VERSION "HNNBNNNYNNNNNNNNNNNNNNNNNNNNNNNNNNNNNNNNNN/4/%%%/4/'%**4NNN///"

NS_ :

BS_:

BU_: Frontradar Frontsensorik

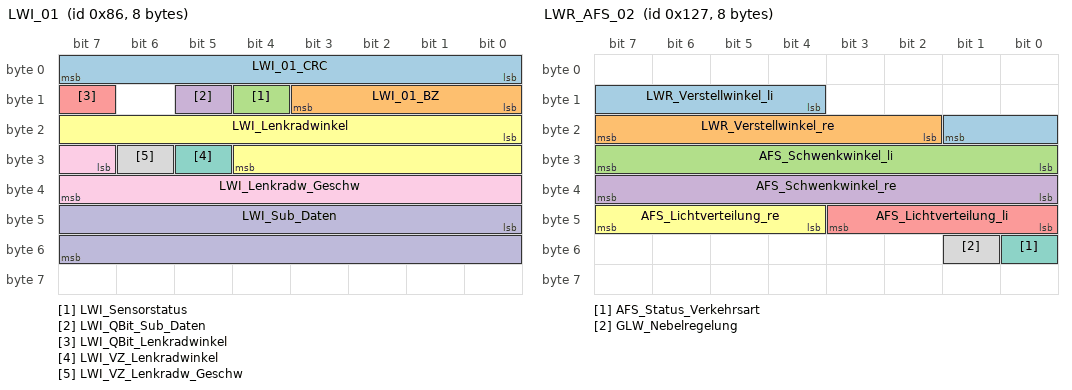
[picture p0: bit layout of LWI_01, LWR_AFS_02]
BO_ 134 LWI_01: 8 Vector__XXX
 SG_ LWI_01_CRC : 0|8@1+ (1,0) [0|255] ""  Frontradar,Frontsensorik
 SG_ LWI_01_BZ : 8|4@1+ (1,0) [0|15] ""  Frontradar,Frontsensorik
 SG_ LWI_Sensorstatus : 12|1@1+ (1,0) [0|1] ""  Frontradar,Frontsensorik
 SG_ LWI_QBit_Sub_Daten : 13|1@1+ (1,0) [0|1] "" Vector__XXX
 SG_ LWI_QBit_Lenkradwinkel : 15|1@1+ (1,0) [0|1] ""  Frontradar,Frontsensorik
 SG_ LWI_Lenkradwinkel : 16|13@1+ (0.1,0) [0|800] "Unit_DegreOfArc"  Frontradar,Frontsensorik
 SG_ LWI_VZ_Lenkradwinkel : 29|1@1+ (1,0) [0|1] ""  Frontradar,Frontsensorik
 SG_ LWI_VZ_Lenkradw_Geschw : 30|1@1+ (1,0) [0|1] ""  Frontradar
 SG_ LWI_Lenkradw_Geschw : 31|9@1+ (5,0) [0|2500] "Unit_DegreOfArcPerSecon"  Frontradar
 SG_ LWI_Sub_Daten : 40|16@1+ (1,0) [0|65535] "" Vector__XXX

BO_ 917 LWR_AFS_01: 8 Vector__XXX
 SG_ AFS_Abbiegelicht_li_Anf : 0|1@1+ (1,0) [0|1] "" Vector__XXX
 SG_ AFS_Abbiegelicht_re_Anf : 1|1@1+ (1,0) [0|1] "" Vector__XXX
 SG_ AFS_Abbiegelicht_Dimm_Anf : 2|1@1+ (1,0) [0|1] "" Vector__XXX
 SG_ AFS_Verfuegbarkeit_GLW : 3|1@1+ (1,0) [0|1] "" Vector__XXX
 SG_ AFS_Status_adaptive_LV : 4|1@1+ (1,0) [0|1] "" Vector__XXX
 SG_ AFS_Fernlicht_li_defekt : 5|1@1+ (1,0) [0|1] "" Vector__XXX
 SG_ AFS_Fernlicht_re_defekt : 6|1@1+ (1,0) [0|1] "" Vector__XXX
 SG_ AFS_Fernlicht_Status : 7|1@1+ (1,0) [0|1] "" Vector__XXX
 SG_ LWR_AFS_01_BZ : 8|4@1+ (1,0) [0|15] "" Vector__XXX
 SG_ AFS_Lampe : 12|1@1+ (1,0) [0|1] "" Vector__XXX
 SG_ LWR_Lampe : 13|1@1+ (1,0) [0|1] "" Vector__XXX
 SG_ AFS_Fehlertext : 14|1@1+ (1,0) [0|1] "" Vector__XXX
 SG_ AFS_LED_Blinkmode : 15|1@1+ (1,0) [0|1] "" Vector__XXX
 SG_ LWR_Touristenmodus_aktiv : 16|1@1+ (1,0) [0|1] "" Vector__XXX
 SG_ AFS_Charisma_FahrPr : 17|4@1+ (1,0) [0|15] "" Vector__XXX
 SG_ AFS_Charisma_Status : 21|2@1+ (1,0) [0|3] "" Vector__XXX
 SG_ AFS_Allwetterlicht : 24|1@1+ (1,0) [0|1] "" Vector__XXX
 SG_ LWR_Touristenmodus_verbaut : 25|1@1+ (1,0) [0|1] "" Vector__XXX
 SG_ AFS_adaptive_LV_verbaut : 26|1@1+ (1,0) [0|1] "" Vector__XXX
 SG_ LWR_Reisemodus_Texte : 27|2@1+ (1,0) [0|3] "" Vector__XXX
 SG_ GLW_Sensor_blockiert : 29|1@1+ (1,0) [0|1] "" Vector__XXX
 SG_ LWR_Pos_Schrittmotor : 32|8@1+ (0.4,0) [0|100] "Unit_PerCent" Vector__XXX
 SG_ LWR_Hoehenwert_VL : 40|8@1+ (1,-127) [-127|126] "" Vector__XXX
 SG_ LWR_Hoehenwert_HL : 48|8@1+ (1,-127) [-127|126] "" Vector__XXX
 SG_ AFS_Ersatzlicht_Links : 56|1@1+ (1,0) [0|1] "" Vector__XXX
 SG_ AFS_Ersatzlicht_Rechts : 57|1@1+ (1,0) [0|1] "" Vector__XXX
 SG_ LWR_AFS_Grundeinstellung : 58|1@1+ (1,0) [0|1] "" Vector__XXX
 SG_ LWR_AFS_Parametrisierung : 59|1@1+ (1,0) [0|1] "" Vector__XXX
 SG_ LWR_Initialisierungslauf : 60|1@1+ (1,0) [0|1] "" Vector__XXX
 SG_ LWR_Sicherheitsposition : 61|1@1+ (1,0) [0|1] "" Vector__XXX
 SG_ LWR_Modus : 62|1@1+ (1,0) [0|1] "" Vector__XXX

BO_ 295 LWR_AFS_02: 8 Vector__XXX
 SG_ LWR_Verstellwinkel_li : 12|6@1+ (0.125,-3) [-3|3] "Unit_DegreOfArc"  Frontsensorik
 SG_ LWR_Verstellwinkel_re : 18|6@1+ (0.125,-3) [-3|3] "Unit_DegreOfArc"  Frontsensorik
 SG_ AFS_Schwenkwinkel_li : 24|8@1+ (0.125,-7.5) [-7.5|15] "Unit_DegreOfArc"  Frontsensorik
 SG_ AFS_Schwenkwinkel_re : 32|8@1+ (0.125,-15) [-15|7.5] "Unit_DegreOfArc"  Frontsensorik
 SG_ AFS_Lichtverteilung_li : 40|4@1+ (1,0) [0|15] ""  Frontsensorik
 SG_ AFS_Lichtverteilung_re : 44|4@1+ (1,0) [0|15] ""  Frontsensorik
 SG_ AFS_Status_Verkehrsart : 48|1@1+ (1,0) [0|1] ""  Frontsensorik
 SG_ GLW_Nebelregelung : 49|1@1+ (1,0) [0|1] ""  Frontsensorik

BO_ 846 LWR_AFS_03: 8 Vector__XXX
 SG_ MXB_Status_Seg01 : 0|2@1+ (1,0) [0|3] ""  Frontsensorik
 SG_ MXB_Status_Seg02 : 2|2@1+ (1,0) [0|3] ""  Frontsensorik
 SG_ MXB_Status_Seg03 : 4|2@1+ (1,0) [0|3] ""  Frontsensorik
 SG_ MXB_Status_Seg04 : 6|2@1+ (1,0) [0|3] ""  Frontsensorik
 SG_ MXB_Status_Seg05 : 8|2@1+ (1,0) [0|3] ""  Frontsensorik
 SG_ MXB_Status_Seg06 : 10|2@1+ (1,0) [0|3] ""  Frontsensorik
 SG_ MXB_Status_Seg07 : 12|2@1+ (1,0) [0|3] ""  Frontsensorik
 SG_ MXB_Status_Seg08 : 14|2@1+ (1,0) [0|3] ""  Frontsensorik
 SG_ MXB_Status_Seg09 : 16|2@1+ (1,0) [0|3] ""  Frontsensorik
 SG_ MXB_Status_Seg10 : 18|2@1+ (1,0) [0|3] ""  Frontsensorik
 SG_ MXB_Status_Seg11 : 20|2@1+ (1,0) [0|3] ""  Frontsensorik
 SG_ MXB_Status_Seg12 : 22|2@1+ (1,0) [0|3] ""  Frontsensorik
 SG_ MXB_Status_Seg13 : 24|2@1+ (1,0) [0|3] ""  Frontsensorik
 SG_ MXB_Status_Seg14 : 26|2@1+ (1,0) [0|3] ""  Frontsensorik
 SG_ MXB_Status_Seg15 : 28|2@1+ (1,0) [0|3] ""  Frontsensorik
 SG_ MXB_Status_Seg16 : 30|2@1+ (1,0) [0|3] ""  Frontsensorik
 SG_ MXB_Status_Seg17 : 32|2@1+ (1,0) [0|3] ""  Frontsensorik
 SG_ MXB_Status_Seg18 : 34|2@1+ (1,0) [0|3] ""  Frontsensorik
 SG_ MXB_Status_Seg19 : 36|2@1+ (1,0) [0|3] ""  Frontsensorik
 SG_ MXB_Status_Seg20 : 38|2@1+ (1,0) [0|3] ""  Frontsensorik
 SG_ MXB_Status_Seg21 : 40|2@1+ (1,0) [0|3] ""  Frontsensorik
 SG_ MXB_Status_Seg22 : 42|2@1+ (1,0) [0|3] ""  Frontsensorik
 SG_ MXB_Status_Seg23 : 44|2@1+ (1,0) [0|3] ""  Frontsensorik
 SG_ MXB_Status_Seg24 : 46|2@1+ (1,0) [0|3] ""  Frontsensorik
 SG_ MXB_Status_Seg25 : 48|2@1+ (1,0) [0|3] ""  Frontsensorik
 SG_ MXB_Status_Seg26 : 50|2@1+ (1,0) [0|3] ""  Frontsensorik
 SG_ MXB_Status_Seg27 : 52|2@1+ (1,0) [0|3] ""  Frontsensorik
 SG_ MXB_Status_Seg28 : 54|2@1+ (1,0) [0|3] ""  Frontsensorik
 SG_ MXB_Status_Seg29 : 56|2@1+ (1,0) [0|3] ""  Frontsensorik
 SG_ MXB_Status_Seg30 : 58|2@1+ (1,0) [0|3] ""  Frontsensorik
 SG_ MXB_Status_Seg31 : 60|2@1+ (1,0) [0|3] ""  Frontsensorik
 SG_ MXB_Status_Seg32 : 62|2@1+ (1,0) [0|3] ""  Frontsensorik

BO_ 847 LWR_AFS_04: 8 Vector__XXX
 SG_ MXB_Status_Seg33 : 0|2@1+ (1,0) [0|3] ""  Frontsensorik
 SG_ MXB_Status_Seg34 : 2|2@1+ (1,0) [0|3] ""  Frontsensorik
 SG_ MXB_Status_Seg35 : 4|2@1+ (1,0) [0|3] ""  Frontsensorik
 SG_ MXB_Status_Seg36 : 6|2@1+ (1,0) [0|3] ""  Frontsensorik
 SG_ MXB_Status_Seg37 : 8|2@1+ (1,0) [0|3] ""  Frontsensorik
 SG_ MXB_Status_Seg38 : 10|2@1+ (1,0) [0|3] ""  Frontsensorik
 SG_ MXB_Status_Seg39 : 12|2@1+ (1,0) [0|3] ""  Frontsensorik
 SG_ MXB_Status_Seg40 : 14|2@1+ (1,0) [0|3] ""  Frontsensorik
 SG_ MXB_Status_Seg41 : 16|2@1+ (1,0) [0|3] ""  Frontsensorik
 SG_ MXB_Status_Seg42 : 18|2@1+ (1,0) [0|3] ""  Frontsensorik
 SG_ MXB_Status_Seg43 : 20|2@1+ (1,0) [0|3] ""  Frontsensorik
 SG_ MXB_Status_Seg44 : 22|2@1+ (1,0) [0|3] ""  Frontsensorik
 SG_ MXB_Status_Seg45 : 24|2@1+ (1,0) [0|3] ""  Frontsensorik
 SG_ MXB_Status_Seg46 : 26|2@1+ (1,0) [0|3] ""  Frontsensorik
 SG_ MXB_Status_Seg47 : 28|2@1+ (1,0) [0|3] ""  Frontsensorik
 SG_ MXB_Status_Seg48 : 30|2@1+ (1,0) [0|3] ""  Frontsensorik
 SG_ MXB_Status_Seg49 : 32|2@1+ (1,0) [0|3] ""  Frontsensorik
 SG_ MXB_Status_Seg50 : 34|2@1+ (1,0) [0|3] ""  Frontsensorik
 SG_ MXB_Status_Seg51 : 36|2@1+ (1,0) [0|3] ""  Frontsensorik
 SG_ MXB_Status_Seg52 : 38|2@1+ (1,0) [0|3] ""  Frontsensorik
 SG_ MXB_Status_Seg53 : 40|2@1+ (1,0) [0|3] ""  Frontsensorik
 SG_ MXB_Status_Seg54 : 42|2@1+ (1,0) [0|3] ""  Frontsensorik
 SG_ MXB_Status_Seg55 : 44|2@1+ (1,0) [0|3] ""  Frontsensorik
 SG_ MXB_Status_Seg56 : 46|2@1+ (1,0) [0|3] ""  Frontsensorik
 SG_ MXB_Status_Seg57 : 48|2@1+ (1,0) [0|3] ""  Frontsensorik
 SG_ MXB_Status_Seg58 : 50|2@1+ (1,0) [0|3] ""  Frontsensorik
 SG_ MXB_Status_Seg59 : 52|2@1+ (1,0) [0|3] ""  Frontsensorik
 SG_ MXB_Status_Seg60 : 54|2@1+ (1,0) [0|3] ""  Frontsensorik

BO_ 1721 LWR_AFS_05: 8 Vector__XXX
 SG_ MXB_horiz_Offset_li_SW : 0|7@1+ (0.05,-3.15) [-3.15|3.2] "Unit_DegreOfArc"  Frontsensorik
 SG_ MXB_Status : 7|2@1+ (1,0) [0|3] ""  Frontsensorik
 SG_ MXB_vert_Offset_li_SW : 9|7@1+ (0.05,-3.15) [-3.15|3.2] "Unit_DegreOfArc"  Frontsensorik
 SG_ AFS_Abblendlicht_li_defekt : 16|1@1+ (1,0) [0|1] "" Vector__XXX
 SG_ AFS_Abblendlicht_re_defekt : 17|1@1+ (1,0) [0|1] "" Vector__XXX
 SG_ AFS_stat_Kurvenlicht_li_defekt : 18|1@1+ (1,0) [0|1] "" Vector__XXX
 SG_ AFS_stat_Kurvenlicht_re_defekt : 19|1@1+ (1,0) [0|1] "" Vector__XXX
 SG_ AFS_Tagfahrlicht_li_defekt : 20|1@1+ (1,0) [0|1] "" Vector__XXX
 SG_ AFS_Tagfahrlicht_re_defekt : 21|1@1+ (1,0) [0|1] "" Vector__XXX
 SG_ MXB_Allgemein_li_defekt : 22|1@1+ (1,0) [0|1] "" Vector__XXX
 SG_ MXB_Allgemein_re_defekt : 23|1@1+ (1,0) [0|1] "" Vector__XXX
 SG_ AFS_Zusatzfernlicht_li_defekt : 24|1@1+ (1,0) [0|1] "" Vector__XXX
 SG_ AFS_Zusatzfernlicht_re_defekt : 25|1@1+ (1,0) [0|1] "" Vector__XXX
 SG_ LED_Steuerung_li_defekt : 26|1@1+ (1,0) [0|1] "" Vector__XXX
 SG_ LED_Steuerung_re_defekt : 27|1@1+ (1,0) [0|1] "" Vector__XXX
 SG_ MXB_horiz_Offset_re_SW : 28|7@1+ (0.05,-3.15) [-3.15|3.2] "Unit_DegreOfArc"  Frontsensorik
 SG_ MXB_vert_Offset_re_SW : 35|7@1+ (0.05,-3.15) [-3.15|3.2] "Unit_DegreOfArc"  Frontsensorik

BO_ 506 LWR_AFS_08: 8 Vector__XXX
 SG_ LCM_TFL_Fehler_L : 12|1@1+ (1,0) [0|1] "" Vector__XXX
 SG_ LCM_TFL_Fehler_R : 13|1@1+ (1,0) [0|1] "" Vector__XXX
 SG_ LCM_SM_Fehler_L : 14|1@1+ (1,0) [0|1] "" Vector__XXX
 SG_ LCM_SM_Fehler_R : 15|1@1+ (1,0) [0|1] "" Vector__XXX
 SG_ LCM_Shutter_Fehler_L : 16|1@1+ (1,0) [0|1] "" Vector__XXX
 SG_ LCM_Shutter_Fehler_R : 17|1@1+ (1,0) [0|1] "" Vector__XXX
 SG_ LCM_PO_Fehler_L : 18|1@1+ (1,0) [0|1] "" Vector__XXX
 SG_ LCM_PO_Fehler_R : 19|1@1+ (1,0) [0|1] "" Vector__XXX
 SG_ LCM_Blinker_Fehler_L : 20|1@1+ (1,0) [0|1] "" Vector__XXX
 SG_ LCM_Blinker_Fehler_R : 21|1@1+ (1,0) [0|1] "" Vector__XXX
 SG_ LCM_Blinker_L_Sta : 22|1@1+ (1,0) [0|1] "" Vector__XXX
 SG_ LCM_Blinker_R_Sta : 23|1@1+ (1,0) [0|1] "" Vector__XXX
 SG_ LCM_Datensatz_Fehler_L : 24|1@1+ (1,0) [0|1] "" Vector__XXX
 SG_ LCM_Datensatz_Fehler_R : 25|1@1+ (1,0) [0|1] "" Vector__XXX
 SG_ LCM_Abschaltbestaetigung_L : 26|2@1+ (1,0) [0|3] "" Vector__XXX
 SG_ LCM_Abschaltbestaetigung_R : 28|2@1+ (1,0) [0|3] "" Vector__XXX
 SG_ LCM_Sta_LM_L_alt : 60|1@1+ (1,0) [0|1] "" Vector__XXX
 SG_ LCM_Sta_LM_R_alt : 61|1@1+ (1,0) [0|1] "" Vector__XXX
 SG_ LCM_Feh_LM_L_alt : 62|1@1+ (1,0) [0|1] "" Vector__XXX
 SG_ LCM_Feh_LM_R_alt : 63|1@1+ (1,0) [0|1] "" Vector__XXX

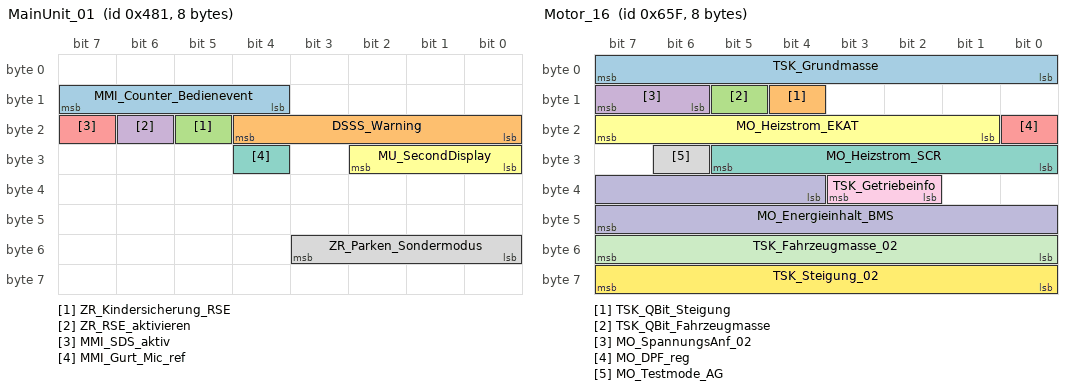
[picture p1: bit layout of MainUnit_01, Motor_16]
BO_ 1153 MainUnit_01: 8 Vector__XXX
 SG_ MMI_Counter_Bedienevent : 12|4@1+ (1,0) [0|15] ""  Frontsensorik
 SG_ DSSS_Warning : 16|5@1+ (1,0) [0|31] "" Vector__XXX
 SG_ ZR_Kindersicherung_RSE : 21|1@1+ (1,0) [0|1] "" Vector__XXX
 SG_ ZR_RSE_aktivieren : 22|1@1+ (1,0) [0|1] "" Vector__XXX
 SG_ MMI_SDS_aktiv : 23|1@1+ (1,0) [0|1] "" Vector__XXX
 SG_ MU_SecondDisplay : 24|3@1+ (1,0) [0|7] "" Vector__XXX
 SG_ MMI_Gurt_Mic_ref : 28|1@1+ (1,0) [0|1] "" Vector__XXX
 SG_ ZR_Parken_Sondermodus : 48|4@1+ (1,0) [0|15] "" Vector__XXX

BO_ 1600 Motor_07: 8 Vector__XXX
 SG_ MO_QBit_Ansaugluft_Temp : 0|1@1+ (1,0) [0|1] "" Vector__XXX
 SG_ MO_QBit_Oel_Temp : 1|1@1+ (1,0) [0|1] "" Vector__XXX
 SG_ MO_QBit_Kuehlmittel_Temp : 2|1@1+ (1,0) [0|1] "" Vector__XXX
 SG_ MO_KL15_Abschaltempfehlung : 3|1@1+ (1,0) [0|1] "" Vector__XXX
 SG_ MO_HYB_Fehler_HV_Netz : 4|1@1+ (1,0) [0|1] "" Vector__XXX
 SG_ MO_aktives_Getriebeheizen : 5|1@1+ (1,0) [0|1] "" Vector__XXX
 SG_ MO_Absperrventil_oeffnen : 6|2@1+ (1,0) [0|3] "" Vector__XXX
 SG_ MO_Ansaugluft_Temp : 8|8@1+ (0.75,-48) [-48|141.75] "Unit_DegreCelsi" Vector__XXX
 SG_ MO_Oel_Temp : 16|8@1+ (1,-60) [-60|192] "Unit_DegreCelsi" Vector__XXX
 SG_ MO_Kuehlmittel_Temp : 24|8@1+ (0.75,-48) [-48|141.75] "Unit_DegreCelsi" Vector__XXX
 SG_ MO_Hoeheninfo : 32|8@1+ (0.00781,0) [0|1.98374] "" Vector__XXX
 SG_ MO_Kennfeldk : 40|1@1+ (1,0) [0|1] "" Vector__XXX
 SG_ MO_Versionsinfo_02 : 41|5@1+ (1,0) [0|31] "" Vector__XXX
 SG_ MO_QBit_Hoeheninfo : 46|1@1+ (1,0) [0|1] "" Vector__XXX
 SG_ MO_Getriebe_kuehlen : 47|1@1+ (1,0) [0|1] "" Vector__XXX
 SG_ MO_Mom_Traegheit_02 : 48|5@1+ (0.01,0) [0|0.31] "Unit_KiloGramMeterSquar" Vector__XXX
 SG_ MO_Heizungspumpenansteuerung : 53|4@1+ (10,0) [0|100] "Unit_PerCent" Vector__XXX
 SG_ MO_SpannungsAnf : 57|1@1+ (1,0) [0|1] "" Vector__XXX
 SG_ MO_Nachlaufzeit_Heizungspumpe : 58|6@1+ (15,0) [0|945] "Unit_Secon" Vector__XXX

BO_ 958 Motor_14: 8 Vector__XXX
 SG_ Motor_14_CRC : 0|8@1+ (1,0) [0|255] "" Vector__XXX
 SG_ Motor_14_BZ : 8|4@1+ (1,0) [0|15] "" Vector__XXX
 SG_ MO_StartStopp_Status : 12|2@1+ (1,0) [0|3] ""  Frontradar
 SG_ MO_StartStopp_Wiederstart : 14|1@1+ (1,0) [0|1] ""  Frontradar
 SG_ MO_StartStopp_Motorstopp : 15|1@1+ (1,0) [0|1] ""  Frontradar
 SG_ MO_Freig_Reku : 16|2@1+ (1,0) [0|3] "" Vector__XXX
 SG_ MO_Kl_75 : 18|1@1+ (1,0) [0|1] ""  Frontradar
 SG_ MO_Kl_50 : 19|1@1+ (1,0) [0|1] ""  Frontradar
 SG_ MO_Gangposition : 20|4@1+ (1,0) [0|15] ""  Frontradar
 SG_ MO_StartStopp_Fahrerwunsch : 24|2@1+ (1,0) [0|3] "" Vector__XXX
 SG_ MO_HYB_Fahrbereitschaft : 26|1@1+ (1,0) [0|1] "" Vector__XXX
 SG_ MO_Ext_E_Fahrt_aktiv : 27|1@1+ (1,0) [0|1] ""  Frontradar
 SG_ MO_Fahrer_bremst : 28|1@1+ (1,0) [0|1] ""  Frontradar
 SG_ MO_QBit_Fahrer_bremst : 29|1@1+ (1,0) [0|1] ""  Frontradar
 SG_ MO_BLS : 30|1@1+ (1,0) [0|1] ""  Frontradar
 SG_ MO_Konsistenz_Bremsped : 31|1@1+ (1,0) [0|1] "" Vector__XXX
 SG_ MO_Timeout_ESP : 32|1@1+ (1,0) [0|1] "" Vector__XXX
 SG_ MO_Klima_Eingr : 33|2@1+ (1,0) [0|3] "" Vector__XXX
 SG_ MO_Aussp_Anlass : 35|1@1+ (1,0) [0|1] "" Vector__XXX
 SG_ MO_Freig_Anlass : 36|1@1+ (1,0) [0|1] "" Vector__XXX
 SG_ MO_Kuppl_schalter : 37|1@1+ (1,0) [0|1] ""  Frontradar
 SG_ MO_Interlock : 38|1@1+ (1,0) [0|1] "" Vector__XXX
 SG_ MO_Motor_laeuft : 39|1@1+ (1,0) [0|1] ""  Frontsensorik
 SG_ MO_Kickdown : 40|1@1+ (1,0) [0|1] "" Vector__XXX
 SG_ MO_QBit_KL_75 : 41|1@1+ (1,0) [0|1] "" Vector__XXX
 SG_ MO_EKlKomLeiRed : 42|2@1+ (1,0) [0|3] "" Vector__XXX
 SG_ MO_Handshake_STH : 44|1@1+ (1,0) [0|1] "" Vector__XXX
 SG_ MO_BKV_Unterdruckwarnung : 45|1@1+ (1,0) [0|1] "" Vector__XXX
 SG_ MO_Freigabe_Segeln : 46|1@1+ (1,0) [0|1] "" Vector__XXX
 SG_ MO_PTC_Status : 47|3@1+ (1,0) [0|7] "" Vector__XXX
 SG_ MO_QBit_Gangposition : 50|1@1+ (1,0) [0|1] ""  Frontradar
 SG_ MO_Signalquelle_Gangposition : 51|1@1+ (1,0) [0|1] "" Vector__XXX
 SG_ MO_Remotestart_Betrieb : 52|1@1+ (1,0) [0|1] "" Vector__XXX
 SG_ MO_Remotestart_moeglich : 53|1@1+ (1,0) [0|1] "" Vector__XXX
 SG_ MO_FMAus_aktiv : 55|1@1+ (1,0) [0|1] "" Vector__XXX
 SG_ MO_FMAus_Startvariante : 56|2@1+ (1,0) [0|3] "" Vector__XXX
 SG_ MO_BMS_NV_Anf_stuetzen : 58|1@1+ (1,0) [0|1] "" Vector__XXX
 SG_ MO_Zylinderabschaltung : 59|2@1+ (1,0) [0|3] "" Vector__XXX
 SG_ MO_HYB_VM_aktiv : 61|1@1+ (1,0) [0|1] "" Vector__XXX
 SG_ MO_StartVorauss_erfuellt : 62|2@1+ (1,0) [0|3] "" Vector__XXX

BO_ 1631 Motor_16: 8 Vector__XXX
 SG_ TSK_Grundmasse : 0|8@1+ (32,0) [0|8128] "Unit_KiloGram" Vector__XXX
 SG_ TSK_QBit_Steigung : 12|1@1+ (1,0) [0|1] ""  Frontradar
 SG_ TSK_QBit_Fahrzeugmasse : 13|1@1+ (1,0) [0|1] "" Vector__XXX
 SG_ MO_SpannungsAnf_02 : 14|2@1+ (1,0) [0|3] "" Vector__XXX
 SG_ MO_DPF_reg : 16|1@1+ (1,0) [0|1] "" Vector__XXX
 SG_ MO_Heizstrom_EKAT : 17|7@1+ (1,0) [0|126] "Unit_Amper" Vector__XXX
 SG_ MO_Heizstrom_SCR : 24|6@1+ (1,0) [0|62] "Unit_Amper" Vector__XXX
 SG_ MO_Testmode_AG : 30|1@1+ (1,0) [0|1] "" Vector__XXX
 SG_ TSK_Getriebeinfo : 34|2@1+ (1,0) [0|3] "" Vector__XXX
 SG_ MO_Energieinhalt_BMS : 36|12@1+ (25,0) [0|102325] "Unit_WattHour" Vector__XXX
 SG_ TSK_Fahrzeugmasse_02 : 48|8@1+ (32,0) [0|8128] "Unit_KiloGram"  Frontradar
 SG_ TSK_Steigung_02 : 56|8@1+ (0.8,-101.6) [-100.8|101.6] "Unit_PerCent"  Frontradar

BO_ 1648 Motor_18: 8 Vector__XXX
 SG_ MO_max_Ladedruck : 0|6@1+ (0.1,0) [0|6.3] "Unit_Bar" Vector__XXX
 SG_ MO_ANC_Kennfeld_Anf : 6|2@1+ (1,0) [0|3] "" Vector__XXX
 SG_ MO_Bremslicht_Reku : 8|1@1+ (1,0) [0|1] ""  Frontradar
 SG_ MO_StartStopp_PopUp : 9|2@1+ (1,0) [0|3] "" Vector__XXX
 SG_ MO1_Sperr_Info_WFS : 11|1@1+ (1,0) [0|1] "" Vector__XXX
 SG_ MO1_Freigabe_Info_WFS : 12|1@1+ (1,0) [0|1] "" Vector__XXX
 SG_ MO_EPCL : 13|3@1+ (1,0) [0|7] "" Vector__XXX
 SG_ MO_Zylabsch_Texte_02 : 16|4@1+ (1,0) [0|15] "" Vector__XXX
 SG_ MO_Fahrzeugtyp : 20|3@1+ (1,0) [0|7] ""  Frontradar
 SG_ MO_NMAX_Schaltanzeige : 23|9@1+ (25,0) [0|12775] "Unit_MinutInver" Vector__XXX
 SG_ MO_Abstellzeit : 32|8@1+ (8,0) [0|2024] "Unit_Minut" Vector__XXX
 SG_ MO_Abstellzeit_Status : 40|2@1+ (1,0) [0|3] "" Vector__XXX
 SG_ MO1_Freigabe_Verfallsinfo_WFS : 42|1@1+ (1,0) [0|1] "" Vector__XXX
 SG_ MO_Hybrid_StartStopp_LED : 43|2@1+ (1,0) [0|3] "" Vector__XXX
 SG_ MO_Fehler_Zylabsch : 45|2@1+ (1,0) [0|3] "" Vector__XXX
 SG_ MO_Anzahl_Abgesch_Zyl : 47|3@1+ (1,0) [0|7] "" Vector__XXX
 SG_ MO_Zylabsch_Texte : 50|2@1+ (1,0) [0|3] "" Vector__XXX
 SG_ MO_Ethanol_BS_Texte : 52|3@1+ (1,0) [0|7] "" Vector__XXX
 SG_ MO_Drehzahl_Warnung : 55|1@1+ (1,0) [0|1] "" Vector__XXX
 SG_ MO_obere_Drehzahlgrenze : 56|8@1+ (50,0) [50|12750] "Unit_MinutInver"  Frontradar

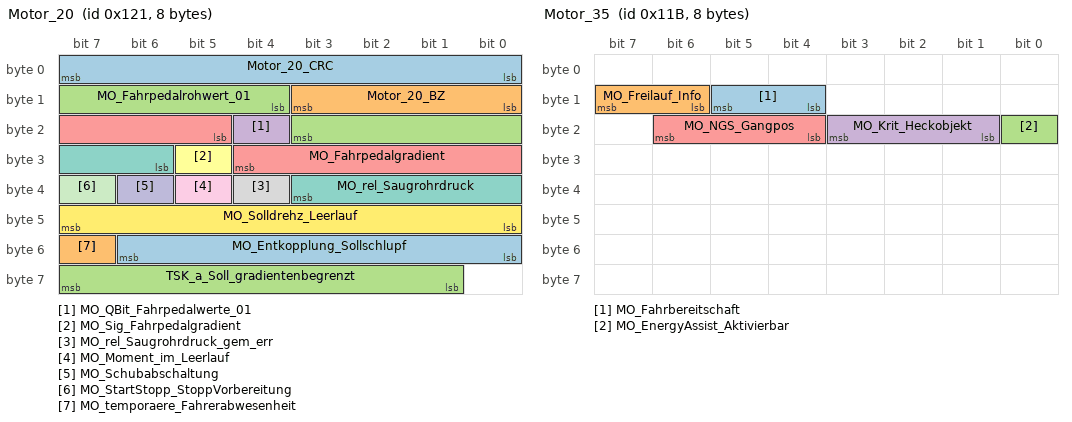
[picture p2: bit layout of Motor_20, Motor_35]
BO_ 289 Motor_20: 8 Vector__XXX
 SG_ Motor_20_CRC : 0|8@1+ (1,0) [0|255] ""  Frontradar
 SG_ Motor_20_BZ : 8|4@1+ (1,0) [0|15] ""  Frontradar
 SG_ MO_Fahrpedalrohwert_01 : 12|8@1+ (0.4,0) [0|101.6] "Unit_PerCent"  Frontradar
 SG_ MO_QBit_Fahrpedalwerte_01 : 20|1@1+ (1,0) [0|1] ""  Frontradar
 SG_ MO_Fahrpedalgradient : 21|8@1+ (25,0) [0|6350] "Unit_PerCentPerSecon" Vector__XXX
 SG_ MO_Sig_Fahrpedalgradient : 29|1@1+ (1,0) [0|1] ""  Frontradar
 SG_ MO_rel_Saugrohrdruck : 30|6@1+ (18,0) [0|1116] "Unit_MilliBar" Vector__XXX
 SG_ MO_rel_Saugrohrdruck_gem_err : 36|1@1+ (1,0) [0|1] "" Vector__XXX
 SG_ MO_Moment_im_Leerlauf : 37|1@1+ (1,0) [0|1] "" Vector__XXX
 SG_ MO_Schubabschaltung : 38|1@1+ (1,0) [0|1] "" Vector__XXX
 SG_ MO_StartStopp_StoppVorbereitung : 39|1@1+ (1,0) [0|1] "" Vector__XXX
 SG_ MO_Solldrehz_Leerlauf : 40|8@1+ (10,0) [0|2540] "Unit_MinutInver"  Frontradar
 SG_ MO_Entkopplung_Sollschlupf : 48|7@1+ (20,0) [0|2480] "Unit_MinutInver" Vector__XXX
 SG_ MO_temporaere_Fahrerabwesenheit : 55|1@1+ (1,0) [0|1] "" Vector__XXX
 SG_ TSK_a_Soll_gradientenbegrenzt : 57|7@1+ (0.1,-7.2) [-7.2|5.4] "Unit_MeterPerSeconSquar"  Frontradar

BO_ 283 Motor_35: 8 Vector__XXX
 SG_ MO_Fahrbereitschaft : 12|2@1+ (1,0) [0|3] ""  Frontradar
 SG_ MO_Freilauf_Info : 14|2@1+ (1,0) [0|3] "" Vector__XXX
 SG_ MO_EnergyAssist_Aktivierbar : 16|1@1+ (1,0) [0|1] "" Vector__XXX
 SG_ MO_Krit_Heckobjekt : 17|3@1+ (1,0) [0|7] "" Vector__XXX
 SG_ MO_NGS_Gangpos : 20|3@1+ (1,0) [0|7] "" Vector__XXX

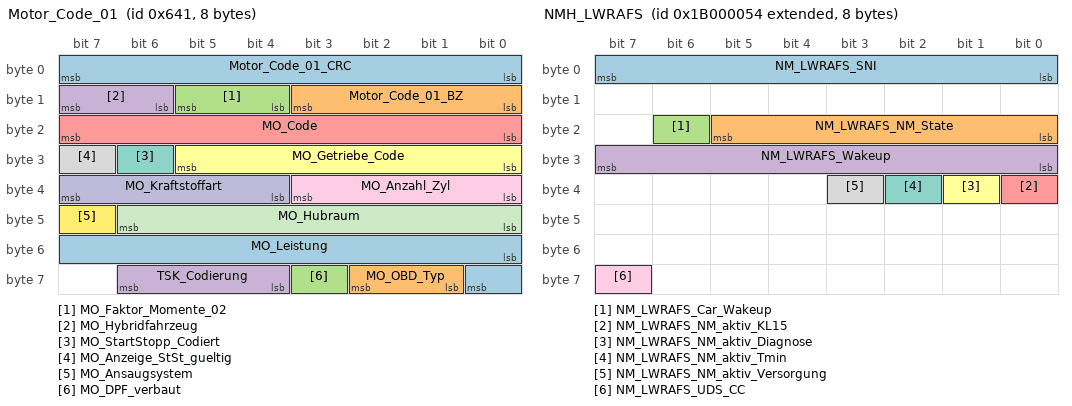
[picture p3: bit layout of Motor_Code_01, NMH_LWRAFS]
BO_ 1601 Motor_Code_01: 8 Vector__XXX
 SG_ Motor_Code_01_CRC : 0|8@1+ (1,0) [0|255] ""  Frontradar
 SG_ Motor_Code_01_BZ : 8|4@1+ (1,0) [0|15] ""  Frontradar
 SG_ MO_Faktor_Momente_02 : 12|2@1+ (1,0) [1|3] "Unit_NewtoMeter" Vector__XXX
 SG_ MO_Hybridfahrzeug : 14|2@1+ (1,0) [0|3] "" Vector__XXX
 SG_ MO_Code : 16|8@1+ (1,0) [0|255] "" Vector__XXX
 SG_ MO_Getriebe_Code : 24|6@1+ (1,0) [0|63] "" Vector__XXX
 SG_ MO_StartStopp_Codiert : 30|1@1+ (1,0) [0|1] "" Vector__XXX
 SG_ MO_Anzeige_StSt_gueltig : 31|1@1+ (1,0) [0|1] "" Vector__XXX
 SG_ MO_Anzahl_Zyl : 32|4@1+ (1,0) [0|15] "" Vector__XXX
 SG_ MO_Kraftstoffart : 36|4@1+ (1,0) [0|15] "" Vector__XXX
 SG_ MO_Hubraum : 40|7@1+ (0.1,0) [0|12.7] "Unit_Liter" Vector__XXX
 SG_ MO_Ansaugsystem : 47|1@1+ (1,0) [0|1] "" Vector__XXX
 SG_ MO_Leistung : 48|9@1+ (1,0) [0|511] "Unit_KiloWatt"  Frontradar
 SG_ MO_OBD_Typ : 57|2@1+ (1,0) [0|3] "" Vector__XXX
 SG_ MO_DPF_verbaut : 59|1@1+ (1,0) [0|1] "" Vector__XXX
 SG_ TSK_Codierung : 60|3@1+ (1,0) [0|7] ""  Frontradar

BO_ 2600468496 NMH_Gateway: 8 Vector__XXX
 SG_ NM_Gateway_SNI : 0|8@1+ (1,0) [0|255] "" Vector__XXX
 SG_ NM_Gateway_NM_State : 16|6@1+ (1,0) [0|63] "" Vector__XXX
 SG_ NM_Gateway_Car_Wakeup : 22|1@1+ (1,0) [0|1] "" Vector__XXX
 SG_ NM_Gateway_Wakeup : 24|8@1+ (1,0) [0|255] "" Vector__XXX
 SG_ NM_Gateway_NM_aktiv_KL15 : 32|1@1+ (1,0) [0|1] "" Vector__XXX
 SG_ NM_Gateway_NM_aktiv_Diagnose : 33|1@1+ (1,0) [0|1] "" Vector__XXX
 SG_ NM_Gateway_NM_aktiv_Tmin : 34|1@1+ (1,0) [0|1] "" Vector__XXX
 SG_ NM_Gateway_ACAN_Aktivitaet : 35|1@1+ (1,0) [0|1] "" Vector__XXX
 SG_ NM_Gateway_FCAN_Aktivitaet : 36|1@1+ (1,0) [0|1] "" Vector__XXX
 SG_ NM_Gateway_KCAN_Aktivitaet : 37|1@1+ (1,0) [0|1] "" Vector__XXX
 SG_ NM_Gateway_ICAN_Aktivitaet : 38|1@1+ (1,0) [0|1] "" Vector__XXX
 SG_ NM_Gateway_DiagCAN_Aktivitaet : 39|1@1+ (1,0) [0|1] "" Vector__XXX
 SG_ NM_Gateway_ECAN_Aktivitaet : 40|1@1+ (1,0) [0|1] "" Vector__XXX
 SG_ NM_Gateway_EnergieLIN_Aktivitaet : 41|1@1+ (1,0) [0|1] "" Vector__XXX
 SG_ NM_Gateway_Bedien_LIN_Aktivitaet : 42|1@1+ (1,0) [0|1] "" Vector__XXX
 SG_ NM_Gateway_EM_Aktivitaet : 43|1@1+ (1,0) [0|1] "" Vector__XXX
 SG_ NM_Gateway_KS_Aktivitaet : 44|1@1+ (1,0) [0|1] "" Vector__XXX
 SG_ NM_Gateway_HVEM_aktiv : 45|1@1+ (1,0) [0|1] "" Vector__XXX
 SG_ NM_Gateway_NL_EM : 48|1@1+ (1,0) [0|1] "" Vector__XXX
 SG_ NM_Gateway_NL_Shutdown : 49|1@1+ (1,0) [0|1] "" Vector__XXX
 SG_ NM_Gateway_NL_Spg_Messung : 50|1@1+ (1,0) [0|1] "" Vector__XXX
 SG_ NM_Gateway_NL_Wakeup_Monitor : 51|1@1+ (1,0) [0|1] "" Vector__XXX
 SG_ NM_Gateway_UDS_CC : 63|1@1+ (1,0) [0|1] "" Vector__XXX

BO_ 2600468564 NMH_LWRAFS: 8 Vector__XXX
 SG_ NM_LWRAFS_SNI : 0|8@1+ (1,0) [0|255] "" Vector__XXX
 SG_ NM_LWRAFS_NM_State : 16|6@1+ (1,0) [0|63] "" Vector__XXX
 SG_ NM_LWRAFS_Car_Wakeup : 22|1@1+ (1,0) [0|1] "" Vector__XXX
 SG_ NM_LWRAFS_Wakeup : 24|8@1+ (1,0) [0|255] "" Vector__XXX
 SG_ NM_LWRAFS_NM_aktiv_KL15 : 32|1@1+ (1,0) [0|1] "" Vector__XXX
 SG_ NM_LWRAFS_NM_aktiv_Diagnose : 33|1@1+ (1,0) [0|1] "" Vector__XXX
 SG_ NM_LWRAFS_NM_aktiv_Tmin : 34|1@1+ (1,0) [0|1] "" Vector__XXX
 SG_ NM_LWRAFS_NM_aktiv_Versorgung : 35|1@1+ (1,0) [0|1] "" Vector__XXX
 SG_ NM_LWRAFS_UDS_CC : 63|1@1+ (1,0) [0|1] "" Vector__XXX

BO_ 2549875287 OBDC_ACC_Req: 8 Vector__XXX
 SG_ OBDC_ACC_Req_Data : 0|64@1+ (1,0) [0|1.84467440737096E+019] ""  Frontradar

BO_ 2550006359 OBDC_ACC_Resp: 8 Frontradar
 SG_ OBDC_ACC_Resp_Data : 0|64@1+ (1,0) [0|1.84467440737096E+019] "" Vector__XXX

BO_ 2549875248 OBDC_FLA_Req: 8 Vector__XXX
 SG_ OBDC_FLA_Req_Data : 0|64@1+ (1,0) [0|1.84467440737096E+019] "" Vector__XXX

BO_ 2550006320 OBDC_FLA_Resp: 8 Vector__XXX
 SG_ OBDC_FLA_Resp_Data : 0|64@1+ (1,0) [0|1.84467440737096E+019] "" Vector__XXX

BO_ 2549875279 OBDC_Kamera_Req: 8 Vector__XXX
 SG_ OBDC_Kamera_ReqData : 0|64@1+ (1,0) [0|1.84467440737096E+019] "" Vector__XXX

BO_ 2550006351 OBDC_Kamera_Resp: 8 Vector__XXX
 SG_ OBDC_Kamera_Resp_Data : 0|64@1+ (1,0) [0|1.84467440737096E+019] "" Vector__XXX

BO_ 2549875330 OBDC_LCM_L_Req: 8 Vector__XXX
 SG_ OBDC_LCM_L_Req_Data : 0|64@1+ (1,0) [0|1.84467440737096E+019] "" Vector__XXX

BO_ 2550006402 OBDC_LCM_L_Resp: 8 Vector__XXX
 SG_ OBDC_LCM_L_Resp_Data : 0|64@1+ (1,0) [0|1.84467440737096E+019] "" Vector__XXX

BO_ 2549875331 OBDC_LCM_R_Req: 8 Vector__XXX
 SG_ OBDC_LCM_R_Req_Data : 0|64@1+ (1,0) [0|1.84467440737096E+019] "" Vector__XXX

BO_ 2550006403 OBDC_LCM_R_Resp: 8 Vector__XXX
 SG_ OBDC_LCM_R_Resp_Data : 0|64@1+ (1,0) [0|1.84467440737096E+019] "" Vector__XXX

BO_ 2549875350 OBDC_LED_LM_L_Req: 8 Vector__XXX
 SG_ OBDC_LED_LM_L_Req_Data : 0|64@1+ (1,0) [0|1.84467440737096E+019] "" Vector__XXX

BO_ 2550006422 OBDC_LED_LM_L_Resp: 8 Vector__XXX
 SG_ OBDC_LED_LM_L_Resp_Data : 0|64@1+ (1,0) [0|1.84467440737096E+019] "" Vector__XXX

BO_ 2549875351 OBDC_LED_LM_R_Req: 8 Vector__XXX
 SG_ OBDC_LED_LM_R_Req_Data : 0|64@1+ (1,0) [0|1.84467440737096E+019] "" Vector__XXX

BO_ 2550006423 OBDC_LED_LM_R_Resp: 8 Vector__XXX
 SG_ OBDC_LED_LM_R_Resp_Data : 0|64@1+ (1,0) [0|1.84467440737096E+019] "" Vector__XXX

BO_ 2549875284 OBDC_LWRAFS_Req: 8 Vector__XXX
 SG_ OBDC_LWRAFS_Req_Struct : 0|64@1+ (1,0) [0|1.84467440737096E+019] "" Vector__XXX

BO_ 2550006356 OBDC_LWRAFS_Resp: 8 Vector__XXX
 SG_ OBDC_LWRAFS_Resp_Data : 0|64@1+ (1,0) [0|1.84467440737096E+019] "" Vector__XXX

BO_ 2549875278 OBDC_SWA_Req: 8 Vector__XXX
 SG_ OBDC_SWA_Req_Data : 0|64@1+ (1,0) [0|1.84467440737096E+019] "" Vector__XXX

BO_ 2550006350 OBDC_SWA_Resp: 8 Vector__XXX
 SG_ OBDC_SWA_Resp_Data : 0|64@1+ (1,0) [0|1.84467440737096E+019] "" Vector__XXX

BO_ 1175 Parkhilfe_01: 8 Vector__XXX
 SG_ PH_Visualisierung : 0|3@1+ (1,0) [0|7] "" Vector__XXX
 SG_ PDC_Tonausgabe_Front : 4|4@1+ (1,0) [0|15] "" Vector__XXX
 SG_ PDC_Tonausgabe_Heck : 8|4@1+ (1,0) [0|15] "" Vector__XXX
 SG_ PH_nachtr_Stopp_Anf : 12|1@1+ (1,0) [0|1] "" Vector__XXX
 SG_ PH_Abschaltursache : 13|3@1+ (1,0) [0|7] "" Vector__XXX
 SG_ PH_Opt_Anzeige_V_ein : 16|1@1+ (1,0) [0|1] "" Vector__XXX
 SG_ PH_Opt_Anzeige_H_ein : 17|1@1+ (1,0) [0|1] "" Vector__XXX
 SG_ PH_Opt_Anz_V_Hindernis : 18|1@1+ (1,0) [0|1] "" Vector__XXX
 SG_ PH_Opt_Anz_H_Hindernis : 19|1@1+ (1,0) [0|1] "" Vector__XXX
 SG_ PH_Tongeber_V_aktiv : 20|1@1+ (1,0) [0|1] "" Vector__XXX
 SG_ PH_Tongeber_H_aktiv : 21|1@1+ (1,0) [0|1] "" Vector__XXX
 SG_ PH_Tongeber_mute : 22|1@1+ (1,0) [0|1] "" Vector__XXX
 SG_ PH_Anf_Audioabsenkung : 23|1@1+ (1,0) [0|1] "" Vector__XXX
 SG_ PH_Tongeber_H_verfuegbar : 24|1@1+ (1,0) [0|1] "" Vector__XXX
 SG_ PLA_Anf_Aufschaltung_RVC : 25|1@1+ (1,0) [0|1] "" Vector__XXX
 SG_ PH_Taster : 28|2@1+ (1,0) [0|3] "" Vector__XXX
 SG_ PH_Anf_Verdeck : 30|2@1+ (1,0) [0|3] "" Vector__XXX
 SG_ PH_Frequenz_hinten : 32|4@1+ (1,0) [0|15] "" Vector__XXX
 SG_ PH_Lautstaerke_hinten : 36|4@1+ (1,0) [0|15] "" Vector__XXX
 SG_ PH_Frequenz_vorn : 40|4@1+ (1,0) [0|15] "" Vector__XXX
 SG_ PH_Lautstaerke_vorn : 44|4@1+ (1,0) [0|15] "" Vector__XXX
 SG_ PH_StartStopp_Info : 49|2@1+ (1,0) [0|3] "" Vector__XXX
 SG_ PH_Stoermeldung : 52|4@1+ (1,0) [0|15] "" Vector__XXX
 SG_ PH_defekt : 56|1@1+ (1,0) [0|1] "" Vector__XXX
 SG_ PH_gestoert : 57|1@1+ (1,0) [0|1] "" Vector__XXX
 SG_ PH_Systemzustand : 58|3@1+ (1,0) [0|7] "" Vector__XXX
 SG_ PH_Display_Kundenwunsch : 61|2@1+ (1,0) [0|3] "" Vector__XXX

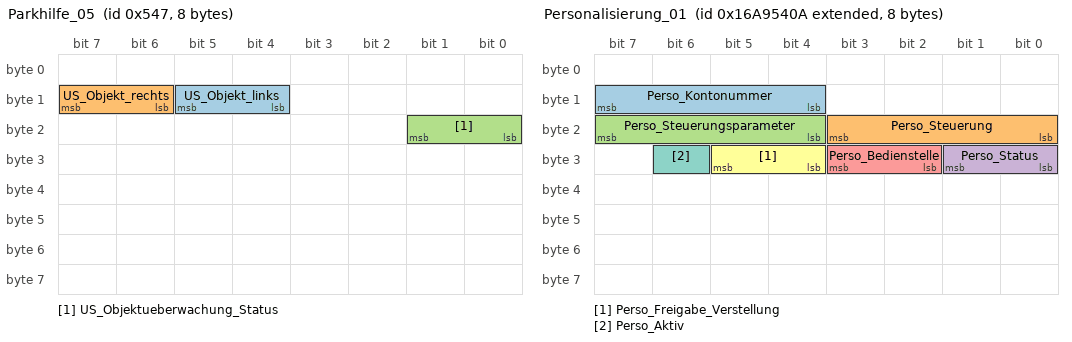
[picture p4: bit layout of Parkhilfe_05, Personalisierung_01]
BO_ 1351 Parkhilfe_05: 8 Vector__XXX
 SG_ US_Objekt_links : 12|2@1+ (1,0) [0|3] "" Vector__XXX
 SG_ US_Objekt_rechts : 14|2@1+ (1,0) [0|3] "" Vector__XXX
 SG_ US_Objektueberwachung_Status : 16|2@1+ (1,0) [0|3] "" Vector__XXX

BO_ 2527679498 Personalisierung_01: 8 Vector__XXX
 SG_ Perso_Kontonummer : 12|4@1+ (1,0) [0|15] ""  Frontradar
 SG_ Perso_Steuerung : 16|4@1+ (1,0) [0|15] ""  Frontradar
 SG_ Perso_Steuerungsparameter : 20|4@1+ (1,0) [0|15] ""  Frontradar
 SG_ Perso_Status : 24|2@1+ (1,0) [0|3] ""  Frontradar
 SG_ Perso_Bedienstelle : 26|2@1+ (1,0) [0|3] "" Vector__XXX
 SG_ Perso_Freigabe_Verstellung : 28|2@1+ (1,0) [0|3] "" Vector__XXX
 SG_ Perso_Aktiv : 30|1@1+ (1,0) [0|1] "" Vector__XXX

BO_ 929 PSD_01: 8 Vector__XXX
 SG_ PSD_Pos_Segment_ID : 0|6@1+ (1,0) [2|63] ""  Frontsensorik
 SG_ PSD_Pos_Segmentlaenge : 6|7@1+ (2,0) [0|254] "Unit_Meter"  Frontsensorik
 SG_ PSD_Pos_Inhibitzeit : 13|5@1+ (10,0) [0|310] "Unit_MilliSecon"  Frontsensorik
 SG_ PSD_Pos_Standort : 18|1@1+ (1,0) [0|1] ""  Frontsensorik
 SG_ PSD_Pos_Laengsfehler : 19|3@1+ (1,0) [0|7] ""  Frontsensorik
 SG_ PSD_Segment_ID : 22|6@1+ (1,0) [2|63] ""  Frontsensorik
 SG_ PSD_Vorgaenger_Segment_ID : 28|6@1+ (1,0) [2|63] ""  Frontsensorik
 SG_ PSD_Strassenklasse : 34|2@1+ (1,0) [0|3] ""  Frontsensorik
 SG_ PSD_Segmentlaenge : 36|7@1+ (2,0) [0|254] "Unit_Meter"  Frontsensorik
 SG_ PSD_Rampe : 43|2@1+ (1,0) [0|3] ""  Frontsensorik
 SG_ PSD_Endkruemmung : 45|8@1+ (1,0) [0|254] "Unit_None"  Frontsensorik
 SG_ PSD_Endkruemmung_Vorz : 53|1@1+ (1,0) [0|1] ""  Frontsensorik
 SG_ PSD_Endsteigung : 54|5@1+ (0.5,0) [0|14.5] "Unit_PerCent"  Frontsensorik
 SG_ PSD_Endsteigung_Vorz : 59|1@1+ (1,0) [0|1] ""  Frontsensorik
 SG_ PSD_ADAS_Qualitaet : 60|1@1+ (1,0) [0|1] ""  Frontsensorik
 SG_ PSD_Fahrspuren : 61|2@1+ (1,0) [0|3] ""  Frontsensorik
 SG_ PSD_wahrscheinlichster_Pfad : 63|1@1+ (1,0) [0|1] ""  Frontsensorik

CM_ BO_ 134 "ab MQB mit CRC in Byte 1";
CM_ SG_ 134 LWI_01_CRC "Für MLB:
'Berechnung siehe Lastenheft 'Kommunikationsabsicherung für FlexRay und CAN''

Ab MQB und MLBevo:
'Berechnung siehe Lastenheft 'End-to-End Kommunikationsabsicherung'

Endwerte siehe Begleitdokument 'S-PDU Kennungsfolgen'";
CM_ SG_ 134 LWI_QBit_Sub_Daten "Es gilt die Signalspezifikation laut LAH";
CM_ SG_ 134 LWI_QBit_Lenkradwinkel "Das QBit wird auch bei nicht abgeglichenem Lenkradwinkelsensor gesetzt";
CM_ SG_ 134 LWI_Lenkradwinkel "Wertebereich = +/- 800 Grad
Auflösung = 0,1 Grad
ACHTUNG: spezifizierte Interne Auflösung des Sensors beträgt aber nur Schrittweite 0,5 Grad!

Hinweis:
MLB: Zusätzlich gestellte Winkel bei Dynamiklenkung beachten !
MQB: Nicht konstante Lenkübersetzu";
CM_ SG_ 134 LWI_VZ_Lenkradwinkel "Vorzeichen Lenkradwinkel gemäss DIN70000; 
Nullstellung = +0";
CM_ SG_ 134 LWI_VZ_Lenkradw_Geschw "Vorzeichen Lenkradwinkelgeschwindigkeit gemäss DIN70000; 
Nullstellung = +0";
CM_ SG_ 134 LWI_Lenkradw_Geschw "Wertebereich = +/- 2500 Grad/s
Auflösung = 5 Grad/s

Hinweis: Zusätzlich gestellte Winkel bei Dynamiklenkung beachten !";
CM_ SG_ 134 LWI_Sub_Daten "Verschlüsseltes Datenpaket vom Sub-Rechner des LWS, Verwendung nur durch SCU und ESP_ADS
Verwendung gemäß 'Sicherheitsanforderungen an Empfängersteuergeräte'

Im MLB gilt die Signalspezifikation: LAH 8K0953B
Im MLBevo gilt die Signalspezifikation LAH.";
CM_ BO_ 917 "MLB";
CM_ SG_ 917 AFS_Abbiegelicht_li_Anf "Anforderung das Abbiegelicht links einzuschalten";
CM_ SG_ 917 AFS_Abbiegelicht_re_Anf "Anforderung das Abbiegelicht rechts einzuschalten";
CM_ SG_ 917 AFS_Abbiegelicht_Dimm_Anf "Beschreibt ob das Abbiegelicht gedimmt oder hart einschalten werden soll. Dimmkurve ist Empfänger hinterlegt.";
CM_ SG_ 917 AFS_Verfuegbarkeit_GLW "Beschreibt die Verfügbarkeit der Gleitenden Leuchtweite / Fernlichtassistenz - Verfügbarkeit bedeutet, dass die Funktion Gleitende Leuchtweite möglich ist";
CM_ SG_ 917 AFS_Status_adaptive_LV "Gibt den Status der adaptiven Lichtverteilung an";
CM_ SG_ 917 AFS_Fernlicht_li_defekt "Beschreibt ob das Fernlicht des linken Scheinwerfers defekt ist";
CM_ SG_ 917 AFS_Fernlicht_re_defekt "Beschreibt ob das Fernlicht des rechten Scheinwerfers defekt ist";
CM_ SG_ 917 AFS_Fernlicht_Status "Beschreibt ob das Fernlicht aktiv oder inaktiv ist";
CM_ SG_ 917 AFS_Lampe "Status der Fehlerlampe: aktuell anliegender Fehlerzustand des dynamischen oder statischen Kurvenlichtes";
CM_ SG_ 917 LWR_Lampe "Status der Fehlerlampe: aktuell anliegender Fehlerzustand";
CM_ SG_ 917 AFS_Fehlertext "Fehlertext wird im Kombi angezeigt (z.Zt nur bei VW)";
CM_ SG_ 917 AFS_LED_Blinkmode "Lampe soll im Warnfall mit 1Hz blinken, wenn das Bit gesetzt ist (z.Zt nur bei VW)";
CM_ SG_ 917 LWR_Touristenmodus_aktiv "Über MMI sendet BCM1 eine Anforderung Touristenmodus an die LWR. Diese sendet als Rückmeldung an BCM1, dass der Touristenmodus aktiv geschaltet wurde";
CM_ SG_ 917 AFS_Charisma_FahrPr "MLBevo: Aktuelles Fahrprogramm des Charisma-Teilnehmers (siehe Systemlastenheft Drive Select)
MQB: Istwert der Kennlinie (siehe Systemlastenheft MQB FPA)";
CM_ SG_ 917 AFS_Charisma_Status "Charisma Systemstatus des Charisma-Teilnehmers

Wert 0x3 ist nur für Fahrzeuge ab MQB relevant";
CM_ SG_ 917 AFS_Allwetterlicht "Status ¿Allwetterlicht¿ - Licht für schlechte Sichtverhältnisse
(bei Defekt -> nicht aktiv)";
CM_ SG_ 917 LWR_Touristenmodus_verbaut "Verfügbarkeit der Touristenfunktion im AFS/LWR-SG.
(Das BCM steuert mit diesem Signal die Einblendung des entsprechenden Menüs)";
CM_ SG_ 917 AFS_adaptive_LV_verbaut "Verfügbarkeit der adaptiven Lichtverteilung im AFS-SG.
(Das BCM steuert mit diesem Signal die Einblendung des entsprechenden Menüs)";
CM_ SG_ 917 LWR_Reisemodus_Texte "Anzeige der eingestellten Verkehrsart bei aktivem Touristenlicht";
CM_ SG_ 917 GLW_Sensor_blockiert "Das Signal zeigt an, dass die Kamera zur Zeit keine Sicht hat. 
Verhalten wie Fernlichassisten. 
Weiterleitung des Signals vom BCM an das KOMBI";
CM_ SG_ 917 LWR_Pos_Schrittmotor "Position des Aktuators in Prozent des maximalen Stellweges; vor dem Initialisierungslauf (Motorstart) wird der Initwert ausgegeben: 
0% : tiefste Stellung (auf Block) des Schrittmotors;
100% : maximaler Verstellweg des Schrittmotors (nicht die Grenze de";
CM_ SG_ 917 LWR_Hoehenwert_VL "Aktueller Höhensensorwert Vorne Links

0x7F = 0 mm";
CM_ SG_ 917 LWR_Hoehenwert_HL "Aktueller Höhensensorwert Hinten Links
MSS LB überträgt den Aktueller Höhensensorwert Vorne Rechts.

0x7F = 0 mm";
CM_ SG_ 917 AFS_Ersatzlicht_Links "Bei aktivierter Ersatzlichtfunktion wird das Abblendlicht ausgeschaltet und eine Ersatzlichtquelle eingeschaltet (z.Zt. B7)";
CM_ SG_ 917 AFS_Ersatzlicht_Rechts "Bei aktivierter Ersatzlichtfunktion wird das Abblendlicht ausgeschaltet und eine Ersatzlichtquelle eingeschaltet (z.Zt. B7)";
CM_ SG_ 917 LWR_AFS_Grundeinstellung "Grundeinstellung des Abblendlichtes am Lichteinstellkasten im Service oder Bandende mit Tester erfolgt! (auch für das dynamische Kurvernlicht)";
CM_ SG_ 917 LWR_AFS_Parametrisierung "Parametrisierung wählt die Fahrzeugvariante und die AFS-Variante aus";
CM_ SG_ 917 LWR_Initialisierungslauf "Initialisierungslauf der Schrittmotoren, erfolgt defaultmäßig beim Motorstart";
CM_ SG_ 917 LWR_Sicherheitsposition "LWR Sicherheitsposition beider Scheinwerfers";
CM_ SG_ 917 LWR_Modus "Schnelle oder langsame Regelart der LWR";
CM_ SG_ 295 LWR_Verstellwinkel_li "Verstellwinkelposition der dynamischen Leuchtweitenregulierung des linken Scheinwerfers";
CM_ SG_ 295 LWR_Verstellwinkel_re "Verstellwinkelposition der dynamischen Leuchtweitenregulierung des linken Scheinwerfers";
CM_ SG_ 295 AFS_Schwenkwinkel_li "Schwenkwinkelposition des dynamischen Kurvenlichts des linken Scheinwerfers, Linksschwenken entspricht positiver Schwenkrichtung - Rechtsschwenken entspricht negativer Schwenkrichtung";
CM_ SG_ 295 AFS_Schwenkwinkel_re "Schwenkwinkelposition des dynamischen Kurvenlichts des rechten Scheinwerfers,  Linksschwenken entspricht positiver Schwenkrichtung - Rechtsschwenken entspricht negativer Schwenkrichtung";
CM_ SG_ 295 AFS_Lichtverteilung_li "Ansteuerungsstatus der adaptiven Lichtverteilung im linken Scheinwerfer";
CM_ SG_ 295 AFS_Lichtverteilung_re "Ansteuerungsstatus der adaptiven Lichtverteilung im rechten Scheinwerfer";
CM_ SG_ 295 AFS_Status_Verkehrsart "Aktuelle Ausleuchtung in Bezug auf die Verkehrsart unter Berücksichtigung des Touristenmodus";
CM_ SG_ 295 GLW_Nebelregelung "Dieses Signal beschreibt den Zustand 'Nebelregelung' aufgrund einer Sichteinschränkung der Kamera.";
CM_ BO_ 846 "Matrixbeam";
CM_ SG_ 846 MXB_Status_Seg01 "Gibt den Status des Fernlichtsegments wieder. Signal gilt für MXB_Status_Segment01 bis MXB_Status_SegmentXY";
CM_ SG_ 846 MXB_Status_Seg02 "Gibt den Status des Fernlichtsegments wieder. Signal gilt für MXB_Status_Segment01 bis MXB_Status_SegmentXY";
CM_ SG_ 846 MXB_Status_Seg03 "Gibt den Status des Fernlichtsegments wieder. Signal gilt für MXB_Status_Segment01 bis MXB_Status_SegmentXY";
CM_ SG_ 846 MXB_Status_Seg04 "Gibt den Status des Fernlichtsegments wieder. Signal gilt für MXB_Status_Segment01 bis MXB_Status_SegmentXY";
CM_ SG_ 846 MXB_Status_Seg05 "Gibt den Status des Fernlichtsegments wieder. Signal gilt für MXB_Status_Segment01 bis MXB_Status_SegmentXY";
CM_ SG_ 846 MXB_Status_Seg06 "Gibt den Status des Fernlichtsegments wieder. Signal gilt für MXB_Status_Segment01 bis MXB_Status_SegmentXY";
CM_ SG_ 846 MXB_Status_Seg07 "Gibt den Status des Fernlichtsegments wieder. Signal gilt für MXB_Status_Segment01 bis MXB_Status_SegmentXY";
CM_ SG_ 846 MXB_Status_Seg08 "Gibt den Status des Fernlichtsegments wieder. Signal gilt für MXB_Status_Segment01 bis MXB_Status_SegmentXY";
CM_ SG_ 846 MXB_Status_Seg09 "Gibt den Status des Fernlichtsegments wieder. Signal gilt für MXB_Status_Segment01 bis MXB_Status_SegmentXY";
CM_ SG_ 846 MXB_Status_Seg10 "Gibt den Status des Fernlichtsegments wieder. Signal gilt für MXB_Status_Segment01 bis MXB_Status_SegmentXY";
CM_ SG_ 846 MXB_Status_Seg11 "Gibt den Status des Fernlichtsegments wieder. Signal gilt für MXB_Status_Segment01 bis MXB_Status_SegmentXY";
CM_ SG_ 846 MXB_Status_Seg12 "Gibt den Status des Fernlichtsegments wieder. Signal gilt für MXB_Status_Segment01 bis MXB_Status_SegmentXY";
CM_ SG_ 846 MXB_Status_Seg13 "Gibt den Status des Fernlichtsegments wieder. Signal gilt für MXB_Status_Segment01 bis MXB_Status_SegmentXY";
CM_ SG_ 846 MXB_Status_Seg14 "Gibt den Status des Fernlichtsegments wieder. Signal gilt für MXB_Status_Segment01 bis MXB_Status_SegmentXY";
CM_ SG_ 846 MXB_Status_Seg15 "Gibt den Status des Fernlichtsegments wieder. Signal gilt für MXB_Status_Segment01 bis MXB_Status_SegmentXY";
CM_ SG_ 846 MXB_Status_Seg16 "Gibt den Status des Fernlichtsegments wieder. Signal gilt für MXB_Status_Segment01 bis MXB_Status_SegmentXY";
CM_ SG_ 846 MXB_Status_Seg17 "Gibt den Status des Fernlichtsegments wieder. Signal gilt für MXB_Status_Segment01 bis MXB_Status_SegmentXY";
CM_ SG_ 846 MXB_Status_Seg18 "Gibt den Status des Fernlichtsegments wieder. Signal gilt für MXB_Status_Segment01 bis MXB_Status_SegmentXY";
CM_ SG_ 846 MXB_Status_Seg19 "Gibt den Status des Fernlichtsegments wieder. Signal gilt für MXB_Status_Segment01 bis MXB_Status_SegmentXY";
CM_ SG_ 846 MXB_Status_Seg20 "Gibt den Status des Fernlichtsegments wieder. Signal gilt für MXB_Status_Segment01 bis MXB_Status_SegmentXY";
CM_ SG_ 846 MXB_Status_Seg21 "Gibt den Status des Fernlichtsegments wieder. Signal gilt für MXB_Status_Segment01 bis MXB_Status_SegmentXY";
CM_ SG_ 846 MXB_Status_Seg22 "Gibt den Status des Fernlichtsegments wieder. Signal gilt für MXB_Status_Segment01 bis MXB_Status_SegmentXY";
CM_ SG_ 846 MXB_Status_Seg23 "Gibt den Status des Fernlichtsegments wieder. Signal gilt für MXB_Status_Segment01 bis MXB_Status_SegmentXY";
CM_ SG_ 846 MXB_Status_Seg24 "Gibt den Status des Fernlichtsegments wieder. Signal gilt für MXB_Status_Segment01 bis MXB_Status_SegmentXY";
CM_ SG_ 846 MXB_Status_Seg25 "Gibt den Status des Fernlichtsegments wieder. Signal gilt für MXB_Status_Segment01 bis MXB_Status_SegmentXY";
CM_ SG_ 846 MXB_Status_Seg26 "Gibt den Status des Fernlichtsegments wieder. Signal gilt für MXB_Status_Segment01 bis MXB_Status_SegmentXY";
CM_ SG_ 846 MXB_Status_Seg27 "Gibt den Status des Fernlichtsegments wieder. Signal gilt für MXB_Status_Segment01 bis MXB_Status_SegmentXY";
CM_ SG_ 846 MXB_Status_Seg28 "Gibt den Status des Fernlichtsegments wieder. Signal gilt für MXB_Status_Segment01 bis MXB_Status_SegmentXY";
CM_ SG_ 846 MXB_Status_Seg29 "Gibt den Status des Fernlichtsegments wieder. Signal gilt für MXB_Status_Segment01 bis MXB_Status_SegmentXY";
CM_ SG_ 846 MXB_Status_Seg30 "Gibt den Status des Fernlichtsegments wieder. Signal gilt für MXB_Status_Segment01 bis MXB_Status_SegmentXY";
CM_ SG_ 846 MXB_Status_Seg31 "Gibt den Status des Fernlichtsegments wieder. Signal gilt für MXB_Status_Segment01 bis MXB_Status_SegmentXY";
CM_ SG_ 846 MXB_Status_Seg32 "Gibt den Status des Fernlichtsegments wieder. Signal gilt für MXB_Status_Segment01 bis MXB_Status_SegmentXY";
CM_ BO_ 847 "Matrixbeam";
CM_ SG_ 847 MXB_Status_Seg33 "Gibt den Status des Fernlichtsegments wieder. Signal gilt für MXB_Status_Segment01 bis MXB_Status_SegmentXY";
CM_ SG_ 847 MXB_Status_Seg34 "Gibt den Status des Fernlichtsegments wieder. Signal gilt für MXB_Status_Segment01 bis MXB_Status_SegmentXY";
CM_ SG_ 847 MXB_Status_Seg35 "Gibt den Status des Fernlichtsegments wieder. Signal gilt für MXB_Status_Segment01 bis MXB_Status_SegmentXY";
CM_ SG_ 847 MXB_Status_Seg36 "Gibt den Status des Fernlichtsegments wieder. Signal gilt für MXB_Status_Segment01 bis MXB_Status_SegmentXY";
CM_ SG_ 847 MXB_Status_Seg37 "Gibt den Status des Fernlichtsegments wieder. Signal gilt für MXB_Status_Segment01 bis MXB_Status_SegmentXY";
CM_ SG_ 847 MXB_Status_Seg38 "Gibt den Status des Fernlichtsegments wieder. Signal gilt für MXB_Status_Segment01 bis MXB_Status_SegmentXY";
CM_ SG_ 847 MXB_Status_Seg39 "Gibt den Status des Fernlichtsegments wieder. Signal gilt für MXB_Status_Segment01 bis MXB_Status_SegmentXY";
CM_ SG_ 847 MXB_Status_Seg40 "Gibt den Status des Fernlichtsegments wieder. Signal gilt für MXB_Status_Segment01 bis MXB_Status_SegmentXY";
CM_ SG_ 847 MXB_Status_Seg41 "Gibt den Status des Fernlichtsegments wieder. Signal gilt für MXB_Status_Segment01 bis MXB_Status_SegmentXY";
CM_ SG_ 847 MXB_Status_Seg42 "Gibt den Status des Fernlichtsegments wieder. Signal gilt für MXB_Status_Segment01 bis MXB_Status_SegmentXY";
CM_ SG_ 847 MXB_Status_Seg43 "Gibt den Status des Fernlichtsegments wieder. Signal gilt für MXB_Status_Segment01 bis MXB_Status_SegmentXY";
CM_ SG_ 847 MXB_Status_Seg44 "Gibt den Status des Fernlichtsegments wieder. Signal gilt für MXB_Status_Segment01 bis MXB_Status_SegmentXY";
CM_ SG_ 847 MXB_Status_Seg45 "Gibt den Status des Fernlichtsegments wieder. Signal gilt für MXB_Status_Segment01 bis MXB_Status_SegmentXY";
CM_ SG_ 847 MXB_Status_Seg46 "Gibt den Status des Fernlichtsegments wieder. Signal gilt für MXB_Status_Segment01 bis MXB_Status_SegmentXY";
CM_ SG_ 847 MXB_Status_Seg47 "Gibt den Status des Fernlichtsegments wieder. Signal gilt für MXB_Status_Segment01 bis MXB_Status_SegmentXY";
CM_ SG_ 847 MXB_Status_Seg48 "Gibt den Status des Fernlichtsegments wieder. Signal gilt für MXB_Status_Segment01 bis MXB_Status_SegmentXY";
CM_ SG_ 847 MXB_Status_Seg49 "Gibt den Status des Fernlichtsegments wieder. Signal gilt für MXB_Status_Segment01 bis MXB_Status_SegmentXY";
CM_ SG_ 847 MXB_Status_Seg50 "Gibt den Status des Fernlichtsegments wieder. Signal gilt für MXB_Status_Segment01 bis MXB_Status_SegmentXY";
CM_ SG_ 847 MXB_Status_Seg51 "Gibt den Status des Fernlichtsegments wieder. Signal gilt für MXB_Status_Segment01 bis MXB_Status_SegmentXY";
CM_ SG_ 847 MXB_Status_Seg52 "Gibt den Status des Fernlichtsegments wieder. Signal gilt für MXB_Status_Segment01 bis MXB_Status_SegmentXY";
CM_ SG_ 847 MXB_Status_Seg53 "Gibt den Status des Fernlichtsegments wieder. Signal gilt für MXB_Status_Segment01 bis MXB_Status_SegmentXY";
CM_ SG_ 847 MXB_Status_Seg54 "Gibt den Status des Fernlichtsegments wieder. Signal gilt für MXB_Status_Segment01 bis MXB_Status_SegmentXY";
CM_ SG_ 847 MXB_Status_Seg55 "Gibt den Status des Fernlichtsegments wieder. Signal gilt für MXB_Status_Segment01 bis MXB_Status_SegmentXY";
CM_ SG_ 847 MXB_Status_Seg56 "Gibt den Status des Fernlichtsegments wieder. Signal gilt für MXB_Status_Segment01 bis MXB_Status_SegmentXY";
CM_ SG_ 847 MXB_Status_Seg57 "Gibt den Status des Fernlichtsegments wieder. Signal gilt für MXB_Status_Segment01 bis MXB_Status_SegmentXY";
CM_ SG_ 847 MXB_Status_Seg58 "Gibt den Status des Fernlichtsegments wieder. Signal gilt für MXB_Status_Segment01 bis MXB_Status_SegmentXY";
CM_ SG_ 847 MXB_Status_Seg59 "Gibt den Status des Fernlichtsegments wieder. Signal gilt für MXB_Status_Segment01 bis MXB_Status_SegmentXY";
CM_ SG_ 847 MXB_Status_Seg60 "Gibt den Status des Fernlichtsegments wieder. Signal gilt für MXB_Status_Segment01 bis MXB_Status_SegmentXY";
CM_ SG_ 1721 MXB_horiz_Offset_li_SW "Horizontaler Kalibrieroffset des linken Matrix-Beam Scheinwerfers";
CM_ SG_ 1721 MXB_Status "Gibt den Status des gesamten Matrix-Beam-Fernlichts wieder";
CM_ SG_ 1721 MXB_vert_Offset_li_SW "Vertikaler Kalibrieroffset des linken Matrix-Beam Scheinwerfers";
CM_ SG_ 1721 AFS_Abblendlicht_li_defekt "Anzeige Abblendlicht links defekt";
CM_ SG_ 1721 AFS_Abblendlicht_re_defekt "Anzeige Abblendlicht rechts defekt";
CM_ SG_ 1721 AFS_stat_Kurvenlicht_li_defekt "Anzeige statisches Kurvenlicht links defekt";
CM_ SG_ 1721 AFS_stat_Kurvenlicht_re_defekt "Anzeige statisches Kurvenlicht rechts defekt";
CM_ SG_ 1721 AFS_Tagfahrlicht_li_defekt "Anzeige Tagfahrlicht links defekt";
CM_ SG_ 1721 AFS_Tagfahrlicht_re_defekt "Anzeige Tagfahrlicht rechts defekt";
CM_ SG_ 1721 MXB_Allgemein_li_defekt "Sammelfehler für die Elektronikumfänge des linken Scheinwerfers";
CM_ SG_ 1721 MXB_Allgemein_re_defekt "Sammelfehler für die Elektronikumfänge des rechten Scheinwerfers";
CM_ SG_ 1721 AFS_Zusatzfernlicht_li_defekt "Anzeige Zusatzfernlicht links defekt";
CM_ SG_ 1721 AFS_Zusatzfernlicht_re_defekt "Anzeige Zusatzfernlicht rechts defekt";
CM_ SG_ 1721 LED_Steuerung_li_defekt "allgemeiner Fehler der LED Steuerung links (Lüfter, Temperatursensor, Steuergerät defekt, etc.)";
CM_ SG_ 1721 LED_Steuerung_re_defekt "allgemeiner Fehler der LED Steuerung rechts (Lüfter, Temperatursensor, Steuergerät defekt, etc.)";
CM_ SG_ 1721 MXB_horiz_Offset_re_SW "Horizontaler Kalibrieroffset des rechtenMatrix-Beam Scheinwerfers";
CM_ SG_ 1721 MXB_vert_Offset_re_SW "Vertikaler Kalibrieroffset des rechten Matrix-Beam Scheinwerfers";
CM_ SG_ 506 LCM_TFL_Fehler_L "TFL Fehler";
CM_ SG_ 506 LCM_TFL_Fehler_R "TFL Fehler";
CM_ SG_ 506 LCM_SM_Fehler_L "Sidemarker Fehler";
CM_ SG_ 506 LCM_SM_Fehler_R "Sidemarker Fehler";
CM_ SG_ 506 LCM_Shutter_Fehler_L "Shutter Fehler";
CM_ SG_ 506 LCM_Shutter_Fehler_R "Shutter Fehler";
CM_ SG_ 506 LCM_PO_Fehler_L "PO Fehler";
CM_ SG_ 506 LCM_PO_Fehler_R "PO Fehler";
CM_ SG_ 506 LCM_Blinker_Fehler_L "Blinker Fehler";
CM_ SG_ 506 LCM_Blinker_Fehler_R "Blinker Fehler";
CM_ SG_ 506 LCM_Blinker_L_Sta "Blinker Status links";
CM_ SG_ 506 LCM_Blinker_R_Sta "Blinker Status rechts";
CM_ SG_ 506 LCM_Datensatz_Fehler_L "zeigt einen vorliegenden Datensatz Fehler im LCM an (fehlender bzw. unplausibler Datensatz)";
CM_ SG_ 506 LCM_Datensatz_Fehler_R "zeigt einen vorliegenden Datensatz Fehler im LCM an (fehlender bzw. unplausibler Datensatz)";
CM_ SG_ 506 LCM_Abschaltbestaetigung_L "Handshake - LCM bestätigt Anfrage";
CM_ SG_ 506 LCM_Abschaltbestaetigung_R "Handshake - LCM bestätigt Anfrage";
CM_ SG_ 506 LCM_Sta_LM_L_alt "Veraltet-Bit LCM_Sta_LM_L";
CM_ SG_ 506 LCM_Sta_LM_R_alt "Veraltet-Bit LCM_Sta_LM_R";
CM_ SG_ 506 LCM_Feh_LM_L_alt "Veraltet-Bit LCM_Feh_LM_L";
CM_ SG_ 506 LCM_Feh_LM_R_alt "Veraltet-Bit LCM_Feh_LM_R";
CM_ SG_ 1153 MMI_Counter_Bedienevent "Signal wird inkrementiert, wenn Bedienevent stattgefunden hat.";
CM_ SG_ 1153 DSSS_Warning "DSSS - Driving Safety Support System Meldungen";
CM_ SG_ 1153 ZR_Kindersicherung_RSE "Sperren der Rearseat Unit (Komplette Weckfähigkeit)";
CM_ SG_ 1153 ZR_RSE_aktivieren "Weckfähigkeit der RSE";
CM_ SG_ 1153 MMI_SDS_aktiv "Signal wird gesetzt, solange die Sprachbedienung aktiv ist.";
CM_ SG_ 1153 MU_SecondDisplay "Dient zur Überwachung der zweiten LVDS Leitung.";
CM_ SG_ 1153 MMI_Gurt_Mic_ref "Referenzsignal für das Gurtmikrofon Steuergerät zur Signalisierung ob der Downlink aktiv oder inaktiv ist";
CM_ SG_ 1153 ZR_Parken_Sondermodus "Rückkanal zum pilotierten Parken zur Signalisierung Status Sondermodus";
CM_ BO_ 1600 "ab MQB mit QBit Höheneinfo und MO_Versionsinfo_02";
CM_ SG_ 1600 MO_QBit_Ansaugluft_Temp "
";
CM_ SG_ 1600 MO_QBit_Kuehlmittel_Temp "
";
CM_ SG_ 1600 MO_KL15_Abschaltempfehlung "Kessy Abschaltempfehlung nach Verlassen des Fahrzeugs";
CM_ SG_ 1600 MO_HYB_Fehler_HV_Netz "Im HV-Bordnetz ist fehlerbedingt kein generatorischer Betrieb möglich. Das 12V-Bordnetz wird über den DC/DC-Wandler allein aus der Traktionsbatterie gespeist. Um diesen Zustand möglichst lange aufrechterhalten zu können, sollten Komfort-Verbraucher abgesc";
CM_ SG_ 1600 MO_aktives_Getriebeheizen "Information für Getriebe, ob ein Ventil für Getriebheizen angesteuert werden muss";
CM_ SG_ 1600 MO_Absperrventil_oeffnen "Signal an Klima-SG das Absperrrventil anzusteuern. Ab D4 auch 0x3 Ventil_schließen.

Im MQB wird hier der Soll-Status des Absperrventils ausgegeben.
Achtung: bei z. B. klemmendem Ventil entspricht das Signal nicht dem tatsächlichen Status!";
CM_ SG_ 1600 MO_Ansaugluft_Temp "In Fahrzeugen ohne Außentemperatur vom Kombi kann aus der Ansauglufttemperatur auf die Außentemperatur geschlossen werden. Beim SDI ist das mit einer gewissen Genauigkeit gegeben. Genutzt wird es vom ASG.";
CM_ SG_ 1600 MO_Oel_Temp "Realer Meßbereich ca. -40..150 Grad";
CM_ SG_ 1600 MO_Kuehlmittel_Temp "Kuehlmitteltemperatur";
CM_ SG_ 1600 MO_Hoeheninfo "Korrekturfaktor Höhe (1 entspricht 1013 mbar)";
CM_ SG_ 1600 MO_Kennfeldk "Die Kennfeldkühlung ist in diesem Fahrzeug verbaut und hat keinen Systemfehler";
CM_ SG_ 1600 MO_Versionsinfo_02 "Versioninformation vom Motor zur Steuerung bei inkompatiblen KMatrix-Änderung bzw. Einführung von neuen Funktionen, die in den Empfängern verriegelt werden müssen. Zu jedem Ereignis wird ein fixer Zählerstand zugeordnet, um dem Empfänger die funktionale Ä";
CM_ SG_ 1600 MO_QBit_Hoeheninfo "Qualifizierungsbit der Höheninfo. Gesetzt bei Ersatzwert, Init oder Fehler.";
CM_ SG_ 1600 MO_Getriebe_kuehlen "Anforderung Getriebekühlventilansteuerung";
CM_ SG_ 1600 MO_Mom_Traegheit_02 "Massenträgheit (J) der Motors bzw. der Antriebsmaschinen in kgm².

Zur Berücksichtigung des E-Motor in Hybrid-Projekten:
in MLB-Projekten wird nur der J-Wert des Verbrennungsmotors und nicht der J-Wert des E-Motors berücksichtigt.
In MQB/MLBevo-Projek";
CM_ SG_ 1600 MO_Heizungspumpenansteuerung "Anforderung Heizungspumpenansteuerung
MQB und Hybrid: Status der Heizungsunterstützungspumpe am MSG
";
CM_ SG_ 1600 MO_SpannungsAnf "Forderung des Motor-SGs zur Spannungsanhebung";
CM_ SG_ 1600 MO_Nachlaufzeit_Heizungspumpe "Nachlaufzeit für Heizungspumpe für Turboladerschutz";
CM_ SG_ 958 Motor_14_CRC "Ab MQB und MLBevo:
'Berechnung siehe Lastenheft 'End-to-End Kommunikationsabsicherung'

Endwerte siehe Begleitdokument 'S-PDU Kennungsfolgen'";
CM_ SG_ 958 MO_StartStopp_Status "Aktivitätsstatus Start/Stopp-Koordinator
HYBRID:
Wenn MO_Hybridfahrzeug = 1 gilt:
Signal bezieht sich nur auf den Verbrennungsmotor, nicht auf den Hybridantrieb
";
CM_ SG_ 958 MO_StartStopp_Wiederstart "Motorwiederstart durch Start/Stopp-Koordinator
HYBRID:
Wenn MO_Hybridfahrzeug =1 gilt:
Warnung vor Spannungseinbruch beim Zustart des Verbrennungsmotors. 
-nicht relevant, da derzeit kein Start über 12V-Starter geplant-
Dieses Signal wird nur vom Hyb";
CM_ SG_ 958 MO_StartStopp_Motorstopp "Motor-Stopp durch Start/Stopp-Koordinator
HYBRID:
Wenn MO_Hybridfahrzeug = 1 gilt:
Verbrennungsmotor durch Hybrid-Koordinator im MSG ausgeschaltet. 
Die definierten Start/Stopp-Signale beziehen sich nur auf den Verbrennungsmotor!";
CM_ SG_ 958 MO_Freig_Reku "Empfehlung des Motor-SG's zur Spannungsabsenkung/-anhebung für den Rekuperationsbetrieb";
CM_ SG_ 958 MO_Kl_75 "Klemme X
";
CM_ SG_ 958 MO_Kl_50 "Klemme 50: Startausführung

MLB: nicht von allen Motoren gesendet
MQB/MLBevo: gesendet von allen Motoren ";
CM_ SG_ 958 MO_Gangposition "MLB:
Stellung des Wählhebels in der Schaltgasse des Handschaltgetriebes.
MLBevo: 
Ausweitung der Bedienung auch auf Automatikgetriebe;
Routing des Signals GE_Fahrstufe: 
1. Position_R (dez. 6) auf MO_Gangposition: Gang_R (dez. 13) wegen Entfall Signa";
CM_ SG_ 958 MO_StartStopp_Fahrerwunsch "Fahreraktivität Start/Stop";
CM_ SG_ 958 MO_HYB_Fahrbereitschaft "Signal steuert u.a. in der Lenkhilfe zusammen mit weiteren Informationen den Modewechsel in den 'Drivemode'
Grüne Anzeige im Kombiinstrument zur Signalisierung der Bereitschaft des Hybridsystems.";
CM_ SG_ 958 MO_Ext_E_Fahrt_aktiv "Funktionsrückmeldung zum erw. E-Fahr-Betrieb über Lampe/LED im E-Mode-Taster";
CM_ SG_ 958 MO_Fahrer_bremst "Redundante Bremsinformation vom Motor.

MLB:
AUDI D4: Zykluszeit: 10ms (siehe Zykluszeit schnell/Cycletime Fast)
Im AUDI B8 wird in diesem Bit der Wert der ESP-CAN-Information 'ESP_Fahrer_bremst' ausgegeben.

Achtung:
Reduktion der Zykluszeit Motor";
CM_ SG_ 958 MO_QBit_Fahrer_bremst "MLB:
AUDI D4: Zykluszeit: 10ms (siehe Zykluszeit schnell/Cycletime Fast)

Achtung:
Reduktion der Zykluszeit Motor_03 auf 10ms geplant.
Projektabhängig soll künftig mit 10ms gesendet werden.
Empfänger die in weiteren Konzern-Projekten eingesetzt werd";
CM_ SG_ 958 MO_BLS "Ungefiltertes Rohsignal des Bremslichtschalters, nur wenn HW-Eingang bestückt und ausgewertet wird. Bei Motoren ohne genutzten HW-Eingang wird kein Ersatzwert (bspw. SW-Signal über CAN) ausgegeben!
Bei AUDI muss das Signal wg. Bremslichtfunktion immer be";
CM_ SG_ 958 MO_Konsistenz_Bremsped "MLB:

AUDI D4: Zykluszeit: 10ms (siehe Zykluszeit schnell/Cycletime Fast)
Siehe 'Funktionsspezifikation Bremslichtinfo B8'

Achtung:
Reduktion der Zykluszeit Motor_03 auf 10ms geplant.
Projektabhängig soll künftig mit 10ms gesendet werden.
Empfäng";
CM_ SG_ 958 MO_Timeout_ESP "500 ms Timeout auf Bremsen-Botschaft ist >= 1 mal aufgelaufen, Löschen des Bits nach Neustart (KL15).

MLB:
AUDI D4: Zykluszeit: 10ms (siehe Zykluszeit schnell/Cycletime Fast)

Achtung:
Reduktion der Zykluszeit Motor_03 auf 10ms geplant.
Projektabh";
CM_ SG_ 958 MO_Klima_Eingr "Eingriffe des Motor bei der Klima";
CM_ SG_ 958 MO_Aussp_Anlass "Das Signal zeigt an, ob die Wiederholstartsperre aktiv ist. D. h. eine Ansteuerung des Anlassers wird auch bei erfüllten Startvoraussetzungen (HS: Interlock betätigt bzw. AT: P/N eingelegt und Bremse betätigt) nicht erfolgen.";
CM_ SG_ 958 MO_Freig_Anlass "Bit wird gesetzt, wenn der Motor beim Automatikstart gestartet werden darf (Motorstillstand, Emissionsmaßnahmen sind erfüllt).";
CM_ SG_ 958 MO_Kuppl_schalter "MLB:
Das Motorsteuergerät gibt die Information aus, ab wann der Kupplungsschalter durch das Motorsteuergerät als getreten gesehen wird
0x0: Schalter sagt betätigt (Ausgekuppelt)
0x1: Schalter sagt nicht betätigt (Eingekuppelt)

MQB:
Nur Handschalter";
CM_ SG_ 958 MO_Interlock "Das Motorsteuergerät gibt die Information aus, ab wann der Kupplungsschalter durch das Motorsteuergerät als getreten gesehen wird.
Bei Systemen für Start Stopp muss das Interlocksignal für einen Start durch das MSG generiert werden, sobald der Schalthebe";
CM_ SG_ 958 MO_Motor_laeuft "Das Motorsteuergerät gibt die Information aus, ab wann der Motor verbrennungsbedingt autark läuft und durch zuschaltbare Nebenaggregate mechanisch belastbar ist (z.B. durch Generator, Klimakompressor, etc.).

Die 'Motor läuft' Information wird ausgegebe";
CM_ SG_ 958 MO_Kickdown "Es gilt: Signalspec MO_Kickdown v1.0";
CM_ SG_ 958 MO_QBit_KL_75 "Q - Bit für das KL 75 Signal zur Vermeidung der fehlerhaften Erkennung von Motorstarts. 
Wird auf 1 gesetzt, solange das Motorsteuergerät KL15 = AUS erkannt hat.";
CM_ SG_ 958 MO_EKlKomLeiRed "Anforderung an die Klimasteuerung, die Leistungsaufnahme des E-Kompressors bei schlechtem SOC und in bestimmten Fahrsituationen zu begrenzen. (Das bereits bestehende Signal 'Klimakompressor aus' als stets umzusetzende Anforderung bleibt unverändert besteh";
CM_ SG_ 958 MO_Handshake_STH "Es gilt: Signalspec MO_Handshake v1.0

Handshake zwischen MSG und STH. Wenn das MSG die EKP aufgrund einer STH-Anforderung ansteuert und kein Fehlereintrag bzgl. EKP/KPE/NDR vorliegt, wird das Bit gesetzt.";
CM_ SG_ 958 MO_BKV_Unterdruckwarnung "Über die Unterdruckwarnung signalisiert das MSG dem ESP, dass kein ausreichender Unterdruck für den BKV zur Verfügung gestellt werden kann.";
CM_ SG_ 958 MO_Freigabe_Segeln "Freigabebit des Segelbetriebs im Getriebe. Bedingt durch bestimmte Diagnosen und Adaptionen des MSGs, die nur im Schub möglich sind, darf nicht jede Schubphase für einen Segelbetrieb genutzt werden. Eine Freigabe bleibt auch außerhalb einer Schubphase bes";
CM_ SG_ 958 MO_PTC_Status "Status-Rückmeldung vom MSG zum aktuellen PTC-Status (stufiges PTC, Relais am MSG). Bei Ansteuerung eines stufigen PTC durch ein anderes SG beschreibt das Signal die vom MSG freigegebene PTC-Stufe.";
CM_ SG_ 958 MO_QBit_Gangposition "Qualitätsbit zum Signal MO_Gangposition";
CM_ SG_ 958 MO_Signalquelle_Gangposition "Signalquelle des Signals MO_Gangposition
0: Signalquelle Gangpositionssensor
1: Signalquelle Modellwert (v/n)";
CM_ SG_ 958 MO_Remotestart_Betrieb "Das MSG ist für den Remotestart-Betrieb bereit. Nach Empfang der Motorstartanforderung für RSt-Betrieb durch BCM wird der Fahrzeugmotor gestartet und solange der Motor läuft, bleibt dieses Bit aktiv. Dieses Signal ist nur zur Verwendung durch das BCM zur ";
CM_ SG_ 958 MO_Remotestart_moeglich "Wenn Bit gesetzt, würde das MSG bei entsprechender Anforderung durch das BCM den Remotestartbetrieb einleiten, d.h. das MSG ist remotestartfähig und es liegen aktuell keine relevanten Fehler oder andere Abbruchgründe vor.";
CM_ SG_ 958 MO_FMAus_aktiv "Das Signal gibt Rückmeldung ob Freilauf Motor aus aktiv ist. Beleibt auch 0km/h (unterhalb der StartStopp Schwelle) weiterhin aktiv.";
CM_ SG_ 958 MO_FMAus_Startvariante "Startvariante beim Motorstart aus der Freilauf-Motor-AUS Phase";
CM_ SG_ 958 MO_BMS_NV_Anf_stuetzen "Garantierte Unterstützung des Zusatzspeichers ist erforderlich. Zusatzspeicher muss an das Versorgungsnezt angebunden werden. ";
CM_ SG_ 958 MO_Zylinderabschaltung "Status Zylinderabschaltung Motor";
CM_ SG_ 958 MO_HYB_VM_aktiv "0 = VMotor wird nicht aktiv gehalten (nVM < n_min und keine LL-Regelung aktiv)
1 = VMotor aktiv (ab der ersten Einspritzung; gilt auch für Schubbetrieb, wenn VMotor spätestens durch LLRegelung befeuert würde)
Verwendet zur Bestimmung des Ist-Zustandes";
CM_ SG_ 958 MO_StartVorauss_erfuellt "Dient der Fallunterscheidung bei ZAT-Betätigung im Zustand 'KL15 ein' (bei nicht gesetztem Signal folgt KL15 aus, bei gesetztem Signal folgt setzen KL50-Anf.)

0: Signal nicht bedient 
1: Voraussetzungen zur Antriebsstrangaktivierung / Startvoraussetzu";
CM_ SG_ 1631 TSK_Grundmasse "Fahrzeuggrundmasse in kg. Das Signal dient der Anpassung der Sollbeschleunigung vom ACC

Hinweis: Ehemaliger Fehlerwert 0x7F wird senderseitig nicht unterstützt. Diesen Wert aus Kompatibilitätsgründen nicht neu belegen!";
CM_ SG_ 1631 MO_SpannungsAnf_02 "Forderung des Motor-SG's zur Spannungsanhebung";
CM_ SG_ 1631 MO_DPF_reg "Regeneration Diesel-Partikel-Filter";
CM_ SG_ 1631 MO_Heizstrom_EKAT "Aktuelle Gesamtstromaufnahme des E-Katalysators";
CM_ SG_ 1631 MO_Heizstrom_SCR "Aktuelle Gesamtstromaufnahme der Tank-, Fördermodul- und Leitungsheizung des SCR-Systems";
CM_ SG_ 1631 MO_Testmode_AG "Status Prüfstandbetrieb des MSGs";
CM_ SG_ 1631 MO_Energieinhalt_BMS "Restenergieinhalt der Traktionsbatterie, beeinflusst durch Fahrstrategie und weiteren Faktoren der Antriebssteuerung.";
CM_ SG_ 1631 TSK_Fahrzeugmasse_02 "Neue Definition ab D4
Fahrzeugmasse in kg. Das Signal dient der Anpassung der Sollbeschleunigung vom ACC


";
CM_ SG_ 1631 TSK_Steigung_02 "Steigung in % Berg. Das Signal dient der Anpassung der Sollbeschleunigung vom ACC

Positive Werte > bergauf; 
Negative Werte < bergab

Fehler: Die Steigung aufgrund eines Fehlers (mit KD-Fehlereintrag) nicht mehr berechnet werden";
CM_ BO_ 1648 "Kombischnittstelle";
CM_ SG_ 1648 MO_max_Ladedruck "maximal möglicher Ladedruck (zur Anpassung des Anzeigebereichs bei absoluter Ladedruckanzeige)";
CM_ SG_ 1648 MO_ANC_Kennfeld_Anf "Anforderung ANC Kennfeldumschaltung";
CM_ SG_ 1648 MO_Bremslicht_Reku "Bremslicht (ggf. bei Rekuperation durch E-Motor) wird angesteuert";
CM_ SG_ 1648 MO_StartStopp_PopUp "Das Signal zeigt an, ob der StSt-Status mittels Deaktivierungstaster geändert wurde. Ein Wechsel auf die Werte 01 oder 10 löst im Kombi ein entsprechendes PopUp aus. Bei einem Statuswechsel durch andere Signalquellen (z.B. Charisma, fehlerbedingte Abschal";
CM_ SG_ 1648 MO1_Sperr_Info_WFS "WFS-Sperrinformation";
CM_ SG_ 1648 MO1_Freigabe_Info_WFS "WFS-Freigabeinformation";
CM_ SG_ 1648 MO_EPCL "Die Anforderung der EPC-Lampe vom MSG ans Kombi soll durch das Bus-Signal MO_EPCL gemäß folgender Logik erfolgen:
MO_EPCL = 0 dez -> EPC Lampe aus, kein Text
MO_EPCL = 1 dez -> gelbe EPC-Symbolik, Text „Antrieb: Störung! Bitte Service aufsuchen“
MO_EPC";
CM_ SG_ 1648 MO_Zylabsch_Texte_02 "ZAS-Anzeige für den Fahrer im Kombi
0: kein ZAS (generell keinerlei ZAS-Anzeigen)  (Init für nicht ZAS-Motor)
1: ZAS im Vollmotorbetrieb  (Init für ZAS-Motor)
2: ZAS im Abschaltbetrieb: 1 Zyl aktiv
3: ZAS im Abschaltbetrieb: 2 Zyl aktiv
4: ZAS im Abs";
CM_ SG_ 1648 MO_Fahrzeugtyp "Unterscheidet die Fahrzeugtypen bzgl. der Antriebsart";
CM_ SG_ 1648 MO_NMAX_Schaltanzeige "Maximaldrehzahl für Schaltanzeige";
CM_ SG_ 1648 MO_Abstellzeit "Abstelldauer nach letztem KL15 aus

Hinweis: 
Ehemaliger Fehlerwert 0xFF wird senderseitig nicht unterstützt. 
Diesen Wert aus Kompatibilitätsgründen nicht neu belegen!";
CM_ SG_ 1648 MO_Abstellzeit_Status "Statusinformation zur Abstellzeit
0: Die dem Status zugeordnete Variable konnte noch nicht berechnet werden. 
1: Die dem Status zugehörige Variable wurde korrekt berechnet. 
2: Der Wert der zugehörigen Variablen ist nur ein Minimalwert. 
3: Der Wert d";
CM_ SG_ 1648 MO1_Freigabe_Verfallsinfo_WFS "WFS-Freigabeverfallsinformation";
CM_ SG_ 1648 MO_Hybrid_StartStopp_LED "Ansteuerung der Funktions-LED der Hybrid Taste bzw. Start/Stop Deaktivierungstaste.
Der Start/Stopp-Master (derzeit im MSG) (oder ein künftiger Hybrid-Master) soll die Ansteuerung senden.";
CM_ SG_ 1648 MO_Fehler_Zylabsch "Fehlerstatus der Funktion Zylinderabschaltung ";
CM_ SG_ 1648 MO_Anzahl_Abgesch_Zyl "Gibt die Anzahl der abgeschalteten Zylinder an. In Übergangszuständen wird der Zielbetriebszustand angezeigt.";
CM_ SG_ 1648 MO_Zylabsch_Texte "Zylinderabschaltung mode in Kombi, fuer Zylinderabschaltung";
CM_ SG_ 1648 MO_Ethanol_BS_Texte "Ethanol Brennstoff-Texte im Kombi

0 = kein Text
1 = E85 Warm_Up
2 = FlexFuel Warnung 3.Stufe (Too cold for ethanol)
3 = Warmfahrempfehlung MQB / FlexFuel Warnung 1.Stufe (Refuel with gasoline)
4 = FlexFuel Warnung 2. Stufe (Refuel with gasoline)
5";
CM_ SG_ 1648 MO_Drehzahl_Warnung "Warnhinweis zum Kombi im Fall einer fehlerbehafteten Drehzahlbegrenzung";
CM_ SG_ 1648 MO_obere_Drehzahlgrenze "obere Drehzahlgrenze des Motors";
CM_ SG_ 289 Motor_20_CRC "Für MLB:
'Berechnung siehe Lastenheft 'Kommunikationsabsicherung für FlexRay und CAN''

Ab MQB und MLBevo:
'Berechnung siehe Lastenheft 'End-to-End Kommunikationsabsicherung'

Endwerte siehe Begleitdokument 'S-PDU Kennungsfolgen'";
CM_ SG_ 289 MO_Fahrpedalrohwert_01 "AUDI D4: Zykluszeit: 10ms (siehe Zykluszeit schnell/Cycletime Fast)

Stellung des Fahrpedales (Rohwert, ohne Überlagerung durch GRA-Eingriffe etc.)

Die Funktionen zur Berechung des Fahrpedalrohwerts laufen im 10ms Raster. Der Fahrpedalwert berechnet ";
CM_ SG_ 289 MO_QBit_Fahrpedalwerte_01 "AUDI D4: Zykluszeit: 10ms (siehe Zykluszeit schnell/Cycletime Fast)

QBit für beide Fahrpedalwerte des Motors (Fahrpedalrohsignal für ESP, EPB, ACC; Fahrpedalwert für Getriebe)

Achtung:
Reduktion der Zykluszeit Motor_03 auf 10ms geplant.
Projektabh";
CM_ SG_ 289 MO_Fahrpedalgradient "Das Motorsteuergerät besitzt 2 analoge Fahrpedalsignale. Das Signal des ersten Kanals wird alle 4ms abgetastet. Um Bitschwankungen des A/D-Wandler herauszufiltern wird das Signal entjittert. Anschließend wird der Gradient berechnet. Entsprechend der Zyklu";
CM_ SG_ 289 MO_Sig_Fahrpedalgradient "Kennzeichnet das Vorzeichen des Signal 'Fahrpedalgradient'. Die Ausgabe erfolgt nur parallel statisch mit gesendetem Signal: 'Steuerungsbit Fahrpedalgradient' ";
CM_ SG_ 289 MO_rel_Saugrohrdruck "Der Wert gibt an, um wieviel mbar der Saugrohrdruck unterhalb des Umgebungsdrucks liegt. Überdruck im Saugrohr wird nicht ausgegeben.
0: Saugrohrdruck=Umgebungsdruck";
CM_ SG_ 289 MO_rel_Saugrohrdruck_gem_err "0: mind. eine Modellrechnung wird zur Berechnung des relativen Saugdrucks herangezogen
1: Relativer Saugrohrdruck wird ausschließlich über Messgrößen bestimmt";
CM_ SG_ 289 MO_Moment_im_Leerlauf "Fahrerwunschmoment ist minimal: keine Momentenanforderung durch Fahrpedal, ACC oder GRA+; (Das Signal ist unabhängig von Momentenerhöhungen durch Leerlaufregler oder MSR).

AUDI D4: Zykluszeit: 10ms (siehe Zykluszeit schnell/Cycletime Fast)

Achtung:";
CM_ SG_ 289 MO_Schubabschaltung "ESP plausibilisiert Unterdrucksensor nur bei aktiver Schubabschaltung";
CM_ SG_ 289 MO_StartStopp_StoppVorbereitung "Zeigt allen aktiven Start-/Stoppteilnehmern einen möglichen Motorstopp im Anhaltevorgang an (Empfänger notwendige Vorbereitungen treffen)
Es liegen keine Vetos vor.";
CM_ SG_ 289 MO_Solldrehz_Leerlauf "Leerlaufsolldrehzahl, die im Motor eingestellt ist (Bei Parallelhybrid im E-Fahr-Betrieb Leerlaufsolldrehzahl der E-Maschine). Der Motor paßt aufgrund der Anforderung von anderen Steuergeräten seine Leerlaufsolldrehzahl an, bspw. Kat-Heizen, Anforderung v";
CM_ SG_ 289 MO_Entkopplung_Sollschlupf "MSG fordert von GSG an, das Anfahrelement (Fahr-/Wandlerkupplung) zu entkoppeln; das GSG soll die gesendete Drehzahl als Schlupf einstellen und ggf. die Regler-Parameter umschalten, damit Rucke aus dem Antrieb nicht im Fahrzeug spürbar werden; nutzbar z.B";
CM_ SG_ 289 MO_temporaere_Fahrerabwesenheit "Das Signal dient zur Signalisierung einer temporären Abwesenheit des Fahrers. In dieser Zeit ist es ihm möglich, sich durch gewisse ¿ im Verlassenskonzept definierte ¿ Fahreraktionen im aktuellen Fahrzyklus zurückzumelden.
Das Signal wird gesetzt, sobald";
CM_ SG_ 289 TSK_a_Soll_gradientenbegrenzt "TSK Sollbeschleunigung für Fahrerassistenzsysteme mit aktiver Längsführung (GRA, ACC, IPA...). Der Wert stellt den ruckbegrenzten Sollwert der TSK-Regelung dar und ist Basis der TSK-Antriebs- und Bremsmomentenvorsteuerung.";
CM_ SG_ 283 MO_Fahrbereitschaft "Das Signal MO_Fahrbereitschaft zeigt in mehreren Stufen an, ob der Motor in einem anfahrbereiten Zustand ist.";
CM_ SG_ 283 MO_Freilauf_Info "Freilauf Informationssignal vom Motorsteuergerät zum Getriebesteuergerät. Das Motorsteuergerät kann über dieses Signal den Freilauf freigeben, verhindern bzw. explizit anfordern.";
CM_ SG_ 283 MO_EnergyAssist_Aktivierbar "Das Signal MO_AEA_Aktivierbarkeit zeigt an, ob die Routenführung in der Navigation aktiv ist, die Longrange-PSD übertragen werden und der Audi energy assist aktivierbar ist.";
CM_ SG_ 283 MO_Krit_Heckobjekt "Beschreibt die Kritikalität des hinter einem in der Spur fahrenden Fahrzeuges";
CM_ SG_ 283 MO_NGS_Gangpos "Gang- bzw. Neutralinformation des erweiterten Neutralgangsensors. Bedingt durch den eingeschränkten Erfassungssbereich des Sensors sind die Ganginformationen als eingelegt bzw. fast eingelegt/vorausgewählt zu interpretieren (nur Handschalter)";
CM_ BO_ 1601 "ab MQB mit CRC-8";
CM_ SG_ 1601 Motor_Code_01_CRC "Für MLB:
'Berechnung siehe Lastenheft 'Kommunikationsabsicherung für FlexRay und CAN''

Ab MQB und MLBevo:
'Berechnung siehe Lastenheft 'End-to-End Kommunikationsabsicherung''

Endwerte siehe Begleitdokument 'S-PDU Kennungsfolgen'";
CM_ SG_ 1601 MO_Faktor_Momente_02 "Dieses Signal schaltet den Wertebereich aller Momente vom Motor, Getriebe, TSK, Bremse ... um! Die Momente besitzen somit einen variablen Wertebereich, weil sich durch den Faktor die Momente sowohl in Auflösung als auch Maximalwerten ändert.

0x0 nicht ";
CM_ SG_ 1601 MO_Hybridfahrzeug "Anhand dieses Signals plausibilisiert die Lenkhilfe das Bit Fahrbereitschaft.

Im Projekt Cayenne PHEV (und ggf. auch VW526 PHEV) ist aus Gründen der Abwärtskompatibilität der Wert '2' zu senden.";
CM_ SG_ 1601 MO_Code "Motorcodierinformation Version 7";
CM_ SG_ 1601 MO_Getriebe_Code "Getriebecodierung des Motors";
CM_ SG_ 1601 MO_StartStopp_Codiert "Funktion StartStopp im aktuellen Klemmenzyklus verbaut";
CM_ SG_ 1601 MO_Anzeige_StSt_gueltig "Zeigt die Gültigkeit der neuen StSt-Anzeigesignale an, MO_Anzeige_StSt_Text und  MO_Anzeige_Symbol. Mo_Text_Motorstart 1..5 sind zu ignorieren.";
CM_ SG_ 1601 MO_Anzahl_Zyl "Zylinderzahl des Verbrennungsmotors";
CM_ SG_ 1601 MO_Kraftstoffart "Primärkraftstoff zum Antrieb des Fahrzeugs";
CM_ SG_ 1601 MO_Hubraum "Hubraum des Verbrennungsmotors";
CM_ SG_ 1601 MO_Ansaugsystem "Art des Ansaugsystems des Verbrennungsmotors";
CM_ SG_ 1601 MO_Leistung "Nennleistung des Verbrennungsmotors";
CM_ SG_ 1601 MO_OBD_Typ "Abgastyp OBD";
CM_ SG_ 1601 MO_DPF_verbaut "Verbauinformation Diesel-Partikel-Filter
";
CM_ SG_ 1601 TSK_Codierung "Information über den plausibilisierten Codierungszustand des Triebstrangskoordinators auf ACC oder GRA.";
CM_ SG_ 2600468496 NM_Gateway_SNI "Source Node-Identifier (SNI) identifiziert den Sender der NM-Botschaft (Knotenadresse) eindeutig im Fahrzeug";
CM_ SG_ 2600468496 NM_Gateway_NM_State "1 = Zustand Repeat Message (<-- Bus-Sleep Mode)
2 = Zustand Repeat Message (<-- Prepare Bus-Sleep Mode)
4 = Zustand Normal Operation (<-- Repeat Message)
8 = Zustand Normal Operation (<-- Ready Sleep)
16 = Zustand Repeat Message (<-- Ready Sleep)
32 ";
CM_ SG_ 2600468496 NM_Gateway_Car_Wakeup "Car Wakeup (Subbusmaster wertet aus)
MQB: Diagnose- oder Komponentenschutzmaster-Funktion weckt den schlafenden Subbus (z.B. MOST)";
CM_ SG_ 2600468496 NM_Gateway_Wakeup "enthält die Weckursache; stehen mehrere Weckursachen parallel an, dann muss der kleinste Wert übertragen werden";
CM_ SG_ 2600468496 NM_Gateway_NM_aktiv_KL15 "Steuergerät hat KL15-EIN erkannt";
CM_ SG_ 2600468496 NM_Gateway_NM_aktiv_Diagnose "Diagnose befindet sich nach VW80124 in einer NonDefaultDiagnostic-Session, z.B. ExtendedDiagnostic-Session";
CM_ SG_ 2600468496 NM_Gateway_NM_aktiv_Tmin "Mindestaktivzeit ist noch nicht abgelaufen (bei jedem Weckereignis wird die Mindestaktivzeit neu gestartet)";
CM_ SG_ 2600468496 NM_Gateway_ACAN_Aktivitaet "Dieser Bus wird auf Grund einer Aktivität auf dem Antriebs-CAN wachgehalten (Buskopplung, CAR-Wakeup)";
CM_ SG_ 2600468496 NM_Gateway_FCAN_Aktivitaet "Dieser Bus wird auf Grund einer Aktivität auf dem Fahrwerks-CAN wachgehalten (Buskopplung, CAR-Wakeup)";
CM_ SG_ 2600468496 NM_Gateway_KCAN_Aktivitaet "Dieser Bus wird auf Grund einer Aktivität auf dem Komfort-CAN wachgehalten (Buskopplung, CAR-Wakeup)";
CM_ SG_ 2600468496 NM_Gateway_ICAN_Aktivitaet "Dieser Bus wird auf Grund einer Aktivität auf dem Infotainment-CAN wachgehalten (Buskopplung, CAR-Wakeup)";
CM_ SG_ 2600468496 NM_Gateway_DiagCAN_Aktivitaet "Dieser Bus wird auf Grund einer Aktivität auf dem Diagnose-CAN wachgehalten (Buskopplung, CAR-Wakeup)";
CM_ SG_ 2600468496 NM_Gateway_ECAN_Aktivitaet "Dieser Bus wird auf Grund einer Aktivität auf dem Extended-CAN wachgehalten (Buskopplung, CAR-Wakeup)";
CM_ SG_ 2600468496 NM_Gateway_EnergieLIN_Aktivitaet "Dieser Bus wird auf Grund einer Aktivität auf dem Energie-LIN wachgehalten (Buskopplung, CAR-Wakeup)";
CM_ SG_ 2600468496 NM_Gateway_Bedien_LIN_Aktivitaet "Dieser Bus wird auf Grund einer Aktivität auf dem Bedien-LIN wachgehalten (Buskopplung, CAR-Wakeup)";
CM_ SG_ 2600468496 NM_Gateway_EM_Aktivitaet "Dieser Bus wird auf Grund einer Aktivität des Energiemanagements wachgehalten";
CM_ SG_ 2600468496 NM_Gateway_KS_Aktivitaet "Dieser Bus wird auf Grund einer Aktivität des Komponentenschutzes (IKA-Runde) wachgehalten.";
CM_ SG_ 2600468496 NM_Gateway_HVEM_aktiv "Hochvoltenergiemanagement hält ACAN im MQB E wach.
Mögliche Gründe z. B. Ladesteckerentriegelung bei Fahrzeugentriegelung, autonomes Nachladen NV, ...";
CM_ SG_ 2600468496 NM_Gateway_NL_EM "lokale / interne Aktivität vor WakeUp: Energiemanagement";
CM_ SG_ 2600468496 NM_Gateway_NL_Shutdown "lokale / interne Aktivität vor WakeUp: Shutdown";
CM_ SG_ 2600468496 NM_Gateway_NL_Spg_Messung "lokale / interne Aktivität vor WakeUp: Spannungsmessung";
CM_ SG_ 2600468496 NM_Gateway_NL_Wakeup_Monitor "lokale / interne Aktivität vor WakeUp: Wakeup Monitor";
CM_ SG_ 2600468496 NM_Gateway_UDS_CC "Funktionseinschränkung aufgrund aktivem UDS-Communication Control; siehe VW80124";
CM_ SG_ 2600468564 NM_LWRAFS_SNI "Das Signal beinhaltet den Source Node Identifier (Knotenadresse, die auch in der Abbildungsvorschrift zur CAN-ID für die NM-High Botschaft verwendet wird).";
CM_ SG_ 2600468564 NM_LWRAFS_NM_State "1 = Zustand Repeat Message (<-- Bus-Sleep Mode)
2 = Zustand Repeat Message (<-- Prepare Bus-Sleep Mode)
4 = Zustand Normal Operation (<-- Repeat Message)
8 = Zustand Normal Operation (<-- Ready Sleep)";
CM_ SG_ 2600468564 NM_LWRAFS_Car_Wakeup "Car Wakeup (Gateway wertet aus)";
CM_ SG_ 2600468564 NM_LWRAFS_Wakeup "enthält die Weckursache; stehen mehrere Weckursachen parallel an, dann muss der kleinste Wert übertragen werden";
CM_ SG_ 2600468564 NM_LWRAFS_NM_aktiv_KL15 "Steuergerät hat KL15-EIN erkannt";
CM_ SG_ 2600468564 NM_LWRAFS_NM_aktiv_Diagnose "Diagnose bei Kl 15 aus (Nachlaufursache, nicht 'Ready Sleep')";
CM_ SG_ 2600468564 NM_LWRAFS_NM_aktiv_Tmin "Mindestaktivzeit ist noch nicht abgelaufen (bei jedem Weckereignis wird die Mindestaktivzeit neu gestartet)";
CM_ SG_ 2600468564 NM_LWRAFS_NM_aktiv_Versorgung "Funktionsnachlauf Versorgungsspannung aktiv (z. B. wg. Quittierungsblinken ZV)";
CM_ SG_ 2600468564 NM_LWRAFS_UDS_CC "Funktionseinschränkung aufgrund aktivem UDS-Communication Control; siehe VW80124";
CM_ BO_ 1175 "neue Struktur ab MQB ohne KD-Fehler";
CM_ SG_ 1175 PH_Visualisierung "Signal zeigt den Partnersteuergeräten RearView/TopView/ARA/... den aktuellen Status der Visualisierung des OPS. Die Partnersteuergeräte können dadurch auch ihre Aufschaltung an dieses Signal koppeln.";
CM_ SG_ 1175 PDC_Tonausgabe_Front "In Abhängigkeit der Systemaktivitäten werden unterschiedliche Tonwarnungen ausgegeben. 
Kombi spielt entsprechende WAV.-Datei über internen Audiomaster ab.

0 = kein Ton
1 = Intervallton 1
2 = Intervallton 2
3 = Intervallton 3
4 = Intervallton 4
5";
CM_ SG_ 1175 PDC_Tonausgabe_Heck "In Abhängigkeit der Systemaktivitäten werden unterschiedliche Tonwarnungen ausgegeben. 
Kombi spielt entsprechende WAV.-Datei über internen Audiomaster ab.

0 = kein Ton
1 = Intervallton 1
2 = Intervallton 2
3 = Intervallton 3
4 = Intervallton 4
5";
CM_ SG_ 1175 PH_nachtr_Stopp_Anf "Dieses Signal dient dem Motor als Trigger, dass ein nachträglicher Motorstopp eingeleitet werden kann, wenn es die Bedingungen des StSt Koordinators dies zulassen. ";
CM_ SG_ 1175 PH_Abschaltursache "Abschaltursache bleibt bis zur nächsten Aktivierung bzw. bis KL15 aus gesetzt
Im Fehlerfall (blinkende LED) wird '7' gesendet obwohl das System noch aktiv ist, bei 'geheiltem' Fehler wird sofort wieder der Zustand '0' gesendet";
CM_ SG_ 1175 PH_Opt_Anzeige_V_ein "OPS vorne ist im Display aktiv bzw. Anzeigemodule vorne sind eingeschaltet. Funktion nur bei gesicherter Rückmeldung vom ASG gegeben.";
CM_ SG_ 1175 PH_Opt_Anzeige_H_ein "OPS hinten ist im Display aktiv bzw. Anzeigemodule hinten sind eingeschaltet. Funktion nur bei gesicherter Rückmeldung vom ASG gegeben.";
CM_ SG_ 1175 PH_Opt_Anz_V_Hindernis "mindestens 1 Segment wird für den vorderen Detekionsbereich dargestellt, also ein Hindernis ist im Detektionsbereich. Funktion nur bei gesicherter Rückmeldung vom ASG gegeben.";
CM_ SG_ 1175 PH_Opt_Anz_H_Hindernis "mindestens 1 Segment wird für den hinteren Detekionsbereich dargestellt, also ein Hindernis ist im Detektionsbereich. Funktion nur bei gesicherter Rückmeldung vom ASG gegeben.";
CM_ SG_ 1175 PH_Tongeber_V_aktiv "Rohsignal für 'Tongeber vorne wird angesteuert', verlängerbar mit Nachlauftimer.
Bit wird nicht während des Stellgliedtests angesteuert.";
CM_ SG_ 1175 PH_Tongeber_H_aktiv "Rohsignal für 'Tongeber hinten wird angesteuert', verlängerbar mit Nachlauftimer.
Bit wird nicht während des Stellgliedtests angesteuert.";
CM_ SG_ 1175 PH_Tongeber_mute "Die Akustikausgabe des Systems wird unterdrückt, z.B. Wählhebel in 'P', Parlbremse geschlossen (8-Kanal-System)";
CM_ SG_ 1175 PH_Anf_Audioabsenkung "Es gibt zwei unterschiedliche Nachlauftimer für dieses Bit:
1. normale Funktion
2. Demotonausgabe";
CM_ SG_ 1175 PH_Tongeber_H_verfuegbar "Tongeber ist für die Tonausgabe für externe Funktionen verfügbar. PDC ist aktiv und Tongeber ist nicht gestört.";
CM_ SG_ 1175 PLA_Anf_Aufschaltung_RVC "Anforderung der Aufschaltung RVC durch PLA";
CM_ SG_ 1175 PH_Taster "Taster Status (für RVC/TopView)";
CM_ SG_ 1175 PH_Anf_Verdeck "Anforderung an ein Verdeck-System, die vom Fahrer angeforderte Öffnung/Schließung zu verhindern";
CM_ SG_ 1175 PH_Frequenz_hinten "Uebertragung der aktuell im APS Steuergeraet gespeicherten Werte fuer Tongeber Frequenz hinten
Anzeige der aktuell verwendeten Parameter (nicht zwingend die abgespeicherten - da Werte erst 2s nach der letzten Änderung gespeichert werden!)";
CM_ SG_ 1175 PH_Lautstaerke_hinten "Uebertragung der aktuell im APS Steuergeraet gespeicherten Werte fuer Tongeber Lautstaerke hinten
Anzeige der aktuell verwendeten Parameter (nicht zwingend die abgespeicherten - da Werte erst 2s nach der letzten Änderung gespeichert werden!)";
CM_ SG_ 1175 PH_Frequenz_vorn "Uebertragung der aktuell im APS Steuergeraet gespeicherten Werte fuer Tongeber Frequenz vorne
Anzeige der aktuell verwendeten Parameter (nicht zwingend die abgespeicherten - da Werte erst 2s nach der letzten Änderung gespeichert werden!)";
CM_ SG_ 1175 PH_Lautstaerke_vorn "Uebertragung der aktuell im APS Steuergeraet gespeicherten Werte fuer Tongeber Lautstaerke vorn.
Anzeige der aktuell verwendeten Parameter (nicht zwingend die abgespeicherten - da Werte erst 2s nach der letzten Änderung gespeichert werden!)";
CM_ SG_ 1175 PH_StartStopp_Info "Stopp-Freigabe und Start-Anforderung an den Start-Stopp-Koordinator";
CM_ SG_ 1175 PH_Stoermeldung "Meldung einer Störung der PDC an das Kombi";
CM_ SG_ 1175 PH_defekt "Zeigt an das sich die Parkhilfe im Fehlerzustand befindet. Signal bleibt bis zur nächsten 'Gut-Aktivierung' gesetzt.
Spezialfall: Sensordefekt hinten bei Anhängerbetrieb. Anhänger wird abgesteckt Fehler wird gesetzt. Fehlerfall bleibt bis Behebung des De";
CM_ SG_ 1175 PH_gestoert "Eine Störung ist aufgetreten, der die Parkhilfe in einen 'gestört-Zustand' versetzt, z.B. massiver Fremdultraschall, Vereisung, Schnee.Derzeit nur für Störschall benutzt, da keinerlei andere Erkennung implementiert.";
CM_ SG_ 1175 PH_Systemzustand "Aktivierungsursache wird für die Dauer der Aktivierung gemeldet.
Im Fehlerfall bei atkviem System wechselt das Signal auf '7'
(siehe auch 'Abschaltursache')";
CM_ SG_ 1175 PH_Display_Kundenwunsch "Anzeige der bei Aktivierung verwendeten Parameter bzgl. Kundenwunsch Displayanziege. Änderungen werden erst bei erneuter Aktivierung aktualisiert.";
CM_ BO_ 1351 "neue Struktur ab MQB ohne KD-Fehler";
CM_ SG_ 1351 US_Objekt_links "Signal gibt an, ob während der Fahrt über Ultraschall an der Flanke links ein Objekt erkannt wurde. Für lange Fahrzeuge (wie Crafter) soll die Information genutzt werden, um die Totwinkelüberwachung zu verbessern.";
CM_ SG_ 1351 US_Objekt_rechts "Signal gibt an, ob während der Fahrt über Ultraschall an der Flanke links ein Objekt erkannt wurde. Für lange Fahrzeuge (wie Crafter) soll die Information genutzt werden, um die Totwinkelüberwachung zu verbessern.";
CM_ SG_ 1351 US_Objektueberwachung_Status "Status der Ultraschallobjektüberwachung während der Fahrt. Während der Fahrt sollen dynamische Objekte über Ultraschall erkannt werden, um bei langen Fahrzeugen die Totwinkelüberwachung zu stützen. Im Stand/außerhalb gültiger Geschwindigkeit ist die Funkt";
CM_ SG_ 2527679498 Perso_Kontonummer "Signal gibt die jewels aktuelle Kontonummer für die Personalisierung an.
Nicht für AU736 und AU48x.";
CM_ SG_ 2527679498 Perso_Steuerung "Signal gibt einen Steuerungsbefehl an die Funktionsteilnehmer der Personalisierung.
Nicht für AU736 und AU49x.";
CM_ SG_ 2527679498 Perso_Steuerungsparameter "Signal gibt einen Parameter zum Steuerungsbefehl (Signal Perso_Steuerung) für die Personalisierung an.
Nicht für AU736 und AU49x.";
CM_ SG_ 2527679498 Perso_Status "Codierstatus der Personalisierung
Nicht für AU736 und AU49x.";
CM_ SG_ 2527679498 Perso_Bedienstelle "Signal zeigt an, über welche Bedienstelle die Umschaltung des Benutzerkontos gestartet wurden.";
CM_ SG_ 2527679498 Perso_Freigabe_Verstellung "Signal zeigt an, ob die Ergonomiefunktionen nach Umschaltung des Benutzerkontos verfahren dürfen.";
CM_ SG_ 2527679498 Perso_Aktiv "Status Personalisierung für den Fahrer aktiviert/ deaktiviert (via HMI)";
CM_ BO_ 929 "Auf diese Botschaft darf bis auf Weiteres keine Botschaftsüberwachung durchgeführt werden (unsicherer Quellbus).";
CM_ SG_ 929 PSD_Pos_Segment_ID "Identifier des Streckensegments, auf dem sich das Fahrzeug aktuell befindet
";
CM_ SG_ 929 PSD_Pos_Segmentlaenge "Verbleibende Länge des Streckensegments, auf dem sich das Fahrzeug aktuell befindet
";
CM_ SG_ 929 PSD_Pos_Inhibitzeit "Zeitspanne zwischen Generierung der PSD Daten im Navigationssystem und Versand der Daten auf den Most
";
CM_ SG_ 929 PSD_Segment_ID "Identifier des prädiktiven Streckensegments
";
CM_ SG_ 929 PSD_Vorgaenger_Segment_ID "An dem Streckensegment mit diesem Identifier schließt sich das neue Segment mit der ID 'PSD_01_Segment_ID' an.
";
CM_ SG_ 929 PSD_Strassenklasse "Die Klassifizierung der Straße";
CM_ SG_ 929 PSD_Segmentlaenge "Gesamtlänge des prädiktiven Streckensegments";
CM_ SG_ 929 PSD_Endkruemmung "'Endkrümmung der Klotoide des übermittelten Streckensegments. Die Anfangskrümmung des folgenden Streckensegments entspricht der Endkrümmung dieses Segments. Krümmung = 1/(1+0.155 * x²) [1/m]

";
CM_ SG_ 929 PSD_Endsteigung "Endsteigung des Streckensegments. ";
CM_ SG_ 929 PSD_ADAS_Qualitaet "ADAS Qualtität des Streckensegments.";
CM_ SG_ 929 PSD_Fahrspuren "Fahrspuren in Fahrtrichtung
";
CM_ SG_ 929 PSD_wahrscheinlichster_Pfad "Identifiziert den vom Navigationssystem berechneten wahrscheinlichsten Pfad des Fahrzeuges. ";
BA_DEF_ BO_  "DiagRequest" ENUM  "No","Yes";
BA_DEF_ BO_  "DiagResponse" ENUM  "No","Yes";
BA_DEF_ BO_  "DiagState" ENUM  "No","Yes";
BA_DEF_ BO_  "GenMsgChkConstant" HEX 0 4095;
BA_DEF_ BO_  "GenMsgCycleTime" INT 0 65535;
BA_DEF_ BO_  "GenMsgCycleTimeFast" INT 0 65535;
BA_DEF_ BO_  "GenMsgDelayTime" INT 0 100000;
BA_DEF_ BO_  "GenMsgILSupport" ENUM  "No","Yes";
BA_DEF_ BO_  "GenMsgNrOfRepetition" INT 0 100;
BA_DEF_ BO_  "GenMsgPDUConstants" STRING ;
BA_DEF_ BO_  "GenMsgSendType" ENUM  "Cyclic","not_used","not_used","not_used","not_used","not_used","not_used","IfActive","NoMsgSendType";
BA_DEF_ BO_  "GenMsgStartDelayTime" INT 0 100000;
BA_DEF_ BO_  "NmMessage" ENUM  "No","Yes";
BA_DEF_ BO_  "NmhMessage" ENUM  "No","Yes";
BA_DEF_ BO_  "MsgType" ENUM  "Application","NM ","NMH","TP2.0","ISO-TP ","BAP","EID","KS";
BA_DEF_ BO_  "VAGTP20_API" HEX 0 255;
BA_DEF_ BO_  "VAGTP20_DynConnection" ENUM  "No","Yes";
BA_DEF_ BO_  "VAGTP20_DynSetup" ENUM  "No","Yes";
BA_DEF_ BO_  "VAGTP20_StatConnection" ENUM  "No","Yes";
BA_DEF_ SG_  "GenSigActiveRepetitions" INT -2147483648 2147483647;
BA_DEF_ SG_  "GenSigInactiveValue" INT -2147483648 2147483647;
BA_DEF_ SG_  "GenSigSendType" ENUM  "Cyclic","OnWrite","OnWriteWithRepetition","OnChange","OnChangeWithRepetition","IfActive","IfActiveWithRepetition","NoSigSendType","OnChangeAndIfActive","OnChangeAndIfActiveWithRepetition";
BA_DEF_ SG_  "GenSigStartValue" INT -2147483648 2147483647;
BA_DEF_ SG_  "NWM-WakeupAllowed" ENUM  "No","Yes";
BA_DEF_ SG_  "GenSigFuncType" ENUM  "NoFunction","MsgCounter","CRC-8","XOR","XOR-2","DatedBit","SW-Kl15","CHK","Constant","Protocol","CRC-8-SAE_J1850";
BA_DEF_ SG_  "GenSigSwitchedByIgnition" ENUM  "No","Yes";
BA_DEF_ SG_  "Fehlerwert" HEX 0 2147483647;
BA_DEF_ SG_  "GenSigMissingSourceValue" HEX 0 2147483647;
BA_DEF_REL_ BU_SG_REL_  "GenSigTimeoutTime" INT 0 65535;
BA_DEF_DEF_REL_ "GenSigTimeoutTime" 0;
BA_DEF_DEF_  "DiagRequest" "No";
BA_DEF_DEF_  "DiagResponse" "No";
BA_DEF_DEF_  "DiagState" "No";
BA_DEF_DEF_  "GenMsgChkConstant" 0;
BA_DEF_DEF_  "GenMsgCycleTime" 0;
BA_DEF_DEF_  "GenMsgCycleTimeFast" 0;
BA_DEF_DEF_  "GenMsgDelayTime" 0;
BA_DEF_DEF_  "GenMsgILSupport" "No";
BA_DEF_DEF_  "GenMsgNrOfRepetition" 0;
BA_DEF_DEF_  "GenMsgPDUConstants" "";
BA_DEF_DEF_  "GenMsgSendType" "NoMsgSendType";
BA_DEF_DEF_  "GenMsgStartDelayTime" 0;
BA_DEF_DEF_  "NmMessage" "No";
BA_DEF_DEF_  "NmhMessage" "No";
BA_DEF_DEF_  "MsgType" "Application";
BA_DEF_DEF_  "VAGTP20_API" 0;
BA_DEF_DEF_  "VAGTP20_DynConnection" "No";
BA_DEF_DEF_  "VAGTP20_DynSetup" "No";
BA_DEF_DEF_  "VAGTP20_StatConnection" "No";
BA_DEF_DEF_  "GenSigActiveRepetitions" 0;
BA_DEF_DEF_  "GenSigInactiveValue" 0;
BA_DEF_DEF_  "GenSigSendType" "NoSigSendType";
BA_DEF_DEF_  "GenSigStartValue" 0;
BA_DEF_DEF_  "NWM-WakeupAllowed" "No";
BA_DEF_DEF_  "GenSigFuncType" "NoFunction";
BA_DEF_DEF_  "GenSigSwitchedByIgnition" "Yes";
BA_DEF_DEF_  "Fehlerwert" 0;
BA_DEF_DEF_  "GenSigMissingSourceValue" 0;
BA_ "GenMsgSendType" BO_ 134 0;
BA_ "GenMsgPDUConstants" BO_ 134 "0x86,0x86,0x86,0x86,0x86,0x86,0x86,0x86,0x86,0x86,0x86,0x86,0x86,0x86,0x86,0x86";
BA_ "GenMsgILSupport" BO_ 134 1;
BA_ "GenMsgCycleTime" BO_ 134 10;
BA_ "GenMsgChkConstant" BO_ 134 134;
BA_ "GenMsgSendType" BO_ 917 0;
BA_ "GenMsgILSupport" BO_ 917 1;
BA_ "GenMsgDelayTime" BO_ 917 10;
BA_ "GenMsgCycleTime" BO_ 917 100;
BA_ "GenMsgSendType" BO_ 295 0;
BA_ "GenMsgILSupport" BO_ 295 1;
BA_ "GenMsgCycleTime" BO_ 295 20;
BA_ "GenMsgSendType" BO_ 846 0;
BA_ "GenMsgILSupport" BO_ 846 1;
BA_ "GenMsgCycleTime" BO_ 846 40;
BA_ "GenMsgSendType" BO_ 847 0;
BA_ "GenMsgILSupport" BO_ 847 1;
BA_ "GenMsgCycleTime" BO_ 847 40;
BA_ "GenMsgSendType" BO_ 1721 0;
BA_ "GenMsgILSupport" BO_ 1721 1;
BA_ "GenMsgDelayTime" BO_ 1721 100;
BA_ "GenMsgCycleTime" BO_ 1721 1000;
BA_ "GenMsgSendType" BO_ 506 0;
BA_ "GenMsgILSupport" BO_ 506 1;
BA_ "GenMsgDelayTime" BO_ 506 10;
BA_ "GenMsgCycleTime" BO_ 506 100;
BA_ "GenMsgSendType" BO_ 1153 0;
BA_ "GenMsgILSupport" BO_ 1153 1;
BA_ "GenMsgDelayTime" BO_ 1153 50;
BA_ "GenMsgCycleTime" BO_ 1153 500;
BA_ "GenMsgSendType" BO_ 1600 0;
BA_ "GenMsgILSupport" BO_ 1600 1;
BA_ "GenMsgCycleTime" BO_ 1600 500;
BA_ "GenMsgSendType" BO_ 958 0;
BA_ "GenMsgPDUConstants" BO_ 958 "0x1f,0x28,0xc6,0x85,0xe6,0xf8,0xb0,0x19,0x5b,0x64,0x35,0x21,0xe4,0xf7,0x9c,0x24";
BA_ "GenMsgILSupport" BO_ 958 1;
BA_ "GenMsgDelayTime" BO_ 958 10;
BA_ "GenMsgCycleTime" BO_ 958 100;
BA_ "GenMsgSendType" BO_ 1631 0;
BA_ "GenMsgILSupport" BO_ 1631 1;
BA_ "GenMsgCycleTime" BO_ 1631 500;
BA_ "GenMsgSendType" BO_ 1648 0;
BA_ "GenMsgILSupport" BO_ 1648 1;
BA_ "GenMsgDelayTime" BO_ 1648 20;
BA_ "GenMsgCycleTime" BO_ 1648 500;
BA_ "GenMsgSendType" BO_ 289 0;
BA_ "GenMsgPDUConstants" BO_ 289 "0xe9,0x65,0xae,0x6b,0x7b,0x35,0xe5,0x5f,0x4e,0xc7,0x86,0xa2,0xbb,0xdd,0xeb,0xb4";
BA_ "GenMsgILSupport" BO_ 289 1;
BA_ "GenMsgCycleTime" BO_ 289 20;
BA_ "GenMsgSendType" BO_ 283 0;
BA_ "GenMsgILSupport" BO_ 283 1;
BA_ "GenMsgDelayTime" BO_ 283 10;
BA_ "GenMsgCycleTime" BO_ 283 100;
BA_ "GenMsgSendType" BO_ 1601 0;
BA_ "GenMsgPDUConstants" BO_ 1601 "0x47,0x47,0x47,0x47,0x47,0x47,0x47,0x47,0x47,0x47,0x47,0x47,0x47,0x47,0x47,0x47";
BA_ "GenMsgILSupport" BO_ 1601 1;
BA_ "GenMsgCycleTime" BO_ 1601 1000;
BA_ "GenMsgChkConstant" BO_ 1601 71;
BA_ "MsgType" BO_ 2600468496 2;
BA_ "NmhMessage" BO_ 2600468496 1;
BA_ "GenMsgCycleTime" BO_ 2600468496 200;
BA_ "MsgType" BO_ 2600468564 2;
BA_ "NmhMessage" BO_ 2600468564 1;
BA_ "GenMsgCycleTime" BO_ 2600468564 200;
BA_ "MsgType" BO_ 2549875287 4;
BA_ "DiagRequest" BO_ 2549875287 1;
BA_ "MsgType" BO_ 2550006359 4;
BA_ "DiagResponse" BO_ 2550006359 1;
BA_ "MsgType" BO_ 2549875248 4;
BA_ "DiagRequest" BO_ 2549875248 1;
BA_ "MsgType" BO_ 2550006320 4;
BA_ "DiagResponse" BO_ 2550006320 1;
BA_ "MsgType" BO_ 2549875279 4;
BA_ "DiagRequest" BO_ 2549875279 1;
BA_ "MsgType" BO_ 2550006351 4;
BA_ "DiagResponse" BO_ 2550006351 1;
BA_ "MsgType" BO_ 2549875330 4;
BA_ "DiagRequest" BO_ 2549875330 1;
BA_ "MsgType" BO_ 2550006402 4;
BA_ "DiagResponse" BO_ 2550006402 1;
BA_ "MsgType" BO_ 2549875331 4;
BA_ "DiagRequest" BO_ 2549875331 1;
BA_ "MsgType" BO_ 2550006403 4;
BA_ "DiagResponse" BO_ 2550006403 1;
BA_ "MsgType" BO_ 2549875350 4;
BA_ "DiagRequest" BO_ 2549875350 1;
BA_ "MsgType" BO_ 2550006422 4;
BA_ "DiagResponse" BO_ 2550006422 1;
BA_ "MsgType" BO_ 2549875351 4;
BA_ "DiagRequest" BO_ 2549875351 1;
BA_ "MsgType" BO_ 2550006423 4;
BA_ "DiagResponse" BO_ 2550006423 1;
BA_ "MsgType" BO_ 2549875284 4;
BA_ "DiagRequest" BO_ 2549875284 1;
BA_ "MsgType" BO_ 2550006356 4;
BA_ "DiagResponse" BO_ 2550006356 1;
BA_ "MsgType" BO_ 2549875278 4;
BA_ "DiagRequest" BO_ 2549875278 1;
BA_ "MsgType" BO_ 2550006350 4;
BA_ "DiagResponse" BO_ 2550006350 1;
BA_ "GenMsgSendType" BO_ 1175 0;
BA_ "GenMsgILSupport" BO_ 1175 1;
BA_ "GenMsgDelayTime" BO_ 1175 50;
BA_ "GenMsgCycleTime" BO_ 1175 100;
BA_ "GenMsgSendType" BO_ 1351 0;
BA_ "GenMsgILSupport" BO_ 1351 1;
BA_ "GenMsgDelayTime" BO_ 1351 20;
BA_ "GenMsgCycleTime" BO_ 1351 1000;
BA_ "GenMsgSendType" BO_ 2527679498 0;
BA_ "GenMsgNrOfRepetition" BO_ 2527679498 3;
BA_ "GenMsgILSupport" BO_ 2527679498 1;
BA_ "GenMsgDelayTime" BO_ 2527679498 50;
BA_ "GenMsgCycleTimeFast" BO_ 2527679498 200;
BA_ "GenMsgCycleTime" BO_ 2527679498 1000;
BA_ "GenMsgSendType" BO_ 929 0;
BA_ "GenMsgILSupport" BO_ 929 1;
BA_ "GenMsgCycleTime" BO_ 929 150;
BA_ "GenSigSwitchedByIgnition" SG_ 134 LWI_01_CRC 0;
BA_ "GenSigFuncType" SG_ 134 LWI_01_CRC 2;
BA_ "GenSigSendType" SG_ 134 LWI_01_CRC 0;
BA_ "GenSigFuncType" SG_ 134 LWI_01_BZ 1;
BA_ "GenSigSendType" SG_ 134 LWI_01_BZ 0;
BA_ "GenSigSendType" SG_ 134 LWI_Sensorstatus 0;
BA_ "GenSigSendType" SG_ 134 LWI_QBit_Sub_Daten 0;
BA_ "GenSigStartValue" SG_ 134 LWI_QBit_Lenkradwinkel 1;
BA_ "GenSigSendType" SG_ 134 LWI_QBit_Lenkradwinkel 0;
BA_ "Fehlerwert" SG_ 134 LWI_Lenkradwinkel 8191;
BA_ "GenSigStartValue" SG_ 134 LWI_Lenkradwinkel 8190;
BA_ "GenSigSendType" SG_ 134 LWI_Lenkradwinkel 0;
BA_ "GenSigSendType" SG_ 134 LWI_VZ_Lenkradwinkel 0;
BA_ "GenSigSendType" SG_ 134 LWI_VZ_Lenkradw_Geschw 0;
BA_ "Fehlerwert" SG_ 134 LWI_Lenkradw_Geschw 511;
BA_ "GenSigStartValue" SG_ 134 LWI_Lenkradw_Geschw 510;
BA_ "GenSigSendType" SG_ 134 LWI_Lenkradw_Geschw 0;
BA_ "GenSigSendType" SG_ 134 LWI_Sub_Daten 0;
BA_ "GenSigSendType" SG_ 917 AFS_Abbiegelicht_li_Anf 0;
BA_ "GenSigSendType" SG_ 917 AFS_Abbiegelicht_re_Anf 0;
BA_ "GenSigSendType" SG_ 917 AFS_Abbiegelicht_Dimm_Anf 0;
BA_ "GenSigStartValue" SG_ 917 AFS_Verfuegbarkeit_GLW 1;
BA_ "GenSigSendType" SG_ 917 AFS_Verfuegbarkeit_GLW 0;
BA_ "GenSigStartValue" SG_ 917 AFS_Status_adaptive_LV 1;
BA_ "GenSigSendType" SG_ 917 AFS_Status_adaptive_LV 0;
BA_ "GenSigSendType" SG_ 917 AFS_Fernlicht_li_defekt 0;
BA_ "GenSigSendType" SG_ 917 AFS_Fernlicht_re_defekt 0;
BA_ "GenSigSendType" SG_ 917 AFS_Fernlicht_Status 3;
BA_ "GenSigFuncType" SG_ 917 LWR_AFS_01_BZ 1;
BA_ "GenSigSendType" SG_ 917 LWR_AFS_01_BZ 0;
BA_ "GenSigSendType" SG_ 917 AFS_Lampe 0;
BA_ "GenSigSendType" SG_ 917 LWR_Lampe 0;
BA_ "GenSigSendType" SG_ 917 AFS_Fehlertext 0;
BA_ "GenSigSendType" SG_ 917 AFS_LED_Blinkmode 0;
BA_ "GenSigSendType" SG_ 917 LWR_Touristenmodus_aktiv 0;
BA_ "GenSigSendType" SG_ 917 AFS_Charisma_FahrPr 0;
BA_ "GenSigSendType" SG_ 917 AFS_Charisma_Status 0;
BA_ "GenSigSendType" SG_ 917 AFS_Allwetterlicht 0;
BA_ "GenSigSendType" SG_ 917 LWR_Touristenmodus_verbaut 0;
BA_ "GenSigSendType" SG_ 917 AFS_adaptive_LV_verbaut 0;
BA_ "GenSigSendType" SG_ 917 LWR_Reisemodus_Texte 0;
BA_ "GenSigSendType" SG_ 917 GLW_Sensor_blockiert 0;
BA_ "Fehlerwert" SG_ 917 LWR_Pos_Schrittmotor 255;
BA_ "GenSigStartValue" SG_ 917 LWR_Pos_Schrittmotor 254;
BA_ "GenSigSendType" SG_ 917 LWR_Pos_Schrittmotor 0;
BA_ "Fehlerwert" SG_ 917 LWR_Hoehenwert_VL 255;
BA_ "GenSigStartValue" SG_ 917 LWR_Hoehenwert_VL 254;
BA_ "GenSigSendType" SG_ 917 LWR_Hoehenwert_VL 0;
BA_ "Fehlerwert" SG_ 917 LWR_Hoehenwert_HL 255;
BA_ "GenSigStartValue" SG_ 917 LWR_Hoehenwert_HL 254;
BA_ "GenSigSendType" SG_ 917 LWR_Hoehenwert_HL 0;
BA_ "GenSigSendType" SG_ 917 AFS_Ersatzlicht_Links 0;
BA_ "GenSigSendType" SG_ 917 AFS_Ersatzlicht_Rechts 0;
BA_ "GenSigSendType" SG_ 917 LWR_AFS_Grundeinstellung 0;
BA_ "GenSigSendType" SG_ 917 LWR_AFS_Parametrisierung 0;
BA_ "GenSigSendType" SG_ 917 LWR_Initialisierungslauf 0;
BA_ "GenSigSendType" SG_ 917 LWR_Sicherheitsposition 0;
BA_ "GenSigSendType" SG_ 917 LWR_Modus 0;
BA_ "Fehlerwert" SG_ 295 LWR_Verstellwinkel_li 63;
BA_ "GenSigStartValue" SG_ 295 LWR_Verstellwinkel_li 62;
BA_ "GenSigSendType" SG_ 295 LWR_Verstellwinkel_li 0;
BA_ "Fehlerwert" SG_ 295 LWR_Verstellwinkel_re 63;
BA_ "GenSigStartValue" SG_ 295 LWR_Verstellwinkel_re 62;
BA_ "GenSigSendType" SG_ 295 LWR_Verstellwinkel_re 0;
BA_ "Fehlerwert" SG_ 295 AFS_Schwenkwinkel_li 255;
BA_ "GenSigStartValue" SG_ 295 AFS_Schwenkwinkel_li 254;
BA_ "GenSigSendType" SG_ 295 AFS_Schwenkwinkel_li 0;
BA_ "Fehlerwert" SG_ 295 AFS_Schwenkwinkel_re 255;
BA_ "GenSigStartValue" SG_ 295 AFS_Schwenkwinkel_re 254;
BA_ "GenSigSendType" SG_ 295 AFS_Schwenkwinkel_re 0;
BA_ "Fehlerwert" SG_ 295 AFS_Lichtverteilung_li 15;
BA_ "GenSigStartValue" SG_ 295 AFS_Lichtverteilung_li 14;
BA_ "GenSigSendType" SG_ 295 AFS_Lichtverteilung_li 0;
BA_ "Fehlerwert" SG_ 295 AFS_Lichtverteilung_re 15;
BA_ "GenSigStartValue" SG_ 295 AFS_Lichtverteilung_re 14;
BA_ "GenSigSendType" SG_ 295 AFS_Lichtverteilung_re 0;
BA_ "GenSigSendType" SG_ 295 AFS_Status_Verkehrsart 0;
BA_ "GenSigSendType" SG_ 295 GLW_Nebelregelung 0;
BA_ "GenSigSendType" SG_ 846 MXB_Status_Seg01 0;
BA_ "GenSigSendType" SG_ 846 MXB_Status_Seg02 0;
BA_ "GenSigSendType" SG_ 846 MXB_Status_Seg03 0;
BA_ "GenSigSendType" SG_ 846 MXB_Status_Seg04 0;
BA_ "GenSigSendType" SG_ 846 MXB_Status_Seg05 0;
BA_ "GenSigSendType" SG_ 846 MXB_Status_Seg06 0;
BA_ "GenSigSendType" SG_ 846 MXB_Status_Seg07 0;
BA_ "GenSigSendType" SG_ 846 MXB_Status_Seg08 0;
BA_ "GenSigSendType" SG_ 846 MXB_Status_Seg09 0;
BA_ "GenSigSendType" SG_ 846 MXB_Status_Seg10 0;
BA_ "GenSigSendType" SG_ 846 MXB_Status_Seg11 0;
BA_ "GenSigSendType" SG_ 846 MXB_Status_Seg12 0;
BA_ "GenSigSendType" SG_ 846 MXB_Status_Seg13 0;
BA_ "GenSigSendType" SG_ 846 MXB_Status_Seg14 0;
BA_ "GenSigSendType" SG_ 846 MXB_Status_Seg15 0;
BA_ "GenSigSendType" SG_ 846 MXB_Status_Seg16 0;
BA_ "GenSigSendType" SG_ 846 MXB_Status_Seg17 0;
BA_ "GenSigSendType" SG_ 846 MXB_Status_Seg18 0;
BA_ "GenSigSendType" SG_ 846 MXB_Status_Seg19 0;
BA_ "GenSigSendType" SG_ 846 MXB_Status_Seg20 0;
BA_ "GenSigSendType" SG_ 846 MXB_Status_Seg21 0;
BA_ "GenSigSendType" SG_ 846 MXB_Status_Seg22 0;
BA_ "GenSigSendType" SG_ 846 MXB_Status_Seg23 0;
BA_ "GenSigSendType" SG_ 846 MXB_Status_Seg24 0;
BA_ "GenSigSendType" SG_ 846 MXB_Status_Seg25 0;
BA_ "GenSigSendType" SG_ 846 MXB_Status_Seg26 0;
BA_ "GenSigSendType" SG_ 846 MXB_Status_Seg27 0;
BA_ "GenSigSendType" SG_ 846 MXB_Status_Seg28 0;
BA_ "GenSigSendType" SG_ 846 MXB_Status_Seg29 0;
BA_ "GenSigSendType" SG_ 846 MXB_Status_Seg30 0;
BA_ "GenSigSendType" SG_ 846 MXB_Status_Seg31 0;
BA_ "GenSigSendType" SG_ 846 MXB_Status_Seg32 0;
BA_ "GenSigSendType" SG_ 847 MXB_Status_Seg33 0;
BA_ "GenSigSendType" SG_ 847 MXB_Status_Seg34 0;
BA_ "GenSigSendType" SG_ 847 MXB_Status_Seg35 0;
BA_ "GenSigSendType" SG_ 847 MXB_Status_Seg36 0;
BA_ "GenSigSendType" SG_ 847 MXB_Status_Seg37 0;
BA_ "GenSigSendType" SG_ 847 MXB_Status_Seg38 0;
BA_ "GenSigSendType" SG_ 847 MXB_Status_Seg39 0;
BA_ "GenSigSendType" SG_ 847 MXB_Status_Seg40 0;
BA_ "GenSigSendType" SG_ 847 MXB_Status_Seg41 0;
BA_ "GenSigSendType" SG_ 847 MXB_Status_Seg42 0;
BA_ "GenSigSendType" SG_ 847 MXB_Status_Seg43 0;
BA_ "GenSigSendType" SG_ 847 MXB_Status_Seg44 0;
BA_ "GenSigSendType" SG_ 847 MXB_Status_Seg45 0;
BA_ "GenSigSendType" SG_ 847 MXB_Status_Seg46 0;
BA_ "GenSigSendType" SG_ 847 MXB_Status_Seg47 0;
BA_ "GenSigSendType" SG_ 847 MXB_Status_Seg48 0;
BA_ "GenSigSendType" SG_ 847 MXB_Status_Seg49 0;
BA_ "GenSigSendType" SG_ 847 MXB_Status_Seg50 0;
BA_ "GenSigSendType" SG_ 847 MXB_Status_Seg51 0;
BA_ "GenSigSendType" SG_ 847 MXB_Status_Seg52 0;
BA_ "GenSigSendType" SG_ 847 MXB_Status_Seg53 0;
BA_ "GenSigSendType" SG_ 847 MXB_Status_Seg54 0;
BA_ "GenSigSendType" SG_ 847 MXB_Status_Seg55 0;
BA_ "GenSigSendType" SG_ 847 MXB_Status_Seg56 0;
BA_ "GenSigSendType" SG_ 847 MXB_Status_Seg57 0;
BA_ "GenSigSendType" SG_ 847 MXB_Status_Seg58 0;
BA_ "GenSigSendType" SG_ 847 MXB_Status_Seg59 0;
BA_ "GenSigSendType" SG_ 847 MXB_Status_Seg60 0;
BA_ "GenSigSendType" SG_ 1721 MXB_horiz_Offset_li_SW 0;
BA_ "Fehlerwert" SG_ 1721 MXB_Status 3;
BA_ "GenSigStartValue" SG_ 1721 MXB_Status 2;
BA_ "GenSigSendType" SG_ 1721 MXB_Status 3;
BA_ "GenSigSendType" SG_ 1721 MXB_vert_Offset_li_SW 0;
BA_ "GenSigSendType" SG_ 1721 AFS_Abblendlicht_li_defekt 3;
BA_ "GenSigSendType" SG_ 1721 AFS_Abblendlicht_re_defekt 3;
BA_ "GenSigSendType" SG_ 1721 AFS_stat_Kurvenlicht_li_defekt 3;
BA_ "GenSigSendType" SG_ 1721 AFS_stat_Kurvenlicht_re_defekt 3;
BA_ "GenSigSendType" SG_ 1721 AFS_Tagfahrlicht_li_defekt 3;
BA_ "GenSigSendType" SG_ 1721 AFS_Tagfahrlicht_re_defekt 3;
BA_ "Fehlerwert" SG_ 1721 MXB_Allgemein_li_defekt 1;
BA_ "GenSigSendType" SG_ 1721 MXB_Allgemein_li_defekt 3;
BA_ "Fehlerwert" SG_ 1721 MXB_Allgemein_re_defekt 1;
BA_ "GenSigSendType" SG_ 1721 MXB_Allgemein_re_defekt 3;
BA_ "GenSigSendType" SG_ 1721 AFS_Zusatzfernlicht_li_defekt 3;
BA_ "GenSigSendType" SG_ 1721 AFS_Zusatzfernlicht_re_defekt 3;
BA_ "GenSigSendType" SG_ 1721 LED_Steuerung_li_defekt 3;
BA_ "GenSigSendType" SG_ 1721 LED_Steuerung_re_defekt 3;
BA_ "GenSigSendType" SG_ 1721 MXB_horiz_Offset_re_SW 0;
BA_ "GenSigSendType" SG_ 1721 MXB_vert_Offset_re_SW 0;
BA_ "Fehlerwert" SG_ 506 LCM_TFL_Fehler_L 1;
BA_ "GenSigSendType" SG_ 506 LCM_TFL_Fehler_L 0;
BA_ "Fehlerwert" SG_ 506 LCM_TFL_Fehler_R 1;
BA_ "GenSigSendType" SG_ 506 LCM_TFL_Fehler_R 0;
BA_ "Fehlerwert" SG_ 506 LCM_SM_Fehler_L 1;
BA_ "GenSigSendType" SG_ 506 LCM_SM_Fehler_L 0;
BA_ "Fehlerwert" SG_ 506 LCM_SM_Fehler_R 1;
BA_ "GenSigSendType" SG_ 506 LCM_SM_Fehler_R 0;
BA_ "Fehlerwert" SG_ 506 LCM_Shutter_Fehler_L 1;
BA_ "GenSigSendType" SG_ 506 LCM_Shutter_Fehler_L 0;
BA_ "Fehlerwert" SG_ 506 LCM_Shutter_Fehler_R 1;
BA_ "GenSigSendType" SG_ 506 LCM_Shutter_Fehler_R 0;
BA_ "Fehlerwert" SG_ 506 LCM_PO_Fehler_L 1;
BA_ "GenSigSendType" SG_ 506 LCM_PO_Fehler_L 0;
BA_ "Fehlerwert" SG_ 506 LCM_PO_Fehler_R 1;
BA_ "GenSigSendType" SG_ 506 LCM_PO_Fehler_R 0;
BA_ "Fehlerwert" SG_ 506 LCM_Blinker_Fehler_L 1;
BA_ "GenSigSendType" SG_ 506 LCM_Blinker_Fehler_L 0;
BA_ "Fehlerwert" SG_ 506 LCM_Blinker_Fehler_R 1;
BA_ "GenSigSendType" SG_ 506 LCM_Blinker_Fehler_R 0;
BA_ "GenSigSendType" SG_ 506 LCM_Blinker_L_Sta 3;
BA_ "GenSigSendType" SG_ 506 LCM_Blinker_R_Sta 3;
BA_ "Fehlerwert" SG_ 506 LCM_Datensatz_Fehler_L 1;
BA_ "GenSigSendType" SG_ 506 LCM_Datensatz_Fehler_L 0;
BA_ "Fehlerwert" SG_ 506 LCM_Datensatz_Fehler_R 1;
BA_ "GenSigSendType" SG_ 506 LCM_Datensatz_Fehler_R 0;
BA_ "Fehlerwert" SG_ 506 LCM_Abschaltbestaetigung_L 3;
BA_ "GenSigSendType" SG_ 506 LCM_Abschaltbestaetigung_L 0;
BA_ "Fehlerwert" SG_ 506 LCM_Abschaltbestaetigung_R 3;
BA_ "GenSigSendType" SG_ 506 LCM_Abschaltbestaetigung_R 0;
BA_ "GenSigFuncType" SG_ 506 LCM_Sta_LM_L_alt 5;
BA_ "GenSigStartValue" SG_ 506 LCM_Sta_LM_L_alt 1;
BA_ "GenSigSendType" SG_ 506 LCM_Sta_LM_L_alt 0;
BA_ "GenSigFuncType" SG_ 506 LCM_Sta_LM_R_alt 5;
BA_ "GenSigStartValue" SG_ 506 LCM_Sta_LM_R_alt 1;
BA_ "GenSigSendType" SG_ 506 LCM_Sta_LM_R_alt 0;
BA_ "GenSigFuncType" SG_ 506 LCM_Feh_LM_L_alt 5;
BA_ "GenSigStartValue" SG_ 506 LCM_Feh_LM_L_alt 1;
BA_ "GenSigSendType" SG_ 506 LCM_Feh_LM_L_alt 0;
BA_ "GenSigFuncType" SG_ 506 LCM_Feh_LM_R_alt 5;
BA_ "GenSigStartValue" SG_ 506 LCM_Feh_LM_R_alt 1;
BA_ "GenSigSendType" SG_ 506 LCM_Feh_LM_R_alt 0;
BA_ "GenSigSwitchedByIgnition" SG_ 1153 MMI_Counter_Bedienevent 0;
BA_ "GenSigSendType" SG_ 1153 MMI_Counter_Bedienevent 0;
BA_ "GenSigSwitchedByIgnition" SG_ 1153 DSSS_Warning 0;
BA_ "GenSigSendType" SG_ 1153 DSSS_Warning 3;
BA_ "GenSigSwitchedByIgnition" SG_ 1153 ZR_Kindersicherung_RSE 0;
BA_ "GenSigSendType" SG_ 1153 ZR_Kindersicherung_RSE 3;
BA_ "GenSigSwitchedByIgnition" SG_ 1153 ZR_RSE_aktivieren 0;
BA_ "GenSigSendType" SG_ 1153 ZR_RSE_aktivieren 3;
BA_ "GenSigSwitchedByIgnition" SG_ 1153 MMI_SDS_aktiv 0;
BA_ "GenSigSendType" SG_ 1153 MMI_SDS_aktiv 3;
BA_ "GenSigSwitchedByIgnition" SG_ 1153 MU_SecondDisplay 0;
BA_ "GenSigSendType" SG_ 1153 MU_SecondDisplay 3;
BA_ "GenSigSwitchedByIgnition" SG_ 1153 MMI_Gurt_Mic_ref 0;
BA_ "GenSigSendType" SG_ 1153 MMI_Gurt_Mic_ref 3;
BA_ "GenSigSwitchedByIgnition" SG_ 1153 ZR_Parken_Sondermodus 0;
BA_ "GenSigSendType" SG_ 1153 ZR_Parken_Sondermodus 3;
BA_ "GenSigSwitchedByIgnition" SG_ 1600 MO_QBit_Ansaugluft_Temp 0;
BA_ "GenSigStartValue" SG_ 1600 MO_QBit_Ansaugluft_Temp 1;
BA_ "GenSigSendType" SG_ 1600 MO_QBit_Ansaugluft_Temp 0;
BA_ "GenSigSwitchedByIgnition" SG_ 1600 MO_QBit_Oel_Temp 0;
BA_ "GenSigStartValue" SG_ 1600 MO_QBit_Oel_Temp 1;
BA_ "GenSigSendType" SG_ 1600 MO_QBit_Oel_Temp 0;
BA_ "GenSigSwitchedByIgnition" SG_ 1600 MO_QBit_Kuehlmittel_Temp 0;
BA_ "GenSigStartValue" SG_ 1600 MO_QBit_Kuehlmittel_Temp 1;
BA_ "GenSigSendType" SG_ 1600 MO_QBit_Kuehlmittel_Temp 0;
BA_ "GenSigSwitchedByIgnition" SG_ 1600 MO_KL15_Abschaltempfehlung 0;
BA_ "GenSigSendType" SG_ 1600 MO_KL15_Abschaltempfehlung 0;
BA_ "GenSigSwitchedByIgnition" SG_ 1600 MO_HYB_Fehler_HV_Netz 0;
BA_ "GenSigSendType" SG_ 1600 MO_HYB_Fehler_HV_Netz 0;
BA_ "GenSigSwitchedByIgnition" SG_ 1600 MO_aktives_Getriebeheizen 0;
BA_ "GenSigSendType" SG_ 1600 MO_aktives_Getriebeheizen 0;
BA_ "GenSigSwitchedByIgnition" SG_ 1600 MO_Absperrventil_oeffnen 0;
BA_ "GenSigSendType" SG_ 1600 MO_Absperrventil_oeffnen 0;
BA_ "Fehlerwert" SG_ 1600 MO_Ansaugluft_Temp 255;
BA_ "GenSigSwitchedByIgnition" SG_ 1600 MO_Ansaugluft_Temp 0;
BA_ "GenSigStartValue" SG_ 1600 MO_Ansaugluft_Temp 254;
BA_ "GenSigSendType" SG_ 1600 MO_Ansaugluft_Temp 0;
BA_ "Fehlerwert" SG_ 1600 MO_Oel_Temp 255;
BA_ "GenSigSwitchedByIgnition" SG_ 1600 MO_Oel_Temp 0;
BA_ "GenSigStartValue" SG_ 1600 MO_Oel_Temp 254;
BA_ "GenSigSendType" SG_ 1600 MO_Oel_Temp 0;
BA_ "Fehlerwert" SG_ 1600 MO_Kuehlmittel_Temp 255;
BA_ "GenSigSwitchedByIgnition" SG_ 1600 MO_Kuehlmittel_Temp 0;
BA_ "GenSigStartValue" SG_ 1600 MO_Kuehlmittel_Temp 254;
BA_ "GenSigSendType" SG_ 1600 MO_Kuehlmittel_Temp 0;
BA_ "Fehlerwert" SG_ 1600 MO_Hoeheninfo 255;
BA_ "GenSigSwitchedByIgnition" SG_ 1600 MO_Hoeheninfo 0;
BA_ "GenSigSendType" SG_ 1600 MO_Hoeheninfo 0;
BA_ "GenSigSwitchedByIgnition" SG_ 1600 MO_Kennfeldk 0;
BA_ "GenSigSendType" SG_ 1600 MO_Kennfeldk 0;
BA_ "GenSigSwitchedByIgnition" SG_ 1600 MO_Versionsinfo_02 0;
BA_ "GenSigSendType" SG_ 1600 MO_Versionsinfo_02 0;
BA_ "GenSigSwitchedByIgnition" SG_ 1600 MO_QBit_Hoeheninfo 0;
BA_ "GenSigStartValue" SG_ 1600 MO_QBit_Hoeheninfo 1;
BA_ "GenSigSendType" SG_ 1600 MO_QBit_Hoeheninfo 0;
BA_ "GenSigSwitchedByIgnition" SG_ 1600 MO_Getriebe_kuehlen 0;
BA_ "GenSigSendType" SG_ 1600 MO_Getriebe_kuehlen 0;
BA_ "GenSigSwitchedByIgnition" SG_ 1600 MO_Mom_Traegheit_02 0;
BA_ "GenSigSendType" SG_ 1600 MO_Mom_Traegheit_02 0;
BA_ "Fehlerwert" SG_ 1600 MO_Heizungspumpenansteuerung 13;
BA_ "GenSigSwitchedByIgnition" SG_ 1600 MO_Heizungspumpenansteuerung 0;
BA_ "GenSigStartValue" SG_ 1600 MO_Heizungspumpenansteuerung 14;
BA_ "GenSigSendType" SG_ 1600 MO_Heizungspumpenansteuerung 0;
BA_ "GenSigSwitchedByIgnition" SG_ 1600 MO_SpannungsAnf 0;
BA_ "GenSigSendType" SG_ 1600 MO_SpannungsAnf 0;
BA_ "GenSigSwitchedByIgnition" SG_ 1600 MO_Nachlaufzeit_Heizungspumpe 0;
BA_ "GenSigSendType" SG_ 1600 MO_Nachlaufzeit_Heizungspumpe 0;
BA_ "GenSigSwitchedByIgnition" SG_ 958 Motor_14_CRC 0;
BA_ "GenSigFuncType" SG_ 958 Motor_14_CRC 2;
BA_ "GenSigSendType" SG_ 958 Motor_14_CRC 0;
BA_ "GenSigSwitchedByIgnition" SG_ 958 Motor_14_BZ 0;
BA_ "GenSigFuncType" SG_ 958 Motor_14_BZ 1;
BA_ "GenSigSendType" SG_ 958 Motor_14_BZ 0;
BA_ "GenSigSwitchedByIgnition" SG_ 958 MO_StartStopp_Status 0;
BA_ "GenSigSendType" SG_ 958 MO_StartStopp_Status 0;
BA_ "GenSigSwitchedByIgnition" SG_ 958 MO_StartStopp_Wiederstart 0;
BA_ "GenSigSendType" SG_ 958 MO_StartStopp_Wiederstart 3;
BA_ "GenSigSwitchedByIgnition" SG_ 958 MO_StartStopp_Motorstopp 0;
BA_ "GenSigSendType" SG_ 958 MO_StartStopp_Motorstopp 3;
BA_ "GenSigSwitchedByIgnition" SG_ 958 MO_Freig_Reku 0;
BA_ "GenSigSendType" SG_ 958 MO_Freig_Reku 0;
BA_ "GenSigSwitchedByIgnition" SG_ 958 MO_Kl_75 0;
BA_ "GenSigSendType" SG_ 958 MO_Kl_75 3;
BA_ "GenSigSwitchedByIgnition" SG_ 958 MO_Kl_50 0;
BA_ "GenSigSendType" SG_ 958 MO_Kl_50 3;
BA_ "Fehlerwert" SG_ 958 MO_Gangposition 15;
BA_ "GenSigSwitchedByIgnition" SG_ 958 MO_Gangposition 0;
BA_ "GenSigStartValue" SG_ 958 MO_Gangposition 14;
BA_ "GenSigSendType" SG_ 958 MO_Gangposition 3;
BA_ "GenSigSwitchedByIgnition" SG_ 958 MO_StartStopp_Fahrerwunsch 0;
BA_ "GenSigSendType" SG_ 958 MO_StartStopp_Fahrerwunsch 0;
BA_ "GenSigSwitchedByIgnition" SG_ 958 MO_HYB_Fahrbereitschaft 0;
BA_ "GenSigSendType" SG_ 958 MO_HYB_Fahrbereitschaft 0;
BA_ "GenSigSwitchedByIgnition" SG_ 958 MO_Ext_E_Fahrt_aktiv 0;
BA_ "NWM-WakeupAllowed" SG_ 958 MO_Ext_E_Fahrt_aktiv 1;
BA_ "GenSigSendType" SG_ 958 MO_Ext_E_Fahrt_aktiv 3;
BA_ "GenSigSwitchedByIgnition" SG_ 958 MO_Fahrer_bremst 0;
BA_ "GenSigSendType" SG_ 958 MO_Fahrer_bremst 3;
BA_ "GenSigSwitchedByIgnition" SG_ 958 MO_QBit_Fahrer_bremst 0;
BA_ "GenSigStartValue" SG_ 958 MO_QBit_Fahrer_bremst 1;
BA_ "GenSigSendType" SG_ 958 MO_QBit_Fahrer_bremst 3;
BA_ "GenSigSwitchedByIgnition" SG_ 958 MO_BLS 0;
BA_ "GenSigSendType" SG_ 958 MO_BLS 3;
BA_ "GenSigSwitchedByIgnition" SG_ 958 MO_Konsistenz_Bremsped 0;
BA_ "GenSigSendType" SG_ 958 MO_Konsistenz_Bremsped 3;
BA_ "GenSigSwitchedByIgnition" SG_ 958 MO_Timeout_ESP 0;
BA_ "GenSigSendType" SG_ 958 MO_Timeout_ESP 3;
BA_ "GenSigSwitchedByIgnition" SG_ 958 MO_Klima_Eingr 0;
BA_ "GenSigSendType" SG_ 958 MO_Klima_Eingr 0;
BA_ "GenSigSwitchedByIgnition" SG_ 958 MO_Aussp_Anlass 0;
BA_ "GenSigSendType" SG_ 958 MO_Aussp_Anlass 3;
BA_ "GenSigSwitchedByIgnition" SG_ 958 MO_Freig_Anlass 0;
BA_ "GenSigSendType" SG_ 958 MO_Freig_Anlass 3;
BA_ "GenSigSwitchedByIgnition" SG_ 958 MO_Kuppl_schalter 0;
BA_ "GenSigSendType" SG_ 958 MO_Kuppl_schalter 3;
BA_ "GenSigSwitchedByIgnition" SG_ 958 MO_Interlock 0;
BA_ "GenSigSendType" SG_ 958 MO_Interlock 3;
BA_ "GenSigSwitchedByIgnition" SG_ 958 MO_Motor_laeuft 0;
BA_ "GenSigSendType" SG_ 958 MO_Motor_laeuft 3;
BA_ "GenSigSwitchedByIgnition" SG_ 958 MO_Kickdown 0;
BA_ "GenSigSendType" SG_ 958 MO_Kickdown 3;
BA_ "GenSigSwitchedByIgnition" SG_ 958 MO_QBit_KL_75 0;
BA_ "GenSigStartValue" SG_ 958 MO_QBit_KL_75 1;
BA_ "GenSigSendType" SG_ 958 MO_QBit_KL_75 3;
BA_ "GenSigSwitchedByIgnition" SG_ 958 MO_EKlKomLeiRed 0;
BA_ "GenSigSendType" SG_ 958 MO_EKlKomLeiRed 0;
BA_ "GenSigSwitchedByIgnition" SG_ 958 MO_Handshake_STH 0;
BA_ "GenSigSendType" SG_ 958 MO_Handshake_STH 0;
BA_ "GenSigSwitchedByIgnition" SG_ 958 MO_BKV_Unterdruckwarnung 0;
BA_ "GenSigSendType" SG_ 958 MO_BKV_Unterdruckwarnung 0;
BA_ "GenSigSwitchedByIgnition" SG_ 958 MO_Freigabe_Segeln 0;
BA_ "GenSigSendType" SG_ 958 MO_Freigabe_Segeln 0;
BA_ "GenSigSwitchedByIgnition" SG_ 958 MO_PTC_Status 0;
BA_ "GenSigSendType" SG_ 958 MO_PTC_Status 0;
BA_ "GenSigSwitchedByIgnition" SG_ 958 MO_QBit_Gangposition 0;
BA_ "GenSigStartValue" SG_ 958 MO_QBit_Gangposition 1;
BA_ "GenSigSendType" SG_ 958 MO_QBit_Gangposition 3;
BA_ "GenSigSwitchedByIgnition" SG_ 958 MO_Signalquelle_Gangposition 0;
BA_ "GenSigSendType" SG_ 958 MO_Signalquelle_Gangposition 0;
BA_ "GenSigSwitchedByIgnition" SG_ 958 MO_Remotestart_Betrieb 0;
BA_ "GenSigSendType" SG_ 958 MO_Remotestart_Betrieb 3;
BA_ "GenSigSwitchedByIgnition" SG_ 958 MO_Remotestart_moeglich 0;
BA_ "GenSigSendType" SG_ 958 MO_Remotestart_moeglich 0;
BA_ "GenSigSwitchedByIgnition" SG_ 958 MO_FMAus_aktiv 0;
BA_ "GenSigSendType" SG_ 958 MO_FMAus_aktiv 3;
BA_ "GenSigSwitchedByIgnition" SG_ 958 MO_FMAus_Startvariante 0;
BA_ "GenSigSendType" SG_ 958 MO_FMAus_Startvariante 3;
BA_ "GenSigSwitchedByIgnition" SG_ 958 MO_BMS_NV_Anf_stuetzen 0;
BA_ "GenSigSendType" SG_ 958 MO_BMS_NV_Anf_stuetzen 3;
BA_ "GenSigSwitchedByIgnition" SG_ 958 MO_Zylinderabschaltung 0;
BA_ "GenSigSendType" SG_ 958 MO_Zylinderabschaltung 3;
BA_ "GenSigSwitchedByIgnition" SG_ 958 MO_HYB_VM_aktiv 0;
BA_ "GenSigSendType" SG_ 958 MO_HYB_VM_aktiv 3;
BA_ "GenSigSwitchedByIgnition" SG_ 958 MO_StartVorauss_erfuellt 0;
BA_ "GenSigStartValue" SG_ 958 MO_StartVorauss_erfuellt 1;
BA_ "GenSigSendType" SG_ 958 MO_StartVorauss_erfuellt 3;
BA_ "GenSigSwitchedByIgnition" SG_ 1631 TSK_Grundmasse 0;
BA_ "GenSigSendType" SG_ 1631 TSK_Grundmasse 0;
BA_ "GenSigSwitchedByIgnition" SG_ 1631 TSK_QBit_Steigung 0;
BA_ "GenSigStartValue" SG_ 1631 TSK_QBit_Steigung 1;
BA_ "GenSigSendType" SG_ 1631 TSK_QBit_Steigung 0;
BA_ "GenSigSwitchedByIgnition" SG_ 1631 TSK_QBit_Fahrzeugmasse 0;
BA_ "GenSigStartValue" SG_ 1631 TSK_QBit_Fahrzeugmasse 1;
BA_ "GenSigSendType" SG_ 1631 TSK_QBit_Fahrzeugmasse 0;
BA_ "GenSigSwitchedByIgnition" SG_ 1631 MO_SpannungsAnf_02 0;
BA_ "GenSigSendType" SG_ 1631 MO_SpannungsAnf_02 0;
BA_ "GenSigSwitchedByIgnition" SG_ 1631 MO_DPF_reg 0;
BA_ "GenSigSendType" SG_ 1631 MO_DPF_reg 0;
BA_ "Fehlerwert" SG_ 1631 MO_Heizstrom_EKAT 127;
BA_ "GenSigSwitchedByIgnition" SG_ 1631 MO_Heizstrom_EKAT 0;
BA_ "GenSigSendType" SG_ 1631 MO_Heizstrom_EKAT 0;
BA_ "Fehlerwert" SG_ 1631 MO_Heizstrom_SCR 63;
BA_ "GenSigSwitchedByIgnition" SG_ 1631 MO_Heizstrom_SCR 0;
BA_ "GenSigSendType" SG_ 1631 MO_Heizstrom_SCR 0;
BA_ "GenSigSwitchedByIgnition" SG_ 1631 MO_Testmode_AG 0;
BA_ "GenSigSendType" SG_ 1631 MO_Testmode_AG 0;
BA_ "GenSigSwitchedByIgnition" SG_ 1631 TSK_Getriebeinfo 0;
BA_ "GenSigSendType" SG_ 1631 TSK_Getriebeinfo 0;
BA_ "Fehlerwert" SG_ 1631 MO_Energieinhalt_BMS 4095;
BA_ "GenSigSwitchedByIgnition" SG_ 1631 MO_Energieinhalt_BMS 0;
BA_ "GenSigStartValue" SG_ 1631 MO_Energieinhalt_BMS 4094;
BA_ "GenSigSendType" SG_ 1631 MO_Energieinhalt_BMS 0;
BA_ "Fehlerwert" SG_ 1631 TSK_Fahrzeugmasse_02 255;
BA_ "GenSigSwitchedByIgnition" SG_ 1631 TSK_Fahrzeugmasse_02 0;
BA_ "GenSigSendType" SG_ 1631 TSK_Fahrzeugmasse_02 0;
BA_ "Fehlerwert" SG_ 1631 TSK_Steigung_02 255;
BA_ "GenSigSwitchedByIgnition" SG_ 1631 TSK_Steigung_02 0;
BA_ "GenSigSendType" SG_ 1631 TSK_Steigung_02 0;
BA_ "GenSigSwitchedByIgnition" SG_ 1648 MO_max_Ladedruck 0;
BA_ "GenSigFuncType" SG_ 1648 MO_max_Ladedruck 8;
BA_ "GenSigSendType" SG_ 1648 MO_max_Ladedruck 0;
BA_ "GenSigSwitchedByIgnition" SG_ 1648 MO_ANC_Kennfeld_Anf 0;
BA_ "GenSigSendType" SG_ 1648 MO_ANC_Kennfeld_Anf 3;
BA_ "GenSigSwitchedByIgnition" SG_ 1648 MO_Bremslicht_Reku 0;
BA_ "GenSigSendType" SG_ 1648 MO_Bremslicht_Reku 3;
BA_ "GenSigSwitchedByIgnition" SG_ 1648 MO_StartStopp_PopUp 0;
BA_ "GenSigSendType" SG_ 1648 MO_StartStopp_PopUp 3;
BA_ "GenSigSwitchedByIgnition" SG_ 1648 MO1_Sperr_Info_WFS 0;
BA_ "GenSigSendType" SG_ 1648 MO1_Sperr_Info_WFS 3;
BA_ "GenSigSwitchedByIgnition" SG_ 1648 MO1_Freigabe_Info_WFS 0;
BA_ "GenSigSendType" SG_ 1648 MO1_Freigabe_Info_WFS 3;
BA_ "GenSigSwitchedByIgnition" SG_ 1648 MO_EPCL 0;
BA_ "GenSigSendType" SG_ 1648 MO_EPCL 3;
BA_ "GenSigSwitchedByIgnition" SG_ 1648 MO_Zylabsch_Texte_02 0;
BA_ "GenSigSendType" SG_ 1648 MO_Zylabsch_Texte_02 3;
BA_ "GenSigSwitchedByIgnition" SG_ 1648 MO_Fahrzeugtyp 0;
BA_ "GenSigFuncType" SG_ 1648 MO_Fahrzeugtyp 8;
BA_ "GenSigSendType" SG_ 1648 MO_Fahrzeugtyp 0;
BA_ "GenSigSwitchedByIgnition" SG_ 1648 MO_NMAX_Schaltanzeige 0;
BA_ "GenSigSendType" SG_ 1648 MO_NMAX_Schaltanzeige 3;
BA_ "GenSigSwitchedByIgnition" SG_ 1648 MO_Abstellzeit 0;
BA_ "GenSigSendType" SG_ 1648 MO_Abstellzeit 0;
BA_ "GenSigSwitchedByIgnition" SG_ 1648 MO_Abstellzeit_Status 0;
BA_ "GenSigSendType" SG_ 1648 MO_Abstellzeit_Status 0;
BA_ "GenSigSwitchedByIgnition" SG_ 1648 MO1_Freigabe_Verfallsinfo_WFS 0;
BA_ "GenSigSendType" SG_ 1648 MO1_Freigabe_Verfallsinfo_WFS 3;
BA_ "GenSigSwitchedByIgnition" SG_ 1648 MO_Hybrid_StartStopp_LED 0;
BA_ "GenSigSendType" SG_ 1648 MO_Hybrid_StartStopp_LED 3;
BA_ "GenSigSwitchedByIgnition" SG_ 1648 MO_Fehler_Zylabsch 0;
BA_ "GenSigSendType" SG_ 1648 MO_Fehler_Zylabsch 0;
BA_ "GenSigSwitchedByIgnition" SG_ 1648 MO_Anzahl_Abgesch_Zyl 0;
BA_ "GenSigSendType" SG_ 1648 MO_Anzahl_Abgesch_Zyl 3;
BA_ "GenSigSwitchedByIgnition" SG_ 1648 MO_Zylabsch_Texte 0;
BA_ "GenSigSendType" SG_ 1648 MO_Zylabsch_Texte 0;
BA_ "GenSigSwitchedByIgnition" SG_ 1648 MO_Ethanol_BS_Texte 0;
BA_ "GenSigSendType" SG_ 1648 MO_Ethanol_BS_Texte 0;
BA_ "GenSigSwitchedByIgnition" SG_ 1648 MO_Drehzahl_Warnung 0;
BA_ "GenSigSendType" SG_ 1648 MO_Drehzahl_Warnung 0;
BA_ "GenSigSwitchedByIgnition" SG_ 1648 MO_obere_Drehzahlgrenze 0;
BA_ "GenSigSendType" SG_ 1648 MO_obere_Drehzahlgrenze 0;
BA_ "GenSigSwitchedByIgnition" SG_ 289 Motor_20_CRC 0;
BA_ "GenSigFuncType" SG_ 289 Motor_20_CRC 2;
BA_ "GenSigSendType" SG_ 289 Motor_20_CRC 0;
BA_ "GenSigSwitchedByIgnition" SG_ 289 Motor_20_BZ 0;
BA_ "GenSigFuncType" SG_ 289 Motor_20_BZ 1;
BA_ "GenSigSendType" SG_ 289 Motor_20_BZ 0;
BA_ "Fehlerwert" SG_ 289 MO_Fahrpedalrohwert_01 255;
BA_ "GenSigSwitchedByIgnition" SG_ 289 MO_Fahrpedalrohwert_01 0;
BA_ "GenSigSendType" SG_ 289 MO_Fahrpedalrohwert_01 0;
BA_ "GenSigSwitchedByIgnition" SG_ 289 MO_QBit_Fahrpedalwerte_01 0;
BA_ "GenSigStartValue" SG_ 289 MO_QBit_Fahrpedalwerte_01 1;
BA_ "GenSigSendType" SG_ 289 MO_QBit_Fahrpedalwerte_01 0;
BA_ "Fehlerwert" SG_ 289 MO_Fahrpedalgradient 255;
BA_ "GenSigSwitchedByIgnition" SG_ 289 MO_Fahrpedalgradient 0;
BA_ "GenSigSendType" SG_ 289 MO_Fahrpedalgradient 0;
BA_ "GenSigSwitchedByIgnition" SG_ 289 MO_Sig_Fahrpedalgradient 0;
BA_ "GenSigSendType" SG_ 289 MO_Sig_Fahrpedalgradient 0;
BA_ "Fehlerwert" SG_ 289 MO_rel_Saugrohrdruck 63;
BA_ "GenSigSwitchedByIgnition" SG_ 289 MO_rel_Saugrohrdruck 0;
BA_ "GenSigSendType" SG_ 289 MO_rel_Saugrohrdruck 0;
BA_ "GenSigSwitchedByIgnition" SG_ 289 MO_rel_Saugrohrdruck_gem_err 0;
BA_ "GenSigSendType" SG_ 289 MO_rel_Saugrohrdruck_gem_err 0;
BA_ "GenSigSwitchedByIgnition" SG_ 289 MO_Moment_im_Leerlauf 0;
BA_ "GenSigSendType" SG_ 289 MO_Moment_im_Leerlauf 0;
BA_ "GenSigSwitchedByIgnition" SG_ 289 MO_Schubabschaltung 0;
BA_ "GenSigSendType" SG_ 289 MO_Schubabschaltung 0;
BA_ "GenSigSwitchedByIgnition" SG_ 289 MO_StartStopp_StoppVorbereitung 0;
BA_ "GenSigSendType" SG_ 289 MO_StartStopp_StoppVorbereitung 0;
BA_ "GenSigSwitchedByIgnition" SG_ 289 MO_Solldrehz_Leerlauf 0;
BA_ "GenSigSendType" SG_ 289 MO_Solldrehz_Leerlauf 0;
BA_ "GenSigSwitchedByIgnition" SG_ 289 MO_Entkopplung_Sollschlupf 0;
BA_ "GenSigStartValue" SG_ 289 MO_Entkopplung_Sollschlupf 126;
BA_ "GenSigSendType" SG_ 289 MO_Entkopplung_Sollschlupf 0;
BA_ "GenSigSwitchedByIgnition" SG_ 289 MO_temporaere_Fahrerabwesenheit 0;
BA_ "GenSigSendType" SG_ 289 MO_temporaere_Fahrerabwesenheit 0;
BA_ "GenSigSwitchedByIgnition" SG_ 289 TSK_a_Soll_gradientenbegrenzt 0;
BA_ "GenSigStartValue" SG_ 289 TSK_a_Soll_gradientenbegrenzt 127;
BA_ "GenSigSendType" SG_ 289 TSK_a_Soll_gradientenbegrenzt 0;
BA_ "GenSigSwitchedByIgnition" SG_ 283 MO_Fahrbereitschaft 0;
BA_ "GenSigSendType" SG_ 283 MO_Fahrbereitschaft 3;
BA_ "GenSigSwitchedByIgnition" SG_ 283 MO_Freilauf_Info 0;
BA_ "GenSigSendType" SG_ 283 MO_Freilauf_Info 3;
BA_ "GenSigSwitchedByIgnition" SG_ 283 MO_EnergyAssist_Aktivierbar 0;
BA_ "GenSigSendType" SG_ 283 MO_EnergyAssist_Aktivierbar 3;
BA_ "Fehlerwert" SG_ 283 MO_Krit_Heckobjekt 7;
BA_ "GenSigSwitchedByIgnition" SG_ 283 MO_Krit_Heckobjekt 0;
BA_ "GenSigSendType" SG_ 283 MO_Krit_Heckobjekt 0;
BA_ "Fehlerwert" SG_ 283 MO_NGS_Gangpos 7;
BA_ "GenSigSwitchedByIgnition" SG_ 283 MO_NGS_Gangpos 0;
BA_ "GenSigSendType" SG_ 283 MO_NGS_Gangpos 3;
BA_ "GenSigSwitchedByIgnition" SG_ 1601 Motor_Code_01_CRC 0;
BA_ "GenSigFuncType" SG_ 1601 Motor_Code_01_CRC 2;
BA_ "GenSigSendType" SG_ 1601 Motor_Code_01_CRC 0;
BA_ "GenSigSwitchedByIgnition" SG_ 1601 Motor_Code_01_BZ 0;
BA_ "GenSigFuncType" SG_ 1601 Motor_Code_01_BZ 1;
BA_ "GenSigSendType" SG_ 1601 Motor_Code_01_BZ 0;
BA_ "GenSigSwitchedByIgnition" SG_ 1601 MO_Faktor_Momente_02 0;
BA_ "GenSigFuncType" SG_ 1601 MO_Faktor_Momente_02 8;
BA_ "GenSigSendType" SG_ 1601 MO_Faktor_Momente_02 0;
BA_ "GenSigSwitchedByIgnition" SG_ 1601 MO_Hybridfahrzeug 0;
BA_ "GenSigFuncType" SG_ 1601 MO_Hybridfahrzeug 8;
BA_ "GenSigSendType" SG_ 1601 MO_Hybridfahrzeug 0;
BA_ "GenSigSwitchedByIgnition" SG_ 1601 MO_Code 0;
BA_ "GenSigFuncType" SG_ 1601 MO_Code 8;
BA_ "GenSigSendType" SG_ 1601 MO_Code 0;
BA_ "GenSigSwitchedByIgnition" SG_ 1601 MO_Getriebe_Code 0;
BA_ "GenSigFuncType" SG_ 1601 MO_Getriebe_Code 8;
BA_ "GenSigSendType" SG_ 1601 MO_Getriebe_Code 0;
BA_ "GenSigSwitchedByIgnition" SG_ 1601 MO_StartStopp_Codiert 0;
BA_ "GenSigFuncType" SG_ 1601 MO_StartStopp_Codiert 8;
BA_ "GenSigSendType" SG_ 1601 MO_StartStopp_Codiert 0;
BA_ "GenSigSwitchedByIgnition" SG_ 1601 MO_Anzeige_StSt_gueltig 0;
BA_ "GenSigSendType" SG_ 1601 MO_Anzeige_StSt_gueltig 0;
BA_ "GenSigSwitchedByIgnition" SG_ 1601 MO_Anzahl_Zyl 0;
BA_ "GenSigFuncType" SG_ 1601 MO_Anzahl_Zyl 8;
BA_ "GenSigSendType" SG_ 1601 MO_Anzahl_Zyl 0;
BA_ "GenSigSwitchedByIgnition" SG_ 1601 MO_Kraftstoffart 0;
BA_ "GenSigFuncType" SG_ 1601 MO_Kraftstoffart 8;
BA_ "GenSigSendType" SG_ 1601 MO_Kraftstoffart 0;
BA_ "GenSigSwitchedByIgnition" SG_ 1601 MO_Hubraum 0;
BA_ "GenSigFuncType" SG_ 1601 MO_Hubraum 8;
BA_ "GenSigSendType" SG_ 1601 MO_Hubraum 0;
BA_ "GenSigSwitchedByIgnition" SG_ 1601 MO_Ansaugsystem 0;
BA_ "GenSigFuncType" SG_ 1601 MO_Ansaugsystem 8;
BA_ "GenSigSendType" SG_ 1601 MO_Ansaugsystem 0;
BA_ "GenSigSwitchedByIgnition" SG_ 1601 MO_Leistung 0;
BA_ "GenSigFuncType" SG_ 1601 MO_Leistung 8;
BA_ "GenSigSendType" SG_ 1601 MO_Leistung 0;
BA_ "GenSigSwitchedByIgnition" SG_ 1601 MO_OBD_Typ 0;
BA_ "GenSigFuncType" SG_ 1601 MO_OBD_Typ 8;
BA_ "GenSigSendType" SG_ 1601 MO_OBD_Typ 0;
BA_ "GenSigSwitchedByIgnition" SG_ 1601 MO_DPF_verbaut 0;
BA_ "GenSigFuncType" SG_ 1601 MO_DPF_verbaut 8;
BA_ "GenSigSendType" SG_ 1601 MO_DPF_verbaut 0;
BA_ "GenSigSwitchedByIgnition" SG_ 1601 TSK_Codierung 0;
BA_ "GenSigStartValue" SG_ 1601 TSK_Codierung 7;
BA_ "GenSigSendType" SG_ 1601 TSK_Codierung 0;
BA_ "GenSigSwitchedByIgnition" SG_ 2600468496 NM_Gateway_SNI 0;
BA_ "GenSigStartValue" SG_ 2600468496 NM_Gateway_SNI 16;
BA_ "GenSigSwitchedByIgnition" SG_ 2600468496 NM_Gateway_NM_State 0;
BA_ "GenSigSwitchedByIgnition" SG_ 2600468496 NM_Gateway_Car_Wakeup 0;
BA_ "GenSigSwitchedByIgnition" SG_ 2600468496 NM_Gateway_Wakeup 0;
BA_ "NWM-WakeupAllowed" SG_ 2600468496 NM_Gateway_Wakeup 1;
BA_ "GenSigSwitchedByIgnition" SG_ 2600468496 NM_Gateway_NM_aktiv_KL15 0;
BA_ "GenSigSwitchedByIgnition" SG_ 2600468496 NM_Gateway_NM_aktiv_Diagnose 0;
BA_ "GenSigSwitchedByIgnition" SG_ 2600468496 NM_Gateway_NM_aktiv_Tmin 0;
BA_ "GenSigSwitchedByIgnition" SG_ 2600468496 NM_Gateway_ACAN_Aktivitaet 0;
BA_ "GenSigSwitchedByIgnition" SG_ 2600468496 NM_Gateway_FCAN_Aktivitaet 0;
BA_ "GenSigSwitchedByIgnition" SG_ 2600468496 NM_Gateway_KCAN_Aktivitaet 0;
BA_ "GenSigSwitchedByIgnition" SG_ 2600468496 NM_Gateway_ICAN_Aktivitaet 0;
BA_ "GenSigSwitchedByIgnition" SG_ 2600468496 NM_Gateway_DiagCAN_Aktivitaet 0;
BA_ "GenSigSwitchedByIgnition" SG_ 2600468496 NM_Gateway_ECAN_Aktivitaet 0;
BA_ "GenSigSwitchedByIgnition" SG_ 2600468496 NM_Gateway_EnergieLIN_Aktivitaet 0;
BA_ "GenSigSwitchedByIgnition" SG_ 2600468496 NM_Gateway_Bedien_LIN_Aktivitaet 0;
BA_ "GenSigSwitchedByIgnition" SG_ 2600468496 NM_Gateway_EM_Aktivitaet 0;
BA_ "GenSigSwitchedByIgnition" SG_ 2600468496 NM_Gateway_KS_Aktivitaet 0;
BA_ "GenSigSwitchedByIgnition" SG_ 2600468496 NM_Gateway_HVEM_aktiv 0;
BA_ "GenSigSwitchedByIgnition" SG_ 2600468496 NM_Gateway_NL_EM 0;
BA_ "GenSigSwitchedByIgnition" SG_ 2600468496 NM_Gateway_NL_Shutdown 0;
BA_ "GenSigSwitchedByIgnition" SG_ 2600468496 NM_Gateway_NL_Spg_Messung 0;
BA_ "GenSigSwitchedByIgnition" SG_ 2600468496 NM_Gateway_NL_Wakeup_Monitor 0;
BA_ "GenSigSwitchedByIgnition" SG_ 2600468496 NM_Gateway_UDS_CC 0;
BA_ "GenSigStartValue" SG_ 2600468564 NM_LWRAFS_SNI 84;
BA_ "NWM-WakeupAllowed" SG_ 2600468564 NM_LWRAFS_Wakeup 1;
BA_ "GenSigSwitchedByIgnition" SG_ 2549875287 OBDC_ACC_Req_Data 0;
BA_ "GenSigFuncType" SG_ 2549875287 OBDC_ACC_Req_Data 9;
BA_ "GenSigSendType" SG_ 2549875287 OBDC_ACC_Req_Data 3;
BA_ "GenSigFuncType" SG_ 2550006359 OBDC_ACC_Resp_Data 9;
BA_ "GenSigSendType" SG_ 2550006359 OBDC_ACC_Resp_Data 3;
BA_ "GenSigSwitchedByIgnition" SG_ 2549875248 OBDC_FLA_Req_Data 0;
BA_ "GenSigSendType" SG_ 2549875248 OBDC_FLA_Req_Data 3;
BA_ "GenSigSendType" SG_ 2550006320 OBDC_FLA_Resp_Data 3;
BA_ "GenSigSwitchedByIgnition" SG_ 2549875279 OBDC_Kamera_ReqData 0;
BA_ "GenSigSendType" SG_ 2549875279 OBDC_Kamera_ReqData 3;
BA_ "GenSigSendType" SG_ 2550006351 OBDC_Kamera_Resp_Data 3;
BA_ "GenSigSwitchedByIgnition" SG_ 2549875330 OBDC_LCM_L_Req_Data 0;
BA_ "GenSigSendType" SG_ 2549875330 OBDC_LCM_L_Req_Data 3;
BA_ "GenSigSendType" SG_ 2550006402 OBDC_LCM_L_Resp_Data 3;
BA_ "GenSigSwitchedByIgnition" SG_ 2549875331 OBDC_LCM_R_Req_Data 0;
BA_ "GenSigSendType" SG_ 2549875331 OBDC_LCM_R_Req_Data 3;
BA_ "GenSigSendType" SG_ 2550006403 OBDC_LCM_R_Resp_Data 3;
BA_ "GenSigSwitchedByIgnition" SG_ 2549875350 OBDC_LED_LM_L_Req_Data 0;
BA_ "GenSigSendType" SG_ 2549875350 OBDC_LED_LM_L_Req_Data 3;
BA_ "GenSigSendType" SG_ 2550006422 OBDC_LED_LM_L_Resp_Data 3;
BA_ "GenSigSwitchedByIgnition" SG_ 2549875351 OBDC_LED_LM_R_Req_Data 0;
BA_ "GenSigSendType" SG_ 2549875351 OBDC_LED_LM_R_Req_Data 3;
BA_ "GenSigSendType" SG_ 2550006423 OBDC_LED_LM_R_Resp_Data 3;
BA_ "GenSigSwitchedByIgnition" SG_ 2549875284 OBDC_LWRAFS_Req_Struct 0;
BA_ "GenSigFuncType" SG_ 2549875284 OBDC_LWRAFS_Req_Struct 9;
BA_ "GenSigSendType" SG_ 2549875284 OBDC_LWRAFS_Req_Struct 3;
BA_ "GenSigFuncType" SG_ 2550006356 OBDC_LWRAFS_Resp_Data 9;
BA_ "GenSigSendType" SG_ 2550006356 OBDC_LWRAFS_Resp_Data 3;
BA_ "GenSigSwitchedByIgnition" SG_ 2549875278 OBDC_SWA_Req_Data 0;
BA_ "GenSigSendType" SG_ 2549875278 OBDC_SWA_Req_Data 3;
BA_ "GenSigSendType" SG_ 2550006350 OBDC_SWA_Resp_Data 3;
BA_ "Fehlerwert" SG_ 1175 PH_Visualisierung 7;
BA_ "GenSigStartValue" SG_ 1175 PH_Visualisierung 6;
BA_ "GenSigSendType" SG_ 1175 PH_Visualisierung 3;
BA_ "GenSigSendType" SG_ 1175 PDC_Tonausgabe_Front 3;
BA_ "GenSigSendType" SG_ 1175 PDC_Tonausgabe_Heck 3;
BA_ "GenSigSendType" SG_ 1175 PH_nachtr_Stopp_Anf 3;
BA_ "GenSigSendType" SG_ 1175 PH_Abschaltursache 3;
BA_ "GenSigSendType" SG_ 1175 PH_Opt_Anzeige_V_ein 3;
BA_ "GenSigSendType" SG_ 1175 PH_Opt_Anzeige_H_ein 3;
BA_ "GenSigSendType" SG_ 1175 PH_Opt_Anz_V_Hindernis 3;
BA_ "GenSigSendType" SG_ 1175 PH_Opt_Anz_H_Hindernis 3;
BA_ "GenSigSendType" SG_ 1175 PH_Tongeber_V_aktiv 3;
BA_ "GenSigSendType" SG_ 1175 PH_Tongeber_H_aktiv 3;
BA_ "GenSigSendType" SG_ 1175 PH_Tongeber_mute 3;
BA_ "GenSigSendType" SG_ 1175 PH_Anf_Audioabsenkung 3;
BA_ "GenSigSendType" SG_ 1175 PH_Tongeber_H_verfuegbar 3;
BA_ "GenSigSendType" SG_ 1175 PLA_Anf_Aufschaltung_RVC 3;
BA_ "Fehlerwert" SG_ 1175 PH_Taster 3;
BA_ "GenSigSendType" SG_ 1175 PH_Taster 3;
BA_ "GenSigSendType" SG_ 1175 PH_Anf_Verdeck 3;
BA_ "GenSigSendType" SG_ 1175 PH_Frequenz_hinten 3;
BA_ "GenSigSendType" SG_ 1175 PH_Lautstaerke_hinten 3;
BA_ "GenSigSendType" SG_ 1175 PH_Frequenz_vorn 3;
BA_ "GenSigSendType" SG_ 1175 PH_Lautstaerke_vorn 3;
BA_ "GenSigSendType" SG_ 1175 PH_StartStopp_Info 3;
BA_ "GenSigSendType" SG_ 1175 PH_Stoermeldung 3;
BA_ "GenSigSendType" SG_ 1175 PH_defekt 3;
BA_ "GenSigSendType" SG_ 1175 PH_gestoert 3;
BA_ "GenSigSendType" SG_ 1175 PH_Systemzustand 3;
BA_ "GenSigSendType" SG_ 1175 PH_Display_Kundenwunsch 3;
BA_ "GenSigSendType" SG_ 1351 US_Objekt_links 3;
BA_ "GenSigSendType" SG_ 1351 US_Objekt_rechts 3;
BA_ "Fehlerwert" SG_ 1351 US_Objektueberwachung_Status 3;
BA_ "GenSigSendType" SG_ 1351 US_Objektueberwachung_Status 3;
BA_ "GenSigSwitchedByIgnition" SG_ 2527679498 Perso_Kontonummer 0;
BA_ "GenSigSendType" SG_ 2527679498 Perso_Kontonummer 4;
BA_ "GenSigSwitchedByIgnition" SG_ 2527679498 Perso_Steuerung 0;
BA_ "GenSigSendType" SG_ 2527679498 Perso_Steuerung 4;
BA_ "GenSigSwitchedByIgnition" SG_ 2527679498 Perso_Steuerungsparameter 0;
BA_ "GenSigSendType" SG_ 2527679498 Perso_Steuerungsparameter 4;
BA_ "GenSigSwitchedByIgnition" SG_ 2527679498 Perso_Status 0;
BA_ "GenSigSendType" SG_ 2527679498 Perso_Status 1;
BA_ "GenSigSwitchedByIgnition" SG_ 2527679498 Perso_Bedienstelle 0;
BA_ "GenSigSendType" SG_ 2527679498 Perso_Bedienstelle 4;
BA_ "GenSigSwitchedByIgnition" SG_ 2527679498 Perso_Freigabe_Verstellung 0;
BA_ "GenSigSendType" SG_ 2527679498 Perso_Freigabe_Verstellung 4;
BA_ "GenSigSwitchedByIgnition" SG_ 2527679498 Perso_Aktiv 0;
BA_ "GenSigSendType" SG_ 2527679498 Perso_Aktiv 4;
BA_ "GenSigSendType" SG_ 929 PSD_Pos_Segment_ID 0;
BA_ "GenSigSendType" SG_ 929 PSD_Pos_Segmentlaenge 0;
BA_ "GenSigSendType" SG_ 929 PSD_Pos_Inhibitzeit 0;
BA_ "GenSigSendType" SG_ 929 PSD_Pos_Standort 0;
BA_ "GenSigSendType" SG_ 929 PSD_Pos_Laengsfehler 0;
BA_ "GenSigSendType" SG_ 929 PSD_Segment_ID 0;
BA_ "GenSigSendType" SG_ 929 PSD_Vorgaenger_Segment_ID 0;
BA_ "GenSigSendType" SG_ 929 PSD_Strassenklasse 0;
BA_ "GenSigSendType" SG_ 929 PSD_Segmentlaenge 0;
BA_ "GenSigSendType" SG_ 929 PSD_Rampe 0;
BA_ "GenSigSendType" SG_ 929 PSD_Endkruemmung 0;
BA_ "GenSigSendType" SG_ 929 PSD_Endkruemmung_Vorz 0;
BA_ "GenSigSendType" SG_ 929 PSD_Endsteigung 0;
BA_ "GenSigSendType" SG_ 929 PSD_Endsteigung_Vorz 0;
BA_ "GenSigSendType" SG_ 929 PSD_ADAS_Qualitaet 0;
BA_ "GenSigStartValue" SG_ 929 PSD_Fahrspuren 1;
BA_ "GenSigSendType" SG_ 929 PSD_Fahrspuren 0;
BA_ "GenSigSendType" SG_ 929 PSD_wahrscheinlichster_Pfad 0;
BA_REL_ "GenSigTimeoutTime" BU_SG_REL_ Frontradar SG_ 134 LWI_01_CRC 500;
BA_REL_ "GenSigTimeoutTime" BU_SG_REL_ Frontsensorik SG_ 134 LWI_01_CRC 500;
BA_REL_ "GenSigTimeoutTime" BU_SG_REL_ Frontradar SG_ 134 LWI_01_BZ 500;
BA_REL_ "GenSigTimeoutTime" BU_SG_REL_ Frontsensorik SG_ 134 LWI_01_BZ 500;
BA_REL_ "GenSigTimeoutTime" BU_SG_REL_ Frontradar SG_ 134 LWI_Sensorstatus 500;
BA_REL_ "GenSigTimeoutTime" BU_SG_REL_ Frontsensorik SG_ 134 LWI_Sensorstatus 500;
BA_REL_ "GenSigTimeoutTime" BU_SG_REL_ Frontradar SG_ 134 LWI_QBit_Lenkradwinkel 500;
BA_REL_ "GenSigTimeoutTime" BU_SG_REL_ Frontsensorik SG_ 134 LWI_QBit_Lenkradwinkel 500;
BA_REL_ "GenSigTimeoutTime" BU_SG_REL_ Frontradar SG_ 134 LWI_Lenkradwinkel 500;
BA_REL_ "GenSigTimeoutTime" BU_SG_REL_ Frontsensorik SG_ 134 LWI_Lenkradwinkel 500;
BA_REL_ "GenSigTimeoutTime" BU_SG_REL_ Frontradar SG_ 134 LWI_VZ_Lenkradwinkel 500;
BA_REL_ "GenSigTimeoutTime" BU_SG_REL_ Frontsensorik SG_ 134 LWI_VZ_Lenkradwinkel 500;
BA_REL_ "GenSigTimeoutTime" BU_SG_REL_ Frontradar SG_ 134 LWI_VZ_Lenkradw_Geschw 500;
BA_REL_ "GenSigTimeoutTime" BU_SG_REL_ Frontradar SG_ 134 LWI_Lenkradw_Geschw 500;
BA_REL_ "GenSigTimeoutTime" BU_SG_REL_ Frontsensorik SG_ 295 LWR_Verstellwinkel_li 500;
BA_REL_ "GenSigTimeoutTime" BU_SG_REL_ Frontsensorik SG_ 295 LWR_Verstellwinkel_re 500;
BA_REL_ "GenSigTimeoutTime" BU_SG_REL_ Frontsensorik SG_ 295 AFS_Schwenkwinkel_li 500;
BA_REL_ "GenSigTimeoutTime" BU_SG_REL_ Frontsensorik SG_ 295 AFS_Schwenkwinkel_re 500;
BA_REL_ "GenSigTimeoutTime" BU_SG_REL_ Frontsensorik SG_ 295 AFS_Lichtverteilung_li 500;
BA_REL_ "GenSigTimeoutTime" BU_SG_REL_ Frontsensorik SG_ 295 AFS_Lichtverteilung_re 500;
BA_REL_ "GenSigTimeoutTime" BU_SG_REL_ Frontsensorik SG_ 295 AFS_Status_Verkehrsart 500;
BA_REL_ "GenSigTimeoutTime" BU_SG_REL_ Frontsensorik SG_ 295 GLW_Nebelregelung 500;
BA_REL_ "GenSigTimeoutTime" BU_SG_REL_ Frontsensorik SG_ 846 MXB_Status_Seg01 500;
BA_REL_ "GenSigTimeoutTime" BU_SG_REL_ Frontsensorik SG_ 846 MXB_Status_Seg02 500;
BA_REL_ "GenSigTimeoutTime" BU_SG_REL_ Frontsensorik SG_ 846 MXB_Status_Seg03 500;
BA_REL_ "GenSigTimeoutTime" BU_SG_REL_ Frontsensorik SG_ 846 MXB_Status_Seg04 500;
BA_REL_ "GenSigTimeoutTime" BU_SG_REL_ Frontsensorik SG_ 846 MXB_Status_Seg05 500;
BA_REL_ "GenSigTimeoutTime" BU_SG_REL_ Frontsensorik SG_ 846 MXB_Status_Seg06 500;
BA_REL_ "GenSigTimeoutTime" BU_SG_REL_ Frontsensorik SG_ 846 MXB_Status_Seg07 500;
BA_REL_ "GenSigTimeoutTime" BU_SG_REL_ Frontsensorik SG_ 846 MXB_Status_Seg08 500;
BA_REL_ "GenSigTimeoutTime" BU_SG_REL_ Frontsensorik SG_ 846 MXB_Status_Seg09 500;
BA_REL_ "GenSigTimeoutTime" BU_SG_REL_ Frontsensorik SG_ 846 MXB_Status_Seg10 500;
BA_REL_ "GenSigTimeoutTime" BU_SG_REL_ Frontsensorik SG_ 846 MXB_Status_Seg11 500;
BA_REL_ "GenSigTimeoutTime" BU_SG_REL_ Frontsensorik SG_ 846 MXB_Status_Seg12 500;
BA_REL_ "GenSigTimeoutTime" BU_SG_REL_ Frontsensorik SG_ 846 MXB_Status_Seg13 500;
BA_REL_ "GenSigTimeoutTime" BU_SG_REL_ Frontsensorik SG_ 846 MXB_Status_Seg14 500;
BA_REL_ "GenSigTimeoutTime" BU_SG_REL_ Frontsensorik SG_ 846 MXB_Status_Seg15 500;
BA_REL_ "GenSigTimeoutTime" BU_SG_REL_ Frontsensorik SG_ 846 MXB_Status_Seg16 500;
BA_REL_ "GenSigTimeoutTime" BU_SG_REL_ Frontsensorik SG_ 846 MXB_Status_Seg17 500;
BA_REL_ "GenSigTimeoutTime" BU_SG_REL_ Frontsensorik SG_ 846 MXB_Status_Seg18 500;
BA_REL_ "GenSigTimeoutTime" BU_SG_REL_ Frontsensorik SG_ 846 MXB_Status_Seg19 500;
BA_REL_ "GenSigTimeoutTime" BU_SG_REL_ Frontsensorik SG_ 846 MXB_Status_Seg20 500;
BA_REL_ "GenSigTimeoutTime" BU_SG_REL_ Frontsensorik SG_ 846 MXB_Status_Seg21 500;
BA_REL_ "GenSigTimeoutTime" BU_SG_REL_ Frontsensorik SG_ 846 MXB_Status_Seg22 500;
BA_REL_ "GenSigTimeoutTime" BU_SG_REL_ Frontsensorik SG_ 846 MXB_Status_Seg23 500;
BA_REL_ "GenSigTimeoutTime" BU_SG_REL_ Frontsensorik SG_ 846 MXB_Status_Seg24 500;
BA_REL_ "GenSigTimeoutTime" BU_SG_REL_ Frontsensorik SG_ 846 MXB_Status_Seg25 500;
BA_REL_ "GenSigTimeoutTime" BU_SG_REL_ Frontsensorik SG_ 846 MXB_Status_Seg26 500;
BA_REL_ "GenSigTimeoutTime" BU_SG_REL_ Frontsensorik SG_ 846 MXB_Status_Seg27 500;
BA_REL_ "GenSigTimeoutTime" BU_SG_REL_ Frontsensorik SG_ 846 MXB_Status_Seg28 500;
BA_REL_ "GenSigTimeoutTime" BU_SG_REL_ Frontsensorik SG_ 846 MXB_Status_Seg29 500;
BA_REL_ "GenSigTimeoutTime" BU_SG_REL_ Frontsensorik SG_ 846 MXB_Status_Seg30 500;
BA_REL_ "GenSigTimeoutTime" BU_SG_REL_ Frontsensorik SG_ 846 MXB_Status_Seg31 500;
BA_REL_ "GenSigTimeoutTime" BU_SG_REL_ Frontsensorik SG_ 846 MXB_Status_Seg32 500;
BA_REL_ "GenSigTimeoutTime" BU_SG_REL_ Frontsensorik SG_ 847 MXB_Status_Seg33 500;
BA_REL_ "GenSigTimeoutTime" BU_SG_REL_ Frontsensorik SG_ 847 MXB_Status_Seg34 500;
BA_REL_ "GenSigTimeoutTime" BU_SG_REL_ Frontsensorik SG_ 847 MXB_Status_Seg35 500;
BA_REL_ "GenSigTimeoutTime" BU_SG_REL_ Frontsensorik SG_ 847 MXB_Status_Seg36 500;
BA_REL_ "GenSigTimeoutTime" BU_SG_REL_ Frontsensorik SG_ 847 MXB_Status_Seg37 500;
BA_REL_ "GenSigTimeoutTime" BU_SG_REL_ Frontsensorik SG_ 847 MXB_Status_Seg38 500;
BA_REL_ "GenSigTimeoutTime" BU_SG_REL_ Frontsensorik SG_ 847 MXB_Status_Seg39 500;
BA_REL_ "GenSigTimeoutTime" BU_SG_REL_ Frontsensorik SG_ 847 MXB_Status_Seg40 500;
BA_REL_ "GenSigTimeoutTime" BU_SG_REL_ Frontsensorik SG_ 847 MXB_Status_Seg41 500;
BA_REL_ "GenSigTimeoutTime" BU_SG_REL_ Frontsensorik SG_ 847 MXB_Status_Seg42 500;
BA_REL_ "GenSigTimeoutTime" BU_SG_REL_ Frontsensorik SG_ 847 MXB_Status_Seg43 500;
BA_REL_ "GenSigTimeoutTime" BU_SG_REL_ Frontsensorik SG_ 847 MXB_Status_Seg44 500;
BA_REL_ "GenSigTimeoutTime" BU_SG_REL_ Frontsensorik SG_ 847 MXB_Status_Seg45 500;
BA_REL_ "GenSigTimeoutTime" BU_SG_REL_ Frontsensorik SG_ 847 MXB_Status_Seg46 500;
BA_REL_ "GenSigTimeoutTime" BU_SG_REL_ Frontsensorik SG_ 847 MXB_Status_Seg47 500;
BA_REL_ "GenSigTimeoutTime" BU_SG_REL_ Frontsensorik SG_ 847 MXB_Status_Seg48 500;
BA_REL_ "GenSigTimeoutTime" BU_SG_REL_ Frontsensorik SG_ 847 MXB_Status_Seg49 500;
BA_REL_ "GenSigTimeoutTime" BU_SG_REL_ Frontsensorik SG_ 847 MXB_Status_Seg50 500;
BA_REL_ "GenSigTimeoutTime" BU_SG_REL_ Frontsensorik SG_ 847 MXB_Status_Seg51 500;
BA_REL_ "GenSigTimeoutTime" BU_SG_REL_ Frontsensorik SG_ 847 MXB_Status_Seg52 500;
BA_REL_ "GenSigTimeoutTime" BU_SG_REL_ Frontsensorik SG_ 847 MXB_Status_Seg53 500;
BA_REL_ "GenSigTimeoutTime" BU_SG_REL_ Frontsensorik SG_ 847 MXB_Status_Seg54 500;
BA_REL_ "GenSigTimeoutTime" BU_SG_REL_ Frontsensorik SG_ 847 MXB_Status_Seg55 500;
BA_REL_ "GenSigTimeoutTime" BU_SG_REL_ Frontsensorik SG_ 847 MXB_Status_Seg56 500;
BA_REL_ "GenSigTimeoutTime" BU_SG_REL_ Frontsensorik SG_ 847 MXB_Status_Seg57 500;
BA_REL_ "GenSigTimeoutTime" BU_SG_REL_ Frontsensorik SG_ 847 MXB_Status_Seg58 500;
BA_REL_ "GenSigTimeoutTime" BU_SG_REL_ Frontsensorik SG_ 847 MXB_Status_Seg59 500;
BA_REL_ "GenSigTimeoutTime" BU_SG_REL_ Frontsensorik SG_ 847 MXB_Status_Seg60 500;
BA_REL_ "GenSigTimeoutTime" BU_SG_REL_ Frontsensorik SG_ 1721 MXB_horiz_Offset_li_SW 5000;
BA_REL_ "GenSigTimeoutTime" BU_SG_REL_ Frontsensorik SG_ 1721 MXB_Status 5000;
BA_REL_ "GenSigTimeoutTime" BU_SG_REL_ Frontsensorik SG_ 1721 MXB_vert_Offset_li_SW 5000;
BA_REL_ "GenSigTimeoutTime" BU_SG_REL_ Frontsensorik SG_ 1721 MXB_horiz_Offset_re_SW 5000;
BA_REL_ "GenSigTimeoutTime" BU_SG_REL_ Frontsensorik SG_ 1721 MXB_vert_Offset_re_SW 5000;
BA_REL_ "GenSigTimeoutTime" BU_SG_REL_ Frontsensorik SG_ 1153 MMI_Counter_Bedienevent 5000;
BA_REL_ "GenSigTimeoutTime" BU_SG_REL_ Frontradar SG_ 958 MO_StartStopp_Status 1000;
BA_REL_ "GenSigTimeoutTime" BU_SG_REL_ Frontradar SG_ 958 MO_StartStopp_Wiederstart 1000;
BA_REL_ "GenSigTimeoutTime" BU_SG_REL_ Frontradar SG_ 958 MO_StartStopp_Motorstopp 1000;
BA_REL_ "GenSigTimeoutTime" BU_SG_REL_ Frontradar SG_ 958 MO_Kl_75 1000;
BA_REL_ "GenSigTimeoutTime" BU_SG_REL_ Frontradar SG_ 958 MO_Kl_50 1000;
BA_REL_ "GenSigTimeoutTime" BU_SG_REL_ Frontradar SG_ 958 MO_Gangposition 1000;
BA_REL_ "GenSigTimeoutTime" BU_SG_REL_ Frontradar SG_ 958 MO_Ext_E_Fahrt_aktiv 1000;
BA_REL_ "GenSigTimeoutTime" BU_SG_REL_ Frontradar SG_ 958 MO_Fahrer_bremst 1000;
BA_REL_ "GenSigTimeoutTime" BU_SG_REL_ Frontradar SG_ 958 MO_QBit_Fahrer_bremst 1000;
BA_REL_ "GenSigTimeoutTime" BU_SG_REL_ Frontradar SG_ 958 MO_BLS 1000;
BA_REL_ "GenSigTimeoutTime" BU_SG_REL_ Frontradar SG_ 958 MO_Kuppl_schalter 1000;
BA_REL_ "GenSigTimeoutTime" BU_SG_REL_ Frontsensorik SG_ 958 MO_Motor_laeuft 1000;
BA_REL_ "GenSigTimeoutTime" BU_SG_REL_ Frontradar SG_ 958 MO_QBit_Gangposition 1000;
BA_REL_ "GenSigTimeoutTime" BU_SG_REL_ Frontradar SG_ 1631 TSK_QBit_Steigung 5000;
BA_REL_ "GenSigTimeoutTime" BU_SG_REL_ Frontradar SG_ 1631 TSK_Fahrzeugmasse_02 5000;
BA_REL_ "GenSigTimeoutTime" BU_SG_REL_ Frontradar SG_ 1631 TSK_Steigung_02 5000;
BA_REL_ "GenSigTimeoutTime" BU_SG_REL_ Frontradar SG_ 1648 MO_Bremslicht_Reku 5000;
BA_REL_ "GenSigTimeoutTime" BU_SG_REL_ Frontradar SG_ 1648 MO_Fahrzeugtyp 5000;
BA_REL_ "GenSigTimeoutTime" BU_SG_REL_ Frontradar SG_ 1648 MO_obere_Drehzahlgrenze 5000;
BA_REL_ "GenSigTimeoutTime" BU_SG_REL_ Frontradar SG_ 289 Motor_20_CRC 500;
BA_REL_ "GenSigTimeoutTime" BU_SG_REL_ Frontradar SG_ 289 Motor_20_BZ 500;
BA_REL_ "GenSigTimeoutTime" BU_SG_REL_ Frontradar SG_ 289 MO_Fahrpedalrohwert_01 500;
BA_REL_ "GenSigTimeoutTime" BU_SG_REL_ Frontradar SG_ 289 MO_QBit_Fahrpedalwerte_01 500;
BA_REL_ "GenSigTimeoutTime" BU_SG_REL_ Frontradar SG_ 289 MO_Sig_Fahrpedalgradient 500;
BA_REL_ "GenSigTimeoutTime" BU_SG_REL_ Frontradar SG_ 289 MO_Solldrehz_Leerlauf 500;
BA_REL_ "GenSigTimeoutTime" BU_SG_REL_ Frontradar SG_ 289 TSK_a_Soll_gradientenbegrenzt 500;
BA_REL_ "GenSigTimeoutTime" BU_SG_REL_ Frontradar SG_ 283 MO_Fahrbereitschaft 1000;
BA_REL_ "GenSigTimeoutTime" BU_SG_REL_ Frontradar SG_ 1601 Motor_Code_01_CRC 5000;
BA_REL_ "GenSigTimeoutTime" BU_SG_REL_ Frontradar SG_ 1601 Motor_Code_01_BZ 5000;
BA_REL_ "GenSigTimeoutTime" BU_SG_REL_ Frontradar SG_ 1601 MO_Leistung 5000;
BA_REL_ "GenSigTimeoutTime" BU_SG_REL_ Frontradar SG_ 1601 TSK_Codierung 5000;
BA_REL_ "GenSigTimeoutTime" BU_SG_REL_ Frontradar SG_ 2527679498 Perso_Kontonummer 5000;
BA_REL_ "GenSigTimeoutTime" BU_SG_REL_ Frontradar SG_ 2527679498 Perso_Steuerung 5000;
BA_REL_ "GenSigTimeoutTime" BU_SG_REL_ Frontradar SG_ 2527679498 Perso_Steuerungsparameter 5000;
BA_REL_ "GenSigTimeoutTime" BU_SG_REL_ Frontradar SG_ 2527679498 Perso_Status 5000;
BA_REL_ "GenSigTimeoutTime" BU_SG_REL_ Frontsensorik SG_ 929 PSD_Pos_Segment_ID 1500;
BA_REL_ "GenSigTimeoutTime" BU_SG_REL_ Frontsensorik SG_ 929 PSD_Pos_Segmentlaenge 1500;
BA_REL_ "GenSigTimeoutTime" BU_SG_REL_ Frontsensorik SG_ 929 PSD_Pos_Inhibitzeit 1500;
BA_REL_ "GenSigTimeoutTime" BU_SG_REL_ Frontsensorik SG_ 929 PSD_Pos_Standort 1500;
BA_REL_ "GenSigTimeoutTime" BU_SG_REL_ Frontsensorik SG_ 929 PSD_Pos_Laengsfehler 1500;
BA_REL_ "GenSigTimeoutTime" BU_SG_REL_ Frontsensorik SG_ 929 PSD_Segment_ID 1500;
BA_REL_ "GenSigTimeoutTime" BU_SG_REL_ Frontsensorik SG_ 929 PSD_Vorgaenger_Segment_ID 1500;
BA_REL_ "GenSigTimeoutTime" BU_SG_REL_ Frontsensorik SG_ 929 PSD_Strassenklasse 1500;
BA_REL_ "GenSigTimeoutTime" BU_SG_REL_ Frontsensorik SG_ 929 PSD_Segmentlaenge 1500;
BA_REL_ "GenSigTimeoutTime" BU_SG_REL_ Frontsensorik SG_ 929 PSD_Rampe 1500;
BA_REL_ "GenSigTimeoutTime" BU_SG_REL_ Frontsensorik SG_ 929 PSD_Endkruemmung 1500;
BA_REL_ "GenSigTimeoutTime" BU_SG_REL_ Frontsensorik SG_ 929 PSD_Endkruemmung_Vorz 1500;
BA_REL_ "GenSigTimeoutTime" BU_SG_REL_ Frontsensorik SG_ 929 PSD_Endsteigung 1500;
BA_REL_ "GenSigTimeoutTime" BU_SG_REL_ Frontsensorik SG_ 929 PSD_Endsteigung_Vorz 1500;
BA_REL_ "GenSigTimeoutTime" BU_SG_REL_ Frontsensorik SG_ 929 PSD_ADAS_Qualitaet 1500;
BA_REL_ "GenSigTimeoutTime" BU_SG_REL_ Frontsensorik SG_ 929 PSD_Fahrspuren 1500;
BA_REL_ "GenSigTimeoutTime" BU_SG_REL_ Frontsensorik SG_ 929 PSD_wahrscheinlichster_Pfad 1500;
VAL_ 134 LWI_Sensorstatus 0 "iO" 1 "nicht kalibriert" ;
VAL_ 134 LWI_QBit_Sub_Daten 0 "LWS-Subinfo 'real' (Lenkradwinkelinformation ADS-tauglich) " 1 "LWS-Subinfo 'simuliert' (Lenkradwinkelinformation nicht ADS-tauglich )" ;
VAL_ 134 LWI_QBit_Lenkradwinkel 0 "gültiger Wert" 1 "ausserhalb der Spezifikation" ;
VAL_ 134 LWI_Lenkradwinkel 8190 "Init" 8191 "Fehler" ;
VAL_ 134 LWI_VZ_Lenkradwinkel 0 "positiv_links_von_der_Nullstellung" 1 "negativ" ;
VAL_ 134 LWI_VZ_Lenkradw_Geschw 0 "positiv_links_von_der_Nullstellung" 1 "negativ" ;
VAL_ 134 LWI_Lenkradw_Geschw 510 "Init" 511 "Fehler" ;
VAL_ 917 AFS_Abbiegelicht_li_Anf 0 "Abbiegelicht_aus" 1 "Abbiegelicht_ein" ;
VAL_ 917 AFS_Abbiegelicht_re_Anf 0 "Abbiegelicht_aus" 1 "Abbiegelicht_ein" ;
VAL_ 917 AFS_Abbiegelicht_Dimm_Anf 0 "Dimmung_angefordert" 1 "keine_Dimmung" ;
VAL_ 917 AFS_Verfuegbarkeit_GLW 0 "GLW_nicht_verfuegbar" 1 "GLW_verfuegbar" ;
VAL_ 917 AFS_Status_adaptive_LV 0 "adaptive_Lichtverteilung_aus" 1 "adaptive_Lichtverteilung_an" ;
VAL_ 917 AFS_Fernlicht_li_defekt 0 "Fernlicht_in_Ordnung" 1 "Fernlicht_defekt" ;
VAL_ 917 AFS_Fernlicht_re_defekt 0 "Fernlicht_in_Ordnung" 1 "Fernlicht_defekt" ;
VAL_ 917 AFS_Fernlicht_Status 0 "Fernlicht_aus" 1 "Fernlicht_ein" ;
VAL_ 917 AFS_Lampe 0 "Aus" 1 "Ein" ;
VAL_ 917 LWR_Lampe 0 "LWR Fehlerlampe aus" 1 "LWR Fehlerlampe ein" ;
VAL_ 917 AFS_Fehlertext 0 "kein Text" 1 "AFS ohne Funktion" ;
VAL_ 917 AFS_LED_Blinkmode 0 "kein Blinkmode angefordert" 1 "Blinkmode angefordert" ;
VAL_ 917 LWR_Touristenmodus_aktiv 0 "Touristenmodus inaktiv" 1 "Touristenmodus aktiv" ;
VAL_ 917 AFS_Charisma_FahrPr 0 "keine_Funktion" 1 "Programm_1" 2 "Programm_2" 3 "Programm_3" 4 "Programm_4" 5 "Programm_5" 6 "Programm_6" 7 "Programm_7" 8 "Programm_8" 9 "Programm_9" 10 "Programm_10" 11 "Programm_11" 12 "Programm_12" 13 "Programm_13" 14 "Programm_14" 15 "Programm_15" ;
VAL_ 917 AFS_Charisma_Status 0 "Init" 1 "verfuegbar" 2 "nicht_verfuegbar" 3 "asynchron_durch_Fahrerwunsch" ;
VAL_ 917 AFS_Allwetterlicht 0 "Allwetterlicht_nicht_aktiv" 1 "Allwetterlicht_aktiv" ;
VAL_ 917 LWR_Touristenmodus_verbaut 0 "Touristenmodus_nicht_verbaut" 1 "Touristenmodus_verbaut" ;
VAL_ 917 AFS_adaptive_LV_verbaut 0 "adaptive_Lichtverteilung_nicht_verbaut" 1 "adaptive_Lichtverteilung_verbaut" ;
VAL_ 917 LWR_Reisemodus_Texte 0 "keine_Anzeige" 1 "Umschaltung_auf_Linksverkehr_aktiv" 2 "Umschaltung_auf_Rechtsverkehr_aktiv" ;
VAL_ 917 GLW_Sensor_blockiert 0 "Kamera_Sensor_nicht_blockiert" 1 "Kamera_Sensor_blockiert" ;
VAL_ 917 LWR_Pos_Schrittmotor 254 "Init" 255 "Fehler" ;
VAL_ 917 LWR_Hoehenwert_VL 254 "nicht_initialisiert" 255 "Fehler" ;
VAL_ 917 LWR_Hoehenwert_HL 254 "nicht_initialisiert" 255 "Fehler" ;
VAL_ 917 AFS_Ersatzlicht_Links 0 "keine Ersatzlichtfunktion links" 1 "Ersatzlichtfunktion links" ;
VAL_ 917 AFS_Ersatzlicht_Rechts 0 "keine Ersatzlichtfunktion rechts" 1 "Ersatzlichtfunktion rechts" ;
VAL_ 917 LWR_AFS_Grundeinstellung 0 "Grundeinstellung nicht erfolgt" 1 "Grundeinstellung erfolgt" ;
VAL_ 917 LWR_AFS_Parametrisierung 0 "Parametrisierung nicht erfolgt" 1 "Parametrisierung erfolgt" ;
VAL_ 917 LWR_Initialisierungslauf 0 "Initialisierungslauf nicht erfolgt" 1 "Initialisierungslauf erfolgt" ;
VAL_ 917 LWR_Sicherheitsposition 0 "Sicherheitsposition aus" 1 "Sicherheitsposition ein" ;
VAL_ 917 LWR_Modus 0 "LWR statisch" 1 "LWR dynamisch" ;
VAL_ 295 LWR_Verstellwinkel_li 62 "Init" 63 "Fehler" ;
VAL_ 295 LWR_Verstellwinkel_re 62 "Init" 63 "Fehler" ;
VAL_ 295 AFS_Schwenkwinkel_li 254 "Init" 255 "Fehler" ;
VAL_ 295 AFS_Schwenkwinkel_re 254 "Init" 255 "Fehler" ;
VAL_ 295 AFS_Lichtverteilung_li 0 "kein_Licht" 1 "Stadtlicht" 2 "Landstrassenlicht" 3 "Autobahnlicht" 4 "GLW_Stufe_1" 5 "GLW_Stufe_2" 6 "GLW_Stufe_3" 7 "GLW_Stufe_4" 8 "GLW_Stufe_10" 9 "GLW_Stufe_15" 10 "GLW_Stufe_20" 11 "GLW_Stufe_24" 12 "Fernlicht" 13 "vHDG" 14 "Init" 15 "Fehler" ;
VAL_ 295 AFS_Lichtverteilung_re 0 "kein_Licht" 1 "Stadtlicht" 2 "Landstrassenlicht" 3 "Autobahnlicht" 4 "GLW_Stufe_1" 5 "GLW_Stufe_2" 6 "GLW_Stufe_3" 7 "GLW_Stufe_4" 8 "GLW_Stufe_10" 9 "GLW_Stufe_15" 10 "GLW_Stufe_20" 11 "GLW_Stufe_24" 12 "Fernlicht" 13 "vHDG" 15 "Fehler" ;
VAL_ 295 AFS_Status_Verkehrsart 0 "Rechtsverkehr" 1 "Linksverkehr" ;
VAL_ 295 GLW_Nebelregelung 0 "GLW_Nebelregelung_nicht_aktiv" 1 "GLW_Nebelregelung_aktiv" ;
VAL_ 846 MXB_Status_Seg01 0 "Segment_aus" 1 "Segment_Stufe_1" 2 "Segment_Stufe_2" 3 "Segment_Stufe_3" ;
VAL_ 846 MXB_Status_Seg02 0 "Segment_aus" 1 "Segment_Stufe_1" 2 "Segment_Stufe_2" 3 "Segment_Stufe_3" ;
VAL_ 846 MXB_Status_Seg03 0 "Segment_aus" 1 "Segment_Stufe_1" 2 "Segment_Stufe_2" 3 "Segment_Stufe_3" ;
VAL_ 846 MXB_Status_Seg04 0 "Segment_aus" 1 "Segment_Stufe_1" 2 "Segment_Stufe_2" 3 "Segment_Stufe_3" ;
VAL_ 846 MXB_Status_Seg05 0 "Segment_aus" 1 "Segment_Stufe_1" 2 "Segment_Stufe_2" 3 "Segment_Stufe_3" ;
VAL_ 846 MXB_Status_Seg06 0 "Segment_aus" 1 "Segment_Stufe_1" 2 "Segment_Stufe_2" 3 "Segment_Stufe_3" ;
VAL_ 846 MXB_Status_Seg07 0 "Segment_aus" 1 "Segment_Stufe_1" 2 "Segment_Stufe_2" 3 "Segment_Stufe_3" ;
VAL_ 846 MXB_Status_Seg08 0 "Segment_aus" 1 "Segment_Stufe_1" 2 "Segment_Stufe_2" 3 "Segment_Stufe_3" ;
VAL_ 846 MXB_Status_Seg09 0 "Segment_aus" 1 "Segment_Stufe_1" 2 "Segment_Stufe_2" 3 "Segment_Stufe_3" ;
VAL_ 846 MXB_Status_Seg10 0 "Segment_aus" 1 "Segment_Stufe_1" 2 "Segment_Stufe_2" 3 "Segment_Stufe_3" ;
VAL_ 846 MXB_Status_Seg11 0 "Segment_aus" 1 "Segment_Stufe_1" 2 "Segment_Stufe_2" 3 "Segment_Stufe_3" ;
VAL_ 846 MXB_Status_Seg12 0 "Segment_aus" 1 "Segment_Stufe_1" 2 "Segment_Stufe_2" 3 "Segment_Stufe_3" ;
VAL_ 846 MXB_Status_Seg13 0 "Segment_aus" 1 "Segment_Stufe_1" 2 "Segment_Stufe_2" 3 "Segment_Stufe_3" ;
VAL_ 846 MXB_Status_Seg14 0 "Segment_aus" 1 "Segment_Stufe_1" 2 "Segment_Stufe_2" 3 "Segment_Stufe_3" ;
VAL_ 846 MXB_Status_Seg15 0 "Segment_aus" 1 "Segment_Stufe_1" 2 "Segment_Stufe_2" 3 "Segment_Stufe_3" ;
VAL_ 846 MXB_Status_Seg16 0 "Segment_aus" 1 "Segment_Stufe_1" 2 "Segment_Stufe_2" 3 "Segment_Stufe_3" ;
VAL_ 846 MXB_Status_Seg17 0 "Segment_aus" 1 "Segment_Stufe_1" 2 "Segment_Stufe_2" 3 "Segment_Stufe_3" ;
VAL_ 846 MXB_Status_Seg18 0 "Segment_aus" 1 "Segment_Stufe_1" 2 "Segment_Stufe_2" 3 "Segment_Stufe_3" ;
VAL_ 846 MXB_Status_Seg19 0 "Segment_aus" 1 "Segment_Stufe_1" 2 "Segment_Stufe_2" 3 "Segment_Stufe_3" ;
VAL_ 846 MXB_Status_Seg20 0 "Segment_aus" 1 "Segment_Stufe_1" 2 "Segment_Stufe_2" 3 "Segment_Stufe_3" ;
VAL_ 846 MXB_Status_Seg21 0 "Segment_aus" 1 "Segment_Stufe_1" 2 "Segment_Stufe_2" 3 "Segment_Stufe_3" ;
VAL_ 846 MXB_Status_Seg22 0 "Segment_aus" 1 "Segment_Stufe_1" 2 "Segment_Stufe_2" 3 "Segment_Stufe_3" ;
VAL_ 846 MXB_Status_Seg23 0 "Segment_aus" 1 "Segment_Stufe_1" 2 "Segment_Stufe_2" 3 "Segment_Stufe_3" ;
VAL_ 846 MXB_Status_Seg24 0 "Segment_aus" 1 "Segment_Stufe_1" 2 "Segment_Stufe_2" 3 "Segment_Stufe_3" ;
VAL_ 846 MXB_Status_Seg25 0 "Segment_aus" 1 "Segment_Stufe_1" 2 "Segment_Stufe_2" 3 "Segment_Stufe_3" ;
VAL_ 846 MXB_Status_Seg26 0 "Segment_aus" 1 "Segment_Stufe_1" 2 "Segment_Stufe_2" 3 "Segment_Stufe_3" ;
VAL_ 846 MXB_Status_Seg27 0 "Segment_aus" 1 "Segment_Stufe_1" 2 "Segment_Stufe_2" 3 "Segment_Stufe_3" ;
VAL_ 846 MXB_Status_Seg28 0 "Segment_aus" 1 "Segment_Stufe_1" 2 "Segment_Stufe_2" 3 "Segment_Stufe_3" ;
VAL_ 846 MXB_Status_Seg29 0 "Segment_aus" 1 "Segment_Stufe_1" 2 "Segment_Stufe_2" 3 "Segment_Stufe_3" ;
VAL_ 846 MXB_Status_Seg30 0 "Segment_aus" 1 "Segment_Stufe_1" 2 "Segment_Stufe_2" 3 "Segment_Stufe_3" ;
VAL_ 846 MXB_Status_Seg31 0 "Segment_aus" 1 "Segment_Stufe_1" 2 "Segment_Stufe_2" 3 "Segment_Stufe_3" ;
VAL_ 846 MXB_Status_Seg32 0 "Segment_aus" 1 "Segment_Stufe_1" 2 "Segment_Stufe_2" 3 "Segment_Stufe_3" ;
VAL_ 847 MXB_Status_Seg33 0 "Segment_aus" 1 "Segment_Stufe_1" 2 "Segment_Stufe_2" 3 "Segment_Stufe_3" ;
VAL_ 847 MXB_Status_Seg34 0 "Segment_aus" 1 "Segment_Stufe_1" 2 "Segment_Stufe_2" 3 "Segment_Stufe_3" ;
VAL_ 847 MXB_Status_Seg35 0 "Segment_aus" 1 "Segment_Stufe_1" 2 "Segment_Stufe_2" 3 "Segment_Stufe_3" ;
VAL_ 847 MXB_Status_Seg36 0 "Segment_aus" 1 "Segment_Stufe_1" 2 "Segment_Stufe_2" 3 "Segment_Stufe_3" ;
VAL_ 847 MXB_Status_Seg37 0 "Segment_aus" 1 "Segment_Stufe_1" 2 "Segment_Stufe_2" 3 "Segment_Stufe_3" ;
VAL_ 847 MXB_Status_Seg38 0 "Segment_aus" 1 "Segment_Stufe_1" 2 "Segment_Stufe_2" 3 "Segment_Stufe_3" ;
VAL_ 847 MXB_Status_Seg39 0 "Segment_aus" 1 "Segment_Stufe_1" 2 "Segment_Stufe_2" 3 "Segment_Stufe_3" ;
VAL_ 847 MXB_Status_Seg40 0 "Segment_aus" 1 "Segment_Stufe_1" 2 "Segment_Stufe_2" 3 "Segment_Stufe_3" ;
VAL_ 847 MXB_Status_Seg41 0 "Segment_aus" 1 "Segment_Stufe_1" 2 "Segment_Stufe_2" 3 "Segment_Stufe_3" ;
VAL_ 847 MXB_Status_Seg42 0 "Segment_aus" 1 "Segment_Stufe_1" 2 "Segment_Stufe_2" 3 "Segment_Stufe_3" ;
VAL_ 847 MXB_Status_Seg43 0 "Segment_aus" 1 "Segment_Stufe_1" 2 "Segment_Stufe_2" 3 "Segment_Stufe_3" ;
VAL_ 847 MXB_Status_Seg44 0 "Segment_aus" 1 "Segment_Stufe_1" 2 "Segment_Stufe_2" 3 "Segment_Stufe_3" ;
VAL_ 847 MXB_Status_Seg45 0 "Segment_aus" 1 "Segment_Stufe_1" 2 "Segment_Stufe_2" 3 "Segment_Stufe_3" ;
VAL_ 847 MXB_Status_Seg46 0 "Segment_aus" 1 "Segment_Stufe_1" 2 "Segment_Stufe_2" 3 "Segment_Stufe_3" ;
VAL_ 847 MXB_Status_Seg47 0 "Segment_aus" 1 "Segment_Stufe_1" 2 "Segment_Stufe_2" 3 "Segment_Stufe_3" ;
VAL_ 847 MXB_Status_Seg48 0 "Segment_aus" 1 "Segment_Stufe_1" 2 "Segment_Stufe_2" 3 "Segment_Stufe_3" ;
VAL_ 847 MXB_Status_Seg49 0 "Segment_aus" 1 "Segment_Stufe_1" 2 "Segment_Stufe_2" 3 "Segment_Stufe_3" ;
VAL_ 847 MXB_Status_Seg50 0 "Segment_aus" 1 "Segment_Stufe_1" 2 "Segment_Stufe_2" 3 "Segment_Stufe_3" ;
VAL_ 847 MXB_Status_Seg51 0 "Segment_aus" 1 "Segment_Stufe_1" 2 "Segment_Stufe_2" 3 "Segment_Stufe_3" ;
VAL_ 847 MXB_Status_Seg52 0 "Segment_aus" 1 "Segment_Stufe_1" 2 "Segment_Stufe_2" 3 "Segment_Stufe_3" ;
VAL_ 847 MXB_Status_Seg53 0 "Segment_aus" 1 "Segment_Stufe_1" 2 "Segment_Stufe_2" 3 "Segment_Stufe_3" ;
VAL_ 847 MXB_Status_Seg54 0 "Segment_aus" 1 "Segment_Stufe_1" 2 "Segment_Stufe_2" 3 "Segment_Stufe_3" ;
VAL_ 847 MXB_Status_Seg55 0 "Segment_aus" 1 "Segment_Stufe_1" 2 "Segment_Stufe_2" 3 "Segment_Stufe_3" ;
VAL_ 847 MXB_Status_Seg56 0 "Segment_aus" 1 "Segment_Stufe_1" 2 "Segment_Stufe_2" 3 "Segment_Stufe_3" ;
VAL_ 847 MXB_Status_Seg57 0 "Segment_aus" 1 "Segment_Stufe_1" 2 "Segment_Stufe_2" 3 "Segment_Stufe_3" ;
VAL_ 847 MXB_Status_Seg58 0 "Segment_aus" 1 "Segment_Stufe_1" 2 "Segment_Stufe_2" 3 "Segment_Stufe_3" ;
VAL_ 847 MXB_Status_Seg59 0 "Segment_aus" 1 "Segment_Stufe_1" 2 "Segment_Stufe_2" 3 "Segment_Stufe_3" ;
VAL_ 847 MXB_Status_Seg60 0 "Segment_aus" 1 "Segment_Stufe_1" 2 "Segment_Stufe_2" 3 "Segment_Stufe_3" ;
VAL_ 1721 MXB_Status 0 "Gesamtes_Fernlicht_aus" 1 "mindesten_ein_Fernlichtsegment_an" 2 "Init" 3 "Fehler" ;
VAL_ 1721 AFS_Abblendlicht_li_defekt 0 "Abblendlicht_in_Ordnung" 1 "Abblendlicht_defekt" ;
VAL_ 1721 AFS_Abblendlicht_re_defekt 0 "Abblendlicht_in_Ordnung" 1 "Abblendlicht_defekt" ;
VAL_ 1721 AFS_stat_Kurvenlicht_li_defekt 0 "stat_Kurvenlicht_in_Ordnung" 1 "stat_Kurvenlicht_defekt" ;
VAL_ 1721 AFS_stat_Kurvenlicht_re_defekt 0 "stat_Kurvenlicht_in_Ordnung" 1 "stat_Kurvenlicht_defekt" ;
VAL_ 1721 AFS_Tagfahrlicht_li_defekt 0 "Tagfahrlicht_in_Ordnung" 1 "Tagfahrlicht_defekt" ;
VAL_ 1721 AFS_Tagfahrlicht_re_defekt 0 "Tagfahrlicht_in_Ordnung" 1 "Tagfahrlicht_defekt" ;
VAL_ 1721 MXB_Allgemein_li_defekt 0 "kein_Fehler" 1 "Fehler" ;
VAL_ 1721 MXB_Allgemein_re_defekt 0 "kein_Fehler" 1 "Fehler" ;
VAL_ 1721 AFS_Zusatzfernlicht_li_defekt 0 "Zusatzfernlicht_links_in_Ordnung" 1 "Zusatzfernlicht_links_defekt" ;
VAL_ 1721 AFS_Zusatzfernlicht_re_defekt 0 "Zusatzfernlicht_rechts_in_Ordnung" 1 "Zusatzfernlicht_rechts_defekt" ;
VAL_ 1721 LED_Steuerung_li_defekt 0 "Steuerung_nicht_defekt" 1 "Steuerung_defekt" ;
VAL_ 1721 LED_Steuerung_re_defekt 0 "Steuerung_nicht_defekt" 1 "Steuerung_defekt" ;
VAL_ 506 LCM_TFL_Fehler_L 0 "kein_Fehler" 1 "Fehler" ;
VAL_ 506 LCM_TFL_Fehler_R 0 "kein_Fehler" 1 "Fehler" ;
VAL_ 506 LCM_SM_Fehler_L 0 "kein_Fehler" 1 "Fehler" ;
VAL_ 506 LCM_SM_Fehler_R 0 "kein_Fehler" 1 "Fehler" ;
VAL_ 506 LCM_Shutter_Fehler_L 0 "kein_Fehler" 1 "Fehler" ;
VAL_ 506 LCM_Shutter_Fehler_R 0 "kein_Fehler" 1 "Fehler" ;
VAL_ 506 LCM_PO_Fehler_L 0 "kein_Fehler" 1 "Fehler" ;
VAL_ 506 LCM_PO_Fehler_R 0 "kein_Fehler" 1 "Fehler" ;
VAL_ 506 LCM_Blinker_Fehler_L 0 "kein_Fehler" 1 "Fehler" ;
VAL_ 506 LCM_Blinker_Fehler_R 0 "kein_Fehler" 1 "Fehler" ;
VAL_ 506 LCM_Blinker_L_Sta 0 "Blinker_aus" 1 "Blinker_an" ;
VAL_ 506 LCM_Blinker_R_Sta 0 "Blinker_aus" 1 "Blinker_an" ;
VAL_ 506 LCM_Datensatz_Fehler_L 0 "kein_Fehler" 1 "Fehler" ;
VAL_ 506 LCM_Datensatz_Fehler_R 0 "kein_Fehler" 1 "Fehler" ;
VAL_ 506 LCM_Abschaltbestaetigung_L 0 "Init_Default" 1 "Abschaltung_nicht_moeglich" 2 "Abschaltung_moeglich" 3 "Fehler" ;
VAL_ 506 LCM_Abschaltbestaetigung_R 0 "Init_Default" 1 "Abschaltung_nicht_moeglich" 2 "Abschaltung_moeglich" 3 "Fehler" ;
VAL_ 506 LCM_Sta_LM_L_alt 0 "aktuell" 1 "veraltet" ;
VAL_ 506 LCM_Sta_LM_R_alt 0 "aktuell" 1 "veraltet" ;
VAL_ 506 LCM_Feh_LM_L_alt 0 "aktuell" 1 "veraltet" ;
VAL_ 506 LCM_Feh_LM_R_alt 0 "aktuell" 1 "veraltet" ;
VAL_ 1153 DSSS_Warning 0 "No_Warning" 1 "Red_traffic_light_guidance" 2 "Stop_sign_warning" 3 "Rear_end_collision_avoidance_warning" 4 "Intersection_collision_avoidance_warning_right" 5 "Intersection_collision_avoidance_warning_left" 6 "turn_right_collision_avoidance" 7 "turn_left_collision_avoidance" 8 "pedestrian_crossing_right" 9 "pedestrian_crossing_left" 10 "bicycle_collision_right" 11 "bicycle_collision_left" ;
VAL_ 1153 ZR_Kindersicherung_RSE 0 "inaktiv" 1 "aktiv" ;
VAL_ 1153 ZR_RSE_aktivieren 0 "inaktiv" 1 "aktiv" ;
VAL_ 1153 MMI_SDS_aktiv 0 "inaktiv" 1 "aktiv" ;
VAL_ 1153 MU_SecondDisplay 0 "Init" 1 "gueltige_Karte" 2 "ungueltiges_Signal" 3 "Nicht_Verbaut" ;
VAL_ 1153 MMI_Gurt_Mic_ref 0 "Downlink_inaktiv" 1 "Downlink_aktiv" ;
VAL_ 1153 ZR_Parken_Sondermodus 0 "Init" 1 "Sondermodus_aktiv" 2 "Sondermodus_nicht_verfuegbar" 3 "WLAN_aus" 4 "WLAN_auscodiert" 15 "keine_WLAN_HW" ;
VAL_ 1600 MO_QBit_Ansaugluft_Temp 0 "gueltiger_Wert" 1 "Ersatz_Init_oder_Fehlerwert" ;
VAL_ 1600 MO_QBit_Oel_Temp 0 "gueltiger_Wert" 1 "Ersatz_Init_oder_Fehlerwert" ;
VAL_ 1600 MO_QBit_Kuehlmittel_Temp 0 "gueltiger_Wert" 1 "Ersatz_Init_oder_Fehlerwert" ;
VAL_ 1600 MO_KL15_Abschaltempfehlung 0 "Keine Empfehlung" 1 "Abschaltempfehlung" ;
VAL_ 1600 MO_HYB_Fehler_HV_Netz 0 "i_O" 1 "kein_generatorischer_Betrieb_moeglich" ;
VAL_ 1600 MO_aktives_Getriebeheizen 0 "kein_Ventil_ansteuern" 1 "Ventil_muss_angesteuert_werden" ;
VAL_ 1600 MO_Absperrventil_oeffnen 0 "nicht_verfuegbar" 1 "Ansteuerung_Ventil_zulaessig" 2 "Ventil_oeffnen_oder_geoeffnet" 3 "Ventil_schliessen_oder_geschlossen" ;
VAL_ 1600 MO_Ansaugluft_Temp 254 "Init" 255 "Fehler" ;
VAL_ 1600 MO_Oel_Temp 253 "nicht_verbaut" 254 "Init" 255 "Fehler" ;
VAL_ 1600 MO_Kuehlmittel_Temp 254 "Init" 255 "Fehler" ;
VAL_ 1600 MO_Hoeheninfo 255 "Fehler" ;
VAL_ 1600 MO_Kennfeldk 0 "keine Kennfeldkühlung vorhanden" 1 "Kennfeldkühlung vorhanden" ;
VAL_ 1600 MO_Versionsinfo_02 0 "zum_Projektbeginn_aufgeraeumter_CAN" 1 "Motor_03_mit_10ms" 16 "MQB_mit_neuer_Momentenschnittstelle" ;
VAL_ 1600 MO_QBit_Hoeheninfo 0 "gueltiger_Wert" 1 "Ersatz_Init_oder_Fehlerwert" ;
VAL_ 1600 MO_Getriebe_kuehlen 0 "nicht_kuehlen" 1 "kuehlen" ;
VAL_ 1600 MO_Heizungspumpenansteuerung 13 "Fehler" 14 "Init" 15 "nicht_verbaut" ;
VAL_ 1600 MO_SpannungsAnf 0 "keine_Anforderung" 1 "Anforderung" ;
VAL_ 958 MO_StartStopp_Status 0 "System_in_diesem_KL15_Zyklus_nicht_verfuegbar" 1 "System_aktiv_keine_Freigabe_durch_StartStop_Koordinator" 2 "System_aktiv_alle_Freigaben_liegen_vor" 3 "System_aktiv_mindestens_eine_Freigabe_fehlt" ;
VAL_ 958 MO_StartStopp_Wiederstart 0 "Wiederstart_inaktiv" 1 "Wiederstart_aktiv" ;
VAL_ 958 MO_StartStopp_Motorstopp 0 "Motor_Stop_inaktiv" 1 "Motor_Stop_aktiv" ;
VAL_ 958 MO_Freig_Reku 0 "Rekuperations-Modus aus" 1 "Empfehlung Spannungsanhebung" 2 "Empfehlung Spannungsabsenkung" 3 "Rekuperationsmodus aktiv, Spannungsvariation nicht notwendig" ;
VAL_ 958 MO_Kl_75 0 "Aus" 1 "Ein" ;
VAL_ 958 MO_Kl_50 0 "aus" 1 "KL50_ein_Startausfuehrung_Fahrer" ;
VAL_ 958 MO_Gangposition 0 "Gang_N" 1 "Gang_1" 2 "Gang_2" 3 "Gang_3" 4 "Gang_4" 5 "Gang_5" 6 "Gang_6" 7 "Gang_7" 8 "Gang_8" 9 "Automat_P" 10 "Automat_Vorwaerts_S" 11 "Automat_Vorwaerts_D/E" 12 "Zwischenstellung" 13 "Gang_R" 14 "Istgang_nicht_definiert" 15 "Fehler" ;
VAL_ 958 MO_StartStopp_Fahrerwunsch 0 "Init" 1 "Stoppverbot_durch_Fahrer" 2 "Stoppfreigabe_durch_Fahrer" 3 "Stoppanforderung_durch_Fahrer" ;
VAL_ 958 MO_HYB_Fahrbereitschaft 0 "keine_Fahrbereitschaft" 1 "Fahrbereitschaft" ;
VAL_ 958 MO_Ext_E_Fahrt_aktiv 0 "Rueckmeldung_E_Taster_aus" 1 "Rueckmeldung_E_Taster_ein" ;
VAL_ 958 MO_Fahrer_bremst 0 "kein_Bremsen" 1 "Bremse_betaetigt" ;
VAL_ 958 MO_QBit_Fahrer_bremst 0 "gueltiger_Wert" 1 "Ersatz_Init_oder_Fehlerwert" ;
VAL_ 958 MO_BLS 0 "kein_Bremsen" 1 "Bremse_betaetigt" ;
VAL_ 958 MO_Konsistenz_Bremsped 0 "Bremspedalinformation_plausibel" 1 "Bremspedalinformation_unplausibel" ;
VAL_ 958 MO_Timeout_ESP 0 "Empfang_iO" 1 "Timeout" ;
VAL_ 958 MO_Klima_Eingr 0 "kein Eingriff" 1 "Klimakompressor ausschalten" 2 "Klimakompressor Leistungsreduzierung" 3 "Klimakompressor aufgrund der Heissleuchtenvorwarnung ausschalten" ;
VAL_ 958 MO_Aussp_Anlass 0 "Anlasser_darf_angesteuert_werden" 1 "Anlasser_ausspuren__Ansteuerung_nicht_moeglich" ;
VAL_ 958 MO_Freig_Anlass 0 "Start_nicht_zulaessig" 1 "Startfreigabe" ;
VAL_ 958 MO_Kuppl_schalter 0 "Schalter_sagt_ausgekuppelt" 1 "Schalter_sagt_eingekuppelt" ;
VAL_ 958 MO_Interlock 0 "Interlockschalter_nicht_betaetigt" 1 "Interlockschalter_betaetigt" ;
VAL_ 958 MO_Motor_laeuft 0 "Motor_laeuft_nicht" 1 "Motor_laeuft_autark_und_stabil_und_darf_mechanisch_belastet_werden" ;
VAL_ 958 MO_Kickdown 0 "kein_Kickdown" 1 "Kickdown" ;
VAL_ 958 MO_QBit_KL_75 0 "gueltiger_Wert" 1 "Ersatz_Init_oder_Fehlerwert" ;
VAL_ 958 MO_EKlKomLeiRed 0 "keine_Leistungsbegr" 1 "Leistungsbegr_75" 2 "Leistungsbegr_50" 3 "Leistungsbegr_25" ;
VAL_ 958 MO_Handshake_STH 0 "keine EKP-Ansteuerung durch STH-Anforderung" 1 "EKP-Ansteuerung durch STH-Anforderung" ;
VAL_ 958 MO_BKV_Unterdruckwarnung 0 "Unterdruckhaushalt_iO" 1 "Unterdruckhaushalt_niO" ;
VAL_ 958 MO_Freigabe_Segeln 0 "Segelbetrieb_nicht_freigegeben" 1 "Segelbetrieb_freigegeben" ;
VAL_ 958 MO_PTC_Status 0 "nicht_unterstuetzt" 1 "Stufe_0" 2 "Stufe_1" 3 "Stufe_2" 4 "Stufe_3" ;
VAL_ 958 MO_QBit_Gangposition 0 "gueltiger_Wert" 1 "Ersatz_Init_oder_Fehlerwert" ;
VAL_ 958 MO_Signalquelle_Gangposition 0 "Sensorsignal" 1 "Modellsignal" ;
VAL_ 958 MO_Remotestart_Betrieb 0 "MSG_nicht_bereit_fuer_RS_Betrieb" 1 "MSG_bereit_fuer_oder_im_RS_Betrieb" ;
VAL_ 958 MO_Remotestart_moeglich 0 "Remotestart_nicht_moeglich" 1 "Remotestart_moeglich" ;
VAL_ 958 MO_FMAus_aktiv 0 "inaktiv" 1 "Segeln_mit_Motor_aus_aktiv" ;
VAL_ 958 MO_FMAus_Startvariante 0 "kein_Motorstart" 1 "Motorstart_elektrischer_Starter" 2 "GetriebeAnschleppstart" 3 "GetriebeNotAnschleppstart" ;
VAL_ 958 MO_BMS_NV_Anf_stuetzen 0 "nicht_notwendig" 1 "notwendig" ;
VAL_ 958 MO_Zylinderabschaltung 0 "Vollmotorbetrieb_VMB" 1 "Uebergang_HMB_in_VMB" 2 "Uebergang_VMB_in_HMB" 3 "Halbmotorbetrieb_HMB" ;
VAL_ 958 MO_HYB_VM_aktiv 0 "VM_nicht_aktiv" 1 "VM_aktiv" ;
VAL_ 958 MO_StartVorauss_erfuellt 0 "Signal_nicht_bedient" 1 "StartVorauss_nicht_ueberpruefbar" 2 "StartVorauss_nicht_erfuellt" 3 "StartVorauss_erfuellt" ;
VAL_ 1631 TSK_QBit_Steigung 0 "gueltiger_Wert" 1 "Ersatz_Init_oder_Fehlerwert" ;
VAL_ 1631 TSK_QBit_Fahrzeugmasse 0 "gueltiger_Wert" 1 "Ersatz_Init_oder_Fehlerwert" ;
VAL_ 1631 MO_SpannungsAnf_02 0 "keine_Anforderung" 1 "Anforderung_Stufe_1" 2 "Anforderung_Stufe_2" 3 "Anforderung_Stufe_3" ;
VAL_ 1631 MO_DPF_reg 0 "DPF_regeneriert_nicht" 1 "DPF_regeneriert" ;
VAL_ 1631 MO_Heizstrom_EKAT 127 "Fehler" ;
VAL_ 1631 MO_Heizstrom_SCR 63 "Fehler" ;
VAL_ 1631 MO_Testmode_AG 0 "kein_Pruefstandsbetrieb" 1 "Pruefstandsbetrieb" ;
VAL_ 1631 TSK_Getriebeinfo 0 "Handschalter" 1 "AL_AQ_Getriebe" 2 "DL_DQ_Getriebe" 3 "CVT_Getriebe" ;
VAL_ 1631 MO_Energieinhalt_BMS 4094 "Init" 4095 "Fehler" ;
VAL_ 1631 TSK_Fahrzeugmasse_02 255 "Fehler" ;
VAL_ 1631 TSK_Steigung_02 0 "Init_oder_nicht_verbaut" 255 "Fehler" ;
VAL_ 1648 MO_ANC_Kennfeld_Anf 0 "Kennfeld_1" 1 "Uebergang_Kennfeld_2_nach_1" 2 "Uebergang_Kennfeld_1_nach_2" 3 "Kennfeld_2" ;
VAL_ 1648 MO_Bremslicht_Reku 0 "Aus" 1 "Ein" ;
VAL_ 1648 MO_StartStopp_PopUp 0 "Statuswechsel_ohne_Taster (Init)" 1 "StSt_per_Taster_deaktiviert" 2 "StSt_per_Taster_aktiviert" 3 "nicht verwendet" ;
VAL_ 1648 MO1_Sperr_Info_WFS 0 "nicht_gesperrt" 1 "gesperrt" ;
VAL_ 1648 MO1_Freigabe_Info_WFS 0 "ungueltig" 1 "gueltig" ;
VAL_ 1648 MO_EPCL 0 "EPCL_aus_kein_Text" 1 "EPCL_gelb_Stoerung" 2 "EPCL_gelb_Leistungsbeschraenkung" 3 "EPCL_rot_Fzg_sicher_abstellen" ;
VAL_ 1648 MO_Zylabsch_Texte_02 0 "ein_ZAS_generell_keine_ZAS_Anzeigen" 1 "ZAS_im_VMB" 2 "ZAS_im_ASB_1_Zyl_aktiv" 3 "ZAS_im_ASB_2_Zyl_aktiv" 4 "ZAS_im_ASB_3_Zyl_aktiv" 5 "ZAS_im_ASB_4_Zyl_aktiv" 6 "ZAS_im_ASB_5_Zyl_aktiv" 7 "ZAS_im_ASB_6_Zyl_aktiv" 8 "ZAS_im_ASB_8_Zyl_aktiv" 9 "ZAS_im_ASB_12_Zyl_aktiv" 13 "Uebergangsbetrieb" 14 "keine_ZAS_Anzeige_ggf_Stopp_Schub_Betrieb" 15 "ZAS_Stoerungs_Anzeige" ;
VAL_ 1648 MO_Fahrzeugtyp 0 "Verbrenner_Fahrzeug" 1 "Hybrid" 2 "E_Fahrzeug" 3 "E_Fahrzeug_mit_Range_Extender" 4 "tbd" 5 "tbd" 6 "tbd" 7 "tbd" ;
VAL_ 1648 MO_Abstellzeit 254 "reserviert" 255 "reserviert" ;
VAL_ 1648 MO_Abstellzeit_Status 0 "Abstellzeit_nicht_berechnet" 1 "Abstellzeit_berechnet" 2 "Abstellzeit_Minimalwert" 3 "Abstellzeit_ungueltig" ;
VAL_ 1648 MO1_Freigabe_Verfallsinfo_WFS 0 "verfaellt_nicht" 1 "verfaellt" ;
VAL_ 1648 MO_Hybrid_StartStopp_LED 0 "LED_aus_und_Blinken_aus" 1 "LED_ein_und_Blinken_aus" 2 "LED_ein_und_Blinken_ein_50_percent" 3 "reserviert" ;
VAL_ 1648 MO_Fehler_Zylabsch 0 "kein_Fehler" 1 "Notlauf_Vollmotorbetrieb" 2 "Notlauf_mindestens_einem_abgesch_Zylinder" ;
VAL_ 1648 MO_Anzahl_Abgesch_Zyl 0 "Vollmotorbetrieb" 1 "1_Zylinder_abgeschaltet" 2 "2_Zylinder_abgeschaltet" 3 "3_Zylinder_abgeschaltet" 4 "4_Zylinder_abgeschaltet" 5 "5_Zylinder_abgeschaltet" 6 "6_Zylinder_abgeschaltet" 7 "8_Zylinder_abgeschaltet" ;
VAL_ 1648 MO_Zylabsch_Texte 0 "keine_Texte" 1 "Zylinderabschaltung_deaktivieren" 2 "Zylinderabschaltung_aktivieren" 3 "Zylinderabschaltung_unruhig" ;
VAL_ 1648 MO_Ethanol_BS_Texte 0 "kein_Text" 1 "E85_Warm_Up" 2 "FlexFuel_Warnung_Stufe_3" 3 "Warmfahrempfehlung_MQB__FlexFuel_Warnung_Stufe_1" 4 "FlexFuel_Warnung_Stufe_2" 5 "FlexFuel_Warnung_Stufe_4" 6 "E25_Warm_Up" ;
VAL_ 1648 MO_Drehzahl_Warnung 0 "keinen_Warnhinweis_anzeigen" 1 "Warnhinweis_anzeigen" ;
VAL_ 1648 MO_obere_Drehzahlgrenze 0 "Init" ;
VAL_ 289 MO_Fahrpedalrohwert_01 255 "Fehler" ;
VAL_ 289 MO_QBit_Fahrpedalwerte_01 0 "gueltiger_Wert" 1 "Ersatz_Init_oder_Fehlerwert" ;
VAL_ 289 MO_Fahrpedalgradient 255 "Fehler" ;
VAL_ 289 MO_Sig_Fahrpedalgradient 0 "Fahrpedalgradient positiv" 1 "Fahrpedalgradient negativ" ;
VAL_ 289 MO_rel_Saugrohrdruck 0 "Init_Ueberdruck" 63 "Fehler" ;
VAL_ 289 MO_rel_Saugrohrdruck_gem_err 0 "errechnet" 1 "gemessen" ;
VAL_ 289 MO_Moment_im_Leerlauf 0 "kein_Leergas" 1 "Leergas" ;
VAL_ 289 MO_Schubabschaltung 0 "keine_Schubabschaltung" 1 "Schubabschaltung_aktiv" ;
VAL_ 289 MO_StartStopp_StoppVorbereitung 0 "Motorstopp_nicht_in_Vorbereitung" 1 "Motorstopp_in_Vorbereitung" ;
VAL_ 289 MO_Entkopplung_Sollschlupf 125 "Notoeffnen_Anfahrelement" 126 "Init" ;
VAL_ 289 MO_temporaere_Fahrerabwesenheit 0 "nicht_erkannt" 1 "erkannt" ;
VAL_ 289 TSK_a_Soll_gradientenbegrenzt 127 "Init_oder_nicht_aktiv" ;
VAL_ 283 MO_Fahrbereitschaft 0 "Fahrzykl_inaktiv__kein_Antrieb" 1 "Fahrzykl_aktiv__kein_Antrieb" 2 "Fahrzykl_aktiv__Antrieb_moeglich" ;
VAL_ 283 MO_Freilauf_Info 0 "Freilauf_freigegeben" 1 "Uebergang_in_Freilauf_unzulaessig" 2 "Freilauf_nicht_freigegeben_Abbruch" 3 "Freilauf_Anforderung" ;
VAL_ 283 MO_EnergyAssist_Aktivierbar 0 "AEA_nicht_aktivierbar" 1 "AEA_aktivierbar" ;
VAL_ 283 MO_Krit_Heckobjekt 0 "Init_kein_relevantes_Objekt" 1 "Entfernung_grosser_Abstand" 2 "Annaeherung_grosser_Abstand" 3 "Entfernung_geringer_Abstand" 4 "Annaeherung_geringer_Abstand" 7 "Fehler" ;
VAL_ 283 MO_NGS_Gangpos 0 "nicht_bedient" 1 "1_3_oder_5" 2 "2_4_6_oder_R" 3 "R" 4 "Neutralposition" 5 "Zwischenposition" 6 "Sensor_temp_nicht_verfuegbar" 7 "Fehler" ;
VAL_ 1601 MO_Faktor_Momente_02 0 "nicht_belegt" ;
VAL_ 1601 MO_Hybridfahrzeug 0 "kein_Hybridfahrzeug" 1 "Mild_Hybrid" 2 "Full_Hybrid" 3 "PlugIn_Hybrid" ;
VAL_ 1601 MO_Getriebe_Code 0 "Init" 2 "DL501" 3 "DL800" 4 "VL381" 5 "DL382_Front" 6 "DL382_Allrad" 7 "DL702" 8 "AL552_Allrad" 9 "AL552_Front" 10 "AL651" 11 "AL551__AL951__AL1000_8A" 12 "PDK_PAG" 13 "AL551_Hybrid" 15 "Handschalter_konventionell" 16 "AQ250_160" 17 "AQ450" 18 "DQ200" 19 "DQ250" 20 "DQ500" 21 "SQ100" 22 "SQ200" 23 "DQ400E" 24 "DQ381" 25 "AL450" 31 "DL800E" 32 "Single_Gear__ohne_GSG_WH_am_MSG" ;
VAL_ 1601 MO_StartStopp_Codiert 0 "Start_Stopp_nicht_verbaut" 1 "Start_Stopp_verbaut" ;
VAL_ 1601 MO_Anzeige_StSt_gueltig 0 "MO_Text_Motorstart_gueltig" 1 "Signale_MO_Anzeige_StSt_gueltig" ;
VAL_ 1601 MO_Anzahl_Zyl 0 "kein_Zylinder" 1 "1_Zylinder" 2 "2_Zylinder" 3 "3_Zylinder" 4 "4_Zylinder" 5 "5_Zylinder" 6 "6_Zylinder" 7 "7_Zylinder" 8 "8_Zylinder" 9 "9_Zylinder" 10 "10_Zylinder" 11 "11_Zylinder" 12 "12_Zylinder" 13 "15_Zylinder" 14 "16_Zylinder" 15 "18_Zylinder" ;
VAL_ 1601 MO_Kraftstoffart 0 "Diesel" 1 "Benzin_inkl_E25_E85" 2 "CNG" 3 "LPG" 4 "Wasserstoff" 5 "E100_Ethanol" 15 "kein_Verbrennungskraftstoff" ;
VAL_ 1601 MO_Ansaugsystem 0 "Turbo" 1 "Sauger" ;
VAL_ 1601 MO_OBD_Typ 0 "NoOBD_RdW" 1 "EOBD" 2 "US_OBD" 3 "reserviert" ;
VAL_ 1601 MO_DPF_verbaut 0 "kein_DPF_verbaut" 1 "DPF_verbaut" ;
VAL_ 1601 TSK_Codierung 0 "kein_Fahrgeschwindigkeitsregler" 1 "GRA" 2 "GRA_Plus" 3 "Basis_ACC" 4 "ACC_Follow_to_Stop" 5 "ACC_Stop_and_Go" 7 "Codierung_in_Plausibilisierungsphase" ;
VAL_ 2600468496 NM_Gateway_SNI 16 "Gateway" ;
VAL_ 2600468496 NM_Gateway_NM_State 1 "NM_RM_aus_BSM" 2 "NM_RM_aus_PBSM" 4 "NM_NO_aus_RM" 8 "NM_NO_aus_RS" 16 "NM_RM_aus_RS" 32 "NM_RM_aus_NO" ;
VAL_ 2600468496 NM_Gateway_Car_Wakeup 0 "Inaktiv" 1 "Car_Wakeup" ;
VAL_ 2600468496 NM_Gateway_Wakeup 0 "Peripherie_Wakeup__Ursache_nicht_bekannt" 1 "Bus_Wakeup" 2 "KL15_HW" 3 "ACAN_Wakeup" 4 "FCAN_Wakeup" 5 "KCAN_Wakeup" 6 "ICAN_Wakeup" 7 "DiagCAN_Wakeup" 8 "ECAN_Wakeup" 9 "Energie_LIN_Wakeup" 10 "Bedien_LIN_Wakeup" 11 "HybridCAN_Wakeup" 12 "Flexray_Wakeup" 13 "MFL_WakeUp" 14 "Ethernet" 15 "DCAN_Wakeup" 16 "K2CAN_Wakeup" 128 "Energiemanagement" 129 "Funktionswakeup_OBDC" 130 "Hochvoltenergiemanagement" 131 "CWU_empfangen" 132 "Fuer_Bus_relevanten_FC_empfangen" 133 "OnlineDienst_empfangen" 134 "HV_Aktivieren" 135 "HV_Deaktivieren" ;
VAL_ 2600468496 NM_Gateway_NM_aktiv_KL15 0 "Inaktiv" 1 "KL15_EIN" ;
VAL_ 2600468496 NM_Gateway_NM_aktiv_Diagnose 1 "Diagnose_aktiv" ;
VAL_ 2600468496 NM_Gateway_NM_aktiv_Tmin 0 "Inaktiv" 1 "Mindestaktivzeit" ;
VAL_ 2600468496 NM_Gateway_ACAN_Aktivitaet 1 "ACAN_Aktivitaet" ;
VAL_ 2600468496 NM_Gateway_FCAN_Aktivitaet 1 "FCAN_Aktivitaet" ;
VAL_ 2600468496 NM_Gateway_KCAN_Aktivitaet 1 "KCAN_Aktivitaet" ;
VAL_ 2600468496 NM_Gateway_ICAN_Aktivitaet 1 "ICAN_Aktivitaet" ;
VAL_ 2600468496 NM_Gateway_DiagCAN_Aktivitaet 1 "DiagCAN_Aktivitaet" ;
VAL_ 2600468496 NM_Gateway_ECAN_Aktivitaet 1 "ECAN_Aktivitaet" ;
VAL_ 2600468496 NM_Gateway_EnergieLIN_Aktivitaet 1 "Energie_LIN_Aktivitaet" ;
VAL_ 2600468496 NM_Gateway_Bedien_LIN_Aktivitaet 1 "Bedien_LIN_Aktivitaet" ;
VAL_ 2600468496 NM_Gateway_EM_Aktivitaet 1 "EM_Aktivitaet" ;
VAL_ 2600468496 NM_Gateway_KS_Aktivitaet 1 "KS_Aktivitaet" ;
VAL_ 2600468496 NM_Gateway_HVEM_aktiv 0 "Init" 1 "Hochvoltenergiemanagement" ;
VAL_ 2600468496 NM_Gateway_NL_EM 1 "Energiemanagement" ;
VAL_ 2600468496 NM_Gateway_NL_Shutdown 1 "Shutdown" ;
VAL_ 2600468496 NM_Gateway_NL_Spg_Messung 1 "Spannungsmessung" ;
VAL_ 2600468496 NM_Gateway_NL_Wakeup_Monitor 1 "Wakeup_Monitor" ;
VAL_ 2600468496 NM_Gateway_UDS_CC 1 "CC_aktiv" ;
VAL_ 2600468564 NM_LWRAFS_SNI 84 "LWRAFS" ;
VAL_ 2600468564 NM_LWRAFS_NM_State 0 "Init" 1 "NM_RM_aus_BSM" 2 "NM_RM_aus_PBSM" 4 "NM_NO_aus_RM" 8 "NM_NO_aus_RS" ;
VAL_ 2600468564 NM_LWRAFS_Car_Wakeup 0 "Inaktiv" 1 "Car_Wakeup" ;
VAL_ 2600468564 NM_LWRAFS_Wakeup 0 "Peripherie_Wakeup__Ursache_nicht_bekannt" 1 "Bus_Wakeup" 2 "KL15_HW" 4 "Versorgungsspannung_aktiv" ;
VAL_ 2600468564 NM_LWRAFS_NM_aktiv_KL15 0 "Inaktiv" 1 "KL15_EIN" ;
VAL_ 2600468564 NM_LWRAFS_NM_aktiv_Diagnose 1 "Diagnose_aktiv" ;
VAL_ 2600468564 NM_LWRAFS_NM_aktiv_Tmin 0 "Inaktiv" 1 "Mindestaktivzeit" ;
VAL_ 2600468564 NM_LWRAFS_NM_aktiv_Versorgung 0 "Init" 1 "Versorgungsspannung_aktiv" ;
VAL_ 2600468564 NM_LWRAFS_UDS_CC 1 "CC_aktiv" ;
VAL_ 1175 PH_Visualisierung 0 "Aus" 1 "Angefragt" 2 "InAnzeige" 3 "Abgefordert" 6 "Init" 7 "Fehler" ;
VAL_ 1175 PDC_Tonausgabe_Front 0 "kein_Ton" 1 "Intervallton_1" 2 "Intervallton_2" 3 "Intervallton_3" 4 "Intervallton_4" 5 "Intervallton_5" 6 "Dauerton" 7 "Fehlerton" 8 "RCTATon" ;
VAL_ 1175 PDC_Tonausgabe_Heck 0 "kein_Ton" 1 "Intervallton_1" 2 "Intervallton_2" 3 "Intervallton_3" 4 "Intervallton_4" 5 "Intervallton_5" 6 "Dauerton" 7 "Fehlerton" 8 "Erstwarnton_hinten" 9 "RCTATon" ;
VAL_ 1175 PH_nachtr_Stopp_Anf 0 "nicht_angefordert" 1 "angefordert" ;
VAL_ 1175 PH_Abschaltursache 0 "keine, bzw. System aktiv" 1 "Abschaltung durch Herausnahme R-Gang" 2 "Abschaltung ueber Geschwindigkeit" 3 "Abschaltung ueber PDC-Taster" 4 "Abschaltung wegen PLA" 5 "Abschaltung durch KL 15 Bit = 0" 6 "tbd." 7 "Fehler-/gestört Zustand, System noch aktiv" ;
VAL_ 1175 PH_Opt_Anzeige_V_ein 0 "optische Anzeige vorne nicht aktiv" 1 "optische Anzeige vorne aktiviert" ;
VAL_ 1175 PH_Opt_Anzeige_H_ein 0 "Optische Anzeige aus" 1 "optische Anzeige hinten aktiviert" ;
VAL_ 1175 PH_Opt_Anz_V_Hindernis 0 "optische Anzeige vorne meldet kein Hindernis" 1 "optische Anzeige vorne meldet Hindernis im Warnbereich" ;
VAL_ 1175 PH_Opt_Anz_H_Hindernis 0 "optische Anzeige hinten meldet kein Hindernis" 1 "optische Anzeige hinten meldet Hindernis im Warnbereich" ;
VAL_ 1175 PH_Tongeber_V_aktiv 0 "Tongeber vorne nicht aktiv" 1 "Tongeber vorne  aktiv" ;
VAL_ 1175 PH_Tongeber_H_aktiv 0 "Tongeber hinten nicht aktiv" 1 "Tongeber hinten aktiv" ;
VAL_ 1175 PH_Tongeber_mute 0 "Tongeber nicht stummgeschaltet" 1 "Tongeber stummgeschaltet" ;
VAL_ 1175 PH_Anf_Audioabsenkung 0 "keine Absenkung der Lautstärke" 1 "Anforderung an das Audiosystem für Absenkung der Lautstärke" ;
VAL_ 1175 PH_Tongeber_H_verfuegbar 0 "nicht verfügbar" 1 "verfügbar" ;
VAL_ 1175 PLA_Anf_Aufschaltung_RVC 0 "Keine_RVC_Aufschalteanf" 1 "RVC_Aufschalteanforderung" ;
VAL_ 1175 PH_Taster 0 "Taster_nicht_gedrueckt" 1 "Taster_gedrueckt" 2 "reserviert" 3 "Fehler" ;
VAL_ 1175 PH_Anf_Verdeck 0 "Verdeckbetrieb_freigegeben" 1 "Verdeckbetrieb_sperren" 2 "reserviert" 3 "reserviert" ;
VAL_ 1175 PH_StartStopp_Info 0 "Motorlauf_nicht_notwendig_(Stoppfreigabe)" 1 "Motoranlauf_nicht_zwingend_notwendig_(Stoppverbot,keine_Startanforderung)" 2 "Motoranlauf_zwingend_notwendig_(Startanforderung)" 3 "Systemfehler" ;
VAL_ 1175 PH_Stoermeldung 0 "keine_Anzeige_kein_Gong" 1 "Textmeldung_PDC_hinten_gestoert_mit_Gong" 2 "Textmeldung_PDC_hinten_gestoert_ohne_Gong" 3 "Textmeldung_PDC_vorn_gestoert_mit_Gong" 4 "Textmeldung_PDC_vorn_gestoert_ohne_Gong" 5 "Textmeldung_PDC_gestoert_mit_Gong" 6 "Textmeldung_PDC_gestoert_ohne_Gong" 7 "Textmeldung_PDC_seitlich_gestoert_mit_Gong" 8 "Textmeldung_PDC_seitlich_gestoert_ohne_Gong" ;
VAL_ 1175 PH_defekt 0 "PH aktiv" 1 "PH wurde aufgrund eines Defektes deaktiviert" ;
VAL_ 1175 PH_gestoert 0 "PH aktiv" 1 "PH wurde auf Grund einer Stoerung tempraer deaktiviert" ;
VAL_ 1175 PH_Systemzustand 0 "Anlage aus" 1 "Anlage durch einlegen R-Gang aktiviert" 2 "Anlage manuell durch Taster aktiviert" 3 "Anlage automatisch aktiviert" 4 "Anlage durch ARA aktiviert" 6 "Init - Initialisierungsphase nach Kl. 15 ein / Reset" 7 "Fehler-/gestört Zustand, System noch aktiv" ;
VAL_ 1175 PH_Display_Kundenwunsch 0 "Anzeige aus" 1 "Grafik" 2 "Rear View" 3 "automatisch" ;
VAL_ 1351 US_Objekt_links 0 "Init" 1 "Objekt_erkannt" 2 "Kein_Objekt_erkannt" ;
VAL_ 1351 US_Objekt_rechts 0 "Init" 1 "Objekt_erkannt" 2 "Kein_Objekt_erkannt" ;
VAL_ 1351 US_Objektueberwachung_Status 0 "Passiv" 1 "Aktiv" 3 "Fehler" ;
VAL_ 2527679498 Perso_Kontonummer 0 "kein_Benutzerkonto" 1 "Benutzerkonto_1" 2 "Benutzerkonto_2" 3 "Benutzerkonto_3" 4 "Benutzerkonto_4" 5 "Benutzerkonto_5" 6 "Benutzerkonto_6" 7 "Benutzerkonto_7" ;
VAL_ 2527679498 Perso_Steuerung 0 "keine_Steuerung" 1 "Reset_alle_Konten" 2 "Reset_aktives_Konto" 3 "Kopiere_aktives_Konto_nach" 4 "Wiederherstellen_aktives_Konto" ;
VAL_ 2527679498 Perso_Steuerungsparameter 0 "kein_Parameter" 1 "Benutzerkonto_1" 2 "Benutzerkonto_2" 3 "Benutzerkonto_3" 4 "Benutzerkonto_4" 5 "Benutzerkonto_5" 6 "Benutzerkonto_6" 7 "Benutzerkonto_7" ;
VAL_ 2527679498 Perso_Status 0 "deaktiviert" 1 "aktiviert" ;
VAL_ 2527679498 Perso_Bedienstelle 0 "Init" 1 "Kombiinstrument" 2 "ABT" ;
VAL_ 2527679498 Perso_Freigabe_Verstellung 0 "Init" 1 "freigegeben" ;
VAL_ 2527679498 Perso_Aktiv 0 "deaktiviert" 1 "aktiviert" ;
VAL_ 929 PSD_Pos_Segment_ID 0 "keine Position gegeben" 1 "Fehlerwert" ;
VAL_ 929 PSD_Pos_Standort 0 "mehrdeutiger_Standort" 1 "eindeutiger_Standort" ;
VAL_ 929 PSD_Pos_Laengsfehler 0 "keine Prädiktion (off-road)" 1 "< 2m" 2 "< 5m" 3 "< 10m " 4 "< 20m" 5 "< 50m" 6 "> 50m " 7 "nicht erlaubt" ;
VAL_ 929 PSD_Segment_ID 0 "keine Segmentinformationen vorhanden" 1 "Fehlerwert" ;
VAL_ 929 PSD_Vorgaenger_Segment_ID 0 "keine Segmentinformation vorhanden" 1 "Fehlerwert" ;
VAL_ 929 PSD_Strassenklasse 0 "Rest_Feldweg_Schotterweg_Privatweg" 1 "Ortsstrasse" 2 "Bundes_Landstrasse" 3 "Autobahn" ;
VAL_ 929 PSD_Rampe 0 "Strasse_mit_Gegenverkehr" 1 "Auffahrt_Einbahnstr" 2 "Abfahrt_Einbahnstr" 3 "Einbahnstrasse" ;
VAL_ 929 PSD_Endkruemmung 255 "Gerade" ;
VAL_ 929 PSD_Endkruemmung_Vorz 0 "Kruemmung_positiv" 1 "Kruemmung_negativ" ;
VAL_ 929 PSD_Endsteigung 30 "gleich_oder_mehr_15_Prozent_Steigung" 31 "nicht_definiert" ;
VAL_ 929 PSD_Endsteigung_Vorz 0 "Gefaelle" 1 "Steigung" ;
VAL_ 929 PSD_ADAS_Qualitaet 0 "keine_ADAS_Qualitaet" 1 "ADAS_Qualitaet" ;
VAL_ 929 PSD_Fahrspuren 0 "Einbahnstrasse_in_falscher_Richtung" 1 "eine_Fahrspur" 2 "zwei_Fahrspuren" 3 "drei_Fahrspuren" ;
VAL_ 929 PSD_wahrscheinlichster_Pfad 0 "Pfad_mit_geringer_Wahrscheinlichkeit" 1 "wahrscheinlichster_Pfad" ;
